VERSION ""

NS_ :

BS_:

BU_: VT TC Sprayer TECU

BO_ 2565340800 VT21_Sprayer: 33 Sprayer
 SG_ UnsupportedVtFunction m253 : 8|8@1+ (1,0) [0|255] "" Vector__XXX
 SG_ AuxiliaryInputID_1 m34 : 120|16@1+ (1,0) [0|65535] "" Vector__XXX
 SG_ AuxiliaryFunctionID_1 m34 : 104|16@1+ (1,0) [0|65535] "" Vector__XXX
 SG_ NumOfPreferredFunctions m34 : 96|8@1- (1,0) [0|255] "" Vector__XXX
 SG_ ModelIdentificationCode m34 : 80|16@1+ (1,0) [0|65535] "" Vector__XXX
 SG_ ArbitraryAddressCapable m34 : 79|1@1+ (1,0) [0|1] "" Vector__XXX
 SG_ IndustryGroup m34 : 76|3@1+ (1,0) [0|7] "" Vector__XXX
 SG_ VehicleSystemInstance m34 : 72|4@1+ (1,0) [0|15] "" Vector__XXX
 SG_ VehicleSystem2 m34 : 65|7@1+ (1,0) [0|127] "" Vector__XXX
 SG_ ZoomValue_PanZoom m16 : 64|32@1- (1,0) [-32|32] "" Vector__XXX
 SG_ OperatingState2 m33 : 57|1@1+ (1,0) [0|1] "" Vector__XXX
 SG_ Function m34 : 56|8@1+ (1,0) [0|255] "" Vector__XXX
 SG_ OperatingState1 m33 : 56|1@1+ (1,0) [0|1] "" Vector__XXX
 SG_ YPosChangeTopLeftLong m180 : 56|16@1- (1,0) [-32768|32767] "" Vector__XXX
 SG_ LineDirection m169 : 56|8@1+ (1,0) [0|1] "" Vector__XXX
 SG_ FunctionInstance m34 : 51|5@1+ (1,0) [0|31] "" Vector__XXX
 SG_ ECUInstance m34 : 48|3@1+ (1,0) [0|7] "" Vector__XXX
 SG_ NewValueY m182 : 48|16@1+ (1,0) [0|65535] "" Vector__XXX
 SG_ GraphicRepresentationObjectID m181 : 48|16@1+ (1,0) [0|255] "" Vector__XXX
 SG_ FontStyle m170 : 48|8@1+ (1,0) [0|255] "" Vector__XXX
 SG_ YPosChangeTopLeft m165 : 48|8@1+ (1,-127) [-127|128] "" Vector__XXX
 SG_ OffTimeDuration_Audio m163 : 48|16@1+ (1,0) [0|65535] "ms" Vector__XXX
 SG_ ButtonKeyCode m1 : 48|8@1+ (1,0) [0|255] "" Vector__XXX
 SG_ SoftKeyCode m0 : 48|8@1+ (1,0) [0|255] "" Vector__XXX
 SG_ Status_2 m9 : 48|8@1+ (1,0) [0|1] "" Vector__XXX
 SG_ NewViewportHeight m17 : 48|16@1+ (1,0) [0|65535] "" Vector__XXX
 SG_ ViewportY_PanZoom m16 : 48|16@1- (1,0) [-32768|32767] "" Vector__XXX
 SG_ ViewportY m14 : 48|16@1- (1,0) [-32768|32767] "" Vector__XXX
 SG_ EllipseHeight m11 : 48|16@1+ (1,0) [0|65535] "" Vector__XXX
 SG_ RectangleHeight_Draw m10 : 48|16@1+ (1,0) [0|65535] "" Vector__XXX
 SG_ EndPixelOffsetY m9 : 48|16@1- (1,0) [-32768|32767] "" Vector__XXX
 SG_ PixelOffsetY m8 : 48|16@1- (1,0) [-32768|32767] "" Vector__XXX
 SG_ CursorOffsetY m1 : 48|16@1- (1,0) [-32768|32767] "" Vector__XXX
 SG_ CursorPosY m0 : 48|16@1- (1,0) [-32768|32767] "" Vector__XXX
 SG_ NewStringValue m179 : 40|16@1+ (1,0) [0|65535] "" Vector__XXX
 SG_ Value2 m33 : 40|16@1+ (1,0) [0|65535] "" Vector__XXX
 SG_ NewHeigthAttribute m183 : 40|16@1+ (1,0) [0|0] "" Vector__XXX
 SG_ FontType m170 : 40|8@1+ (1,0) [0|255] "" Vector__XXX
 SG_ XPosChangeTopLeftLong m180 : 40|16@1- (1,0) [-32768|32767] "" Vector__XXX
 SG_ FillPatternObjectID m172 : 40|16@1+ (1,0) [0|65535] "" Vector__XXX
 SG_ LineArt m171 : 40|16@1+ (1,0) [0|65535] "" Vector__XXX
 SG_ LabelFontType m181 : 40|8@1+ (1,0) [0|255] "" Vector__XXX
 SG_ Height m169 : 40|16@1+ (1,0) [0|65535] "" Vector__XXX
 SG_ NewHeight m166 : 40|16@1+ (1,0) [0|65535] "" Vector__XXX
 SG_ XPosChangeTopLeft m165 : 40|8@1+ (1,-127) [-127|128] "" Vector__XXX
 SG_ TouchState m2 : 40|8@1+ (1,0) [0|255] "" Vector__XXX
 SG_ TextLength m13 : 40|8@1+ (1,0) [0|255] "bytes" Vector__XXX
 SG_ ManufacturerCode m34 : 37|11@1+ (1,0) [0|2047] "" Vector__XXX
 SG_ AuxErrorAnyOther m37 : 33|1@1+ (1,0) [0|1] "" Vector__XXX
 SG_ CursorPosX m0 : 32|16@1- (1,0) [-32768|32767] "" Vector__XXX
 SG_ CursorOffsetX m1 : 32|16@1- (1,0) [-32768|32767] "" Vector__XXX
 SG_ ForegroundColour m2 : 32|8@1+ (1,0) [0|255] "" Vector__XXX
 SG_ BackgroundColour m3 : 32|8@1+ (1,0) [0|255] "" Vector__XXX
 SG_ LineAttributesObjectID m4 : 32|16@1+ (1,0) [0|65535] "" Vector__XXX
 SG_ FillAttributesObjectID m5 : 32|16@1+ (1,0) [0|65535] "" Vector__XXX
 SG_ FontAttributesObjectID m6 : 32|16@1+ (1,0) [0|65535] "" Vector__XXX
 SG_ RectangleWidth_Erase m7 : 32|16@1+ (1,0) [0|65535] "" Vector__XXX
 SG_ RectangleHeight_Erase m7 : 48|16@1+ (1,0) [0|65535] "" Vector__XXX
 SG_ PixelOffsetX m8 : 32|16@1- (1,0) [-32768|32767] "" Vector__XXX
 SG_ EndPixelOffsetX m9 : 32|16@1- (1,0) [-32768|32767] "" Vector__XXX
 SG_ RectangleWidth_Draw m10 : 32|16@1+ (1,0) [0|65535] "" Vector__XXX
 SG_ EllipseWidth m11 : 32|16@1+ (1,0) [0|65535] "" Vector__XXX
 SG_ NumberOfPoints m12 : 32|8@1+ (1,0) [0|255] "" Vector__XXX
 SG_ TextOption m13 : 32|8@1+ (1,0) [0|1] "" Vector__XXX
 SG_ ViewportX m14 : 32|16@1- (1,0) [-32768|32767] "" Vector__XXX
 SG_ ZoomValue m15 : 32|32@1- (1,0) [-32|32] "" Vector__XXX
 SG_ ViewportX_PanZoom m16 : 32|16@1- (1,0) [-32768|32767] "" Vector__XXX
 SG_ NewViewportWidth m17 : 32|16@1+ (1,0) [0|65535] "" Vector__XXX
 SG_ ObjectID m18 : 32|16@1+ (1,0) [0|65534] "" Vector__XXX
 SG_ PictureGraphicsID_Canvas m19 : 32|16@1+ (1,0) [0|65534] "" Vector__XXX
 SG_ PictureGraphicsID_Viewport m20 : 32|16@1+ (1,0) [0|65534] "" Vector__XXX
 SG_ LastWideChar m193 : 32|16@1+ (1,0) [0|65535] "" Vector__XXX
 SG_ LockTimeout m189 : 32|16@1+ (1,0) [0|65535] "" Vector__XXX
 SG_ NewValueX m182 : 32|16@1+ (1,0) [0|65535] "" Vector__XXX
 SG_ NewObjectID m177 : 32|16@1+ (1,0) [0|65535] "" Vector__XXX
 SG_ NewAttributeValue m175 : 32|32@1+ (1,0) [0|0] "" Vector__XXX
 SG_ NewSoftKeyMaskObjectID m174 : 32|16@1+ (1,0) [0|65535] "" Vector__XXX
 SG_ FillColour m172 : 32|8@1+ (1,0) [0|255] "" Vector__XXX
 SG_ LineWidth m171 : 32|8@1+ (1,0) [0|255] "" Vector__XXX
 SG_ FontSize m170 : 32|8@1+ (1,0) [0|255] "" Vector__XXX
 SG_ NewValue m168 : 32|32@1+ (1,0) [0|65535] "" Vector__XXX
 SG_ OnTimeDuration_Audio m163 : 32|16@1+ (1,0) [0|65535] "ms" Vector__XXX
 SG_ AuxErrorInvalidInputID m37 : 32|1@1+ (1,0) [0|1] "" Vector__XXX
 SG_ VTChangeNumericValueValue m5 : 32|32@1+ (1,0) [0|4294967295] "" Vector__XXX
 SG_ ButtonObjectParentID m1 : 32|16@1+ (1,0) [0|65535] "" Vector__XXX
 SG_ KeyObjectParentID m0 : 32|16@1+ (1,0) [0|65535] "" Vector__XXX
 SG_ ObjectId_2 m9 : 32|16@1+ (1,0) [0|65535] "" Vector__XXX
 SG_ Value1 m33 : 24|16@1+ (1,0) [0|65535] "" Vector__XXX
 SG_ TotalNumberOfBytes m179 : 24|16@1- (1,0) [0|0] "bytes" Vector__XXX
 SG_ AttributeIDToChange m175 : 24|8@1+ (1,0) [0|0] "" Vector__XXX
 SG_ SubCommandID m184M : 24|8@1+ (1,0) [0|0] "" Vector__XXX
 SG_ NewWidthAttribute m183 : 24|16@1+ (1,0) [0|65535] "" Vector__XXX
 SG_ IndexOfThePointToReplace m182 : 24|8@1+ (1,0) [0|255] "" Vector__XXX
 SG_ StringVariableObjectID m181 : 24|16@1+ (1,0) [0|65535] "" Vector__XXX
 SG_ ChangeChildLocationObjectID m165 : 24|16@1+ (1,0) [0|65535] "" Vector__XXX
 SG_ ListIndex m177 : 24|8@1+ (1,0) [0|255] "" Vector__XXX
 SG_ NewPriority m176 : 24|8@1+ (1,0) [0|255] "" Vector__XXX
 SG_ AttributeID m185 : 24|8@1+ (1,0) [0|16777200] "" Vector__XXX
 SG_ NewActiveMaskObjectID m173 : 24|16@1+ (1,0) [0|65535] "" Vector__XXX
 SG_ FillType m172 : 24|8@1+ (1,0) [0|255] "" Vector__XXX
 SG_ LineColour m171 : 24|8@1+ (1,0) [0|255] "" Vector__XXX
 SG_ FontColour m170 : 24|8@1+ (1,0) [0|255] "" Vector__XXX
 SG_ Width m169 : 24|16@1+ (1,0) [0|65535] "" Vector__XXX
 SG_ NewBackgroundColour m167 : 24|8@1+ (1,0) [0|255] "" Vector__XXX
 SG_ NewWidth m166 : 24|16@1+ (1,0) [0|65535] "" Vector__XXX
 SG_ ChangeChildPositionObjectID m180 : 24|16@1+ (1,0) [0|65535] "" Vector__XXX
 SG_ SetFocusOpenForEditing m162 : 24|8@1+ (1,0) [0|255] "" Vector__XXX
 SG_ EnableOrDisable m161 : 24|8@1+ (1,0) [0|1] "" Vector__XXX
 SG_ ShowOrHide m160 : 24|8@1+ (1,0) [0|1] "" Vector__XXX
 SG_ AuxInputEnable m37 : 24|8@1+ (1,0) [0|1] "" Vector__XXX
 SG_ AssignmentErrorNotAccepted m36 : 24|1@1+ (1,0) [0|1] "" Vector__XXX
 SG_ ObjectOfChangedStringValueID m8 : 24|16@1+ (1,0) [0|65535] "" Vector__XXX
 SG_ VTChangeSoftKeyMaskObjectID m7 : 24|16@1+ (1,0) [0|65535] "" Vector__XXX
 SG_ VTSelectInputObjectStatus m3 : 24|8@1+ (1,0) [0|1] "" Vector__XXX
 SG_ YPosition m2 : 24|16@1+ (1,0) [0|65535] "" Vector__XXX
 SG_ AuxiliaryFunctionID m32 : 24|16@1+ (1,0) [0|65535] "" Vector__XXX
 SG_ Status_1 m9 : 24|8@1+ (1,0) [0|1] "" Vector__XXX
 SG_ IdentityNumber m34 : 16|21@1+ (1,0) [0|2097152] "" Vector__XXX
 SG_ FirstWideChar m193 : 16|16@1+ (1,0) [0|65535] "" Vector__XXX
 SG_ MemoryRequired m192 : 16|32@1+ (1,0) [0|4294967295] "" Vector__XXX
 SG_ ObjectIDOfDataMaskToLock m189 : 16|16@1+ (1,0) [0|65535] "" Vector__XXX
 SG_ DataOrAlarmMaskObjectID m174 : 16|16@1+ (1,0) [0|65535] "" Vector__XXX
 SG_ Frequency_Audio m163 : 16|16@1+ (1,0) [0|65535] "hz" Vector__XXX
 SG_ ButtonObjectID m1 : 16|16@1+ (1,0) [0|65535] "" Vector__XXX
 SG_ KeyObjectID m0 : 16|16@1+ (1,0) [0|65535] "" Vector__XXX
 SG_ WSMaintenanceVersion m255M : 16|8@1+ (1,0) [0|255] "" Vector__XXX
 SG_ AuxiliaryInputNumber m32 : 16|8@1+ (1,0) [0|255] "" Vector__XXX
 SG_ ExtendedVersionLabelToDelete m214 : 8|256@1+ (1,0) [0|3338120000] "" Vector__XXX
 SG_ ExtendedVersionLabelToLoad m213 : 8|256@1+ (1,0) [0|3338120000] "" Vector__XXX
 SG_ ExtendedVersionLabelToStore m212 : 8|256@1+ (1,0) [0|3338120000] "" Vector__XXX
 SG_ MacroObjectID_2 m188 : 8|16@1+ (1,0) [0|65535] "" Vector__XXX
 SG_ AuxCapabilitiesRequestType m39 : 8|8@1+ (1,0) [0|255] "" Vector__XXX
 SG_ WSMaintenanceInitiating m3 : 8|1@1+ (1,0) [0|1] "" Vector__XXX
 SG_ VersionLabelToDelete m210 : 8|56@1+ (1,0) [0|3338120000] "" Vector__XXX
 SG_ VersionLabelToLoad m209 : 8|56@1+ (1,0) [0|3338120000] "" Vector__XXX
 SG_ VersionLabelToStore m208 : 8|56@1+ (1,0) [0|3338120000] "" Vector__XXX
 SG_ CodePlane m193 : 8|8@1+ (1,0) [0|16] "" Vector__XXX
 SG_ MacroObjectID m190 : 8|8@1+ (1,0) [0|255] "" Vector__XXX
 SG_ LockUnlockCommand m189 : 8|8@1+ (1,0) [0|1] "" Vector__XXX
 SG_ ColourMapObjectID m186 : 8|16@1+ (1,0) [0|65535] "" Vector__XXX
 SG_ ObjectToGetAttributeID m185 : 8|16@1+ (1,0) [0|65535] "" Vector__XXX
 SG_ GraphicsContextObjectID m184 : 8|16@1+ (1,0) [0|65535] "" Vector__XXX
 SG_ PolygonObjectToScaleID m183 : 8|16@1+ (1,0) [0|65535] "" Vector__XXX
 SG_ PolygonObjectToChangeID m182 : 8|16@1+ (1,0) [0|65535] "" Vector__XXX
 SG_ ObjectToAssociateLabelWithID m181 : 8|16@1+ (1,0) [0|65535] "" Vector__XXX
 SG_ ParentObjectID m8 : 8|16@1+ (1,0) [0|65535] "" Vector__XXX
 SG_ ObjectToChangeStringValueID m179 : 8|16@1+ (1,0) [0|65535] "" Vector__XXX
 SG_ ListInputObjectID m177 : 8|16@1+ (1,0) [0|65535] "" Vector__XXX
 SG_ AlarmMaskObjectID m176 : 8|16@1+ (1,0) [0|65535] "" Vector__XXX
 SG_ ObjectToChangeAttributeID m175 : 8|16@1+ (1,0) [0|65535] "" Vector__XXX
 SG_ MaskType m174 : 8|8@1+ (1,0) [0|255] "" Vector__XXX
 SG_ WorkingSetObjectID m173 : 8|16@1+ (1,0) [0|65535] "" Vector__XXX
 SG_ ObjectToChangeFillAttributesID m172 : 8|16@1+ (1,0) [0|65535] "" Vector__XXX
 SG_ ObjectToChangeLineAttributesID m171 : 8|16@1+ (1,0) [0|65535] "" Vector__XXX
 SG_ ObjectToChangeFontID m170 : 8|16@1+ (1,0) [0|65535] "" Vector__XXX
 SG_ ObjectToChangeEndPointID m169 : 8|16@1+ (1,0) [0|65535] "" Vector__XXX
 SG_ ObjectToChangeNumValueID m168 : 8|16@1+ (1,0) [0|65535] "" Vector__XXX
 SG_ ObjectToChangeColourID m167 : 8|16@1+ (1,0) [0|65535] "" Vector__XXX
 SG_ ObjectToSizeID m166 : 8|16@1+ (1,0) [0|65535] "" Vector__XXX
 SG_ ChangeChildLocationParentOb_0000 m165 : 8|16@1+ (1,0) [0|65535] "" Vector__XXX
 SG_ AudioVolume m164 : 8|8@1+ (1,0) [0|100] "%" Vector__XXX
 SG_ NumberOfRepetitions_Audio m163 : 8|8@1+ (1,0) [0|255] "" Vector__XXX
 SG_ SelectInputObjectID m162 : 8|16@1+ (1,0) [0|65535] "" Vector__XXX
 SG_ ObjectoEnableDisbaleID m161 : 8|16@1+ (1,0) [0|65535] "" Vector__XXX
 SG_ ObjectToShowHideID m160 : 8|16@1+ (1,0) [0|65535] "" Vector__XXX
 SG_ InputStatusObjectId m37 : 8|16@1+ (1,0) [0|255] "" Vector__XXX
 SG_ AuxModelIdentification m35 : 8|16@1+ (1,0) [0|65535] "" Vector__XXX
 SG_ NumberOfInpuUnits m34 : 8|8@1+ (1,0) [0|255] "" Vector__XXX
 SG_ AuxiliaryFunctionObjectID m36 : 8|16@1+ (1,0) [0|65535] "" Vector__XXX
 SG_ ObjectPoolRecord m17 : 8|56@1+ (1,0) [0|3338120000] "" Vector__XXX
 SG_ ChangeChildPositionParentOb_0000 m180 : 8|16@1+ (1,0) [0|65535] "" Vector__XXX
 SG_ VTChangeSoftKeyMaskParentID m7 : 8|16@1+ (1,0) [0|65535] "" Vector__XXX
 SG_ VTChangeActiveMaskObjectID m6 : 8|16@1+ (1,0) [0|65535] "" Vector__XXX
 SG_ VTChangeNumericValueObjectID m5 : 8|16@1+ (1,0) [0|65535] "" Vector__XXX
 SG_ VTEscObjectID m4 : 8|16@1+ (1,0) [0|65535] "" Vector__XXX
 SG_ VTSelectInputObjectID m3 : 8|16@1+ (1,0) [0|65535] "" Vector__XXX
 SG_ XPosition m2 : 8|16@1+ (1,0) [0|65535] "" Vector__XXX
 SG_ ButtonActivationCode m1 : 8|8@1+ (1,0) [0|2] "" Vector__XXX
 SG_ KeyActivationCode m0 : 8|8@1+ (1,0) [0|2] "" Vector__XXX
 SG_ InputObjectId m33 : 8|16@1+ (1,0) [0|255] "" Vector__XXX
 SG_ SourceAddressOfAuxiliaryInputDev m32 : 8|8@1+ (1,0) [0|255] "" Vector__XXX
 SG_ ObjectId_1 m9 : 8|16@1+ (1,0) [0|65535] "" Vector__XXX
 SG_ VTFunctionECUtoVT M : 0|8@1+ (1,0) [0|255] "" Vector__XXX

BO_ 2565799552 ACL_Sprayer: 8 Sprayer
 SG_ ArbitraryAddressCapable : 63|1@1+ (1,0) [0|1] "" Vector__XXX
 SG_ IndustryGroup M : 60|3@1+ (1,0) [0|7] "" Vector__XXX
 SG_ VehicleSystemInstance : 56|4@1+ (1,0) [0|15] "" Vector__XXX
 SG_ VehicleSystem m0 : 49|7@1+ (1,0) [0|127] "" Vector__XXX
 SG_ VehicleSystem5 m5 : 49|7@1+ (1,0) [0|127] "" Vector__XXX
 SG_ VehicleSystem4 m4 : 49|7@1+ (1,0) [0|127] "" Vector__XXX
 SG_ VehicleSystem3 m3 : 49|7@1+ (1,0) [0|127] "" Vector__XXX
 SG_ VehicleSystem2 m2 : 49|7@1+ (1,0) [0|127] "" Vector__XXX
 SG_ VehicleSystem1 m1 : 49|7@1+ (1,0) [0|127] "" Vector__XXX
 SG_ Function : 40|8@1+ (1,0) [0|255] "" Vector__XXX
 SG_ FunctionInstance : 35|5@1+ (1,0) [0|31] "" Vector__XXX
 SG_ ECUInstance : 32|3@1+ (1,0) [0|7] "" Vector__XXX
 SG_ ManufacturerCode : 21|11@1+ (1,0) [0|2047] "" Vector__XXX
 SG_ IdentityNumber : 0|21@1+ (1,0) [0|2097152] "" Vector__XXX

BO_ 2365475073 GBSD_TECU: 8 TECU
 SG_ GroundBasedMachineDirection : 56|2@1+ (1,0) [0|3] "" Vector__XXX
 SG_ GroundBasedMachineDistance : 16|32@1+ (0.001,0) [0|4211080] "m" Vector__XXX
 SG_ GroundBasedMachineSpeed : 0|16@1+ (0.001,0) [0|64.255] "m/s" Vector__XXX

BO_ 2364597502 HB: 1 Vector__XXX
 SG_ HeartbeatSequenceNumber : 0|8@1+ (1,0) [0|0] "" Vector__XXX

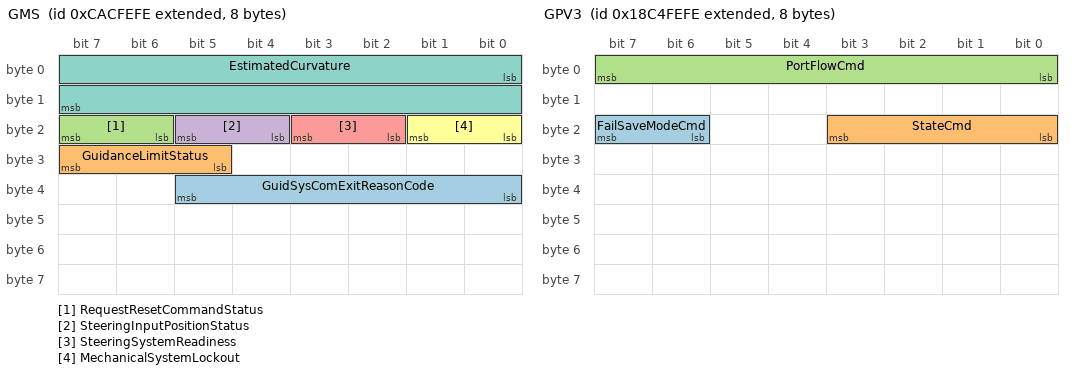
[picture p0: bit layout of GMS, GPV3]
BO_ 2360147710 GMS: 8 Vector__XXX
 SG_ GuidSysComExitReasonCode : 32|6@1+ (1,0) [0|63] "" Vector__XXX
 SG_ GuidanceLimitStatus : 29|3@1+ (1,0) [0|7] "" Vector__XXX
 SG_ RequestResetCommandStatus : 22|2@1+ (1,0) [0|3] "" Vector__XXX
 SG_ SteeringInputPositionStatus : 20|2@1+ (1,0) [0|3] "" Vector__XXX
 SG_ SteeringSystemReadiness : 18|2@1+ (1,0) [0|3] "" Vector__XXX
 SG_ MechanicalSystemLockout : 16|2@1+ (1,0) [0|3] "" Vector__XXX
 SG_ EstimatedCurvature : 0|16@1+ (0.25,-8032) [-8032|8031.75] "1/km" Vector__XXX

BO_ 2360213246 GSC: 8 Vector__XXX
 SG_ CurvatureCommandStatus : 16|2@1+ (1,0) [0|3] "" Vector__XXX
 SG_ CurvatureCommand : 0|16@1+ (0.25,-8032) [-8032|8031.75] "1/km" Vector__XXX

BO_ 2563047166 GPV3: 8 Vector__XXX
 SG_ FailSaveModeCmd : 22|2@1+ (1,0) [0|3] "" Vector__XXX
 SG_ StateCmd : 16|4@1+ (1,0) [0|15] "" Vector__XXX
 SG_ PortFlowCmd : 0|8@1+ (0.4,0) [0|100] "%" Vector__XXX

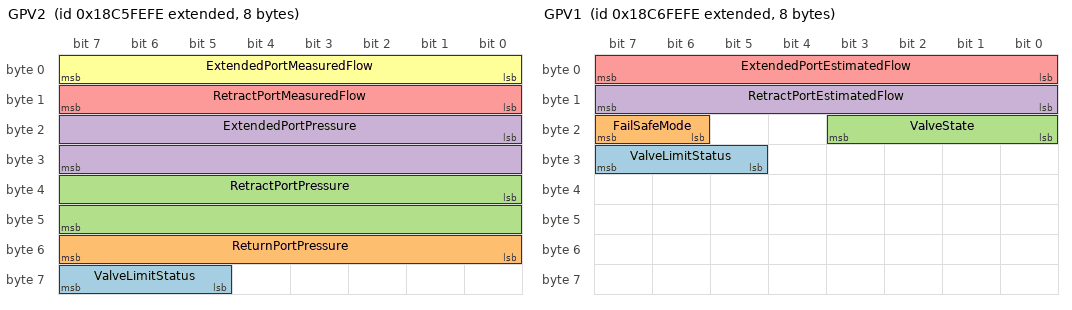
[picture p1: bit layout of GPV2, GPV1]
BO_ 2563112702 GPV2: 8 Vector__XXX
 SG_ ValveLimitStatus : 61|3@1+ (1,0) [0|7] "" Vector__XXX
 SG_ ReturnPortPressure : 48|8@1+ (16,0) [0|4000] "kPa" Vector__XXX
 SG_ RetractPortPressure : 32|16@1+ (5,0) [0|321275] "kPa" Vector__XXX
 SG_ ExtendedPortPressure : 16|16@1+ (5,0) [0|321275] "kPa" Vector__XXX
 SG_ RetractPortMeasuredFlow : 8|8@1+ (1,-125) [-125|125] "%" Vector__XXX
 SG_ ExtendedPortMeasuredFlow : 0|8@1+ (1,-125) [-125|125] "%" Vector__XXX

BO_ 2563178238 GPV1: 8 Vector__XXX
 SG_ ValveLimitStatus : 29|3@1+ (1,0) [0|7] "" Vector__XXX
 SG_ FailSafeMode : 22|2@1+ (1,0) [0|3] "" Vector__XXX
 SG_ ValveState : 16|4@1+ (1,0) [0|15] "" Vector__XXX
 SG_ RetractPortEstimatedFlow : 8|8@1+ (1,-125) [-125|125] "%" Vector__XXX
 SG_ ExtendedPortEstimatedFlow : 0|8@1+ (1,-125) [-125|125] "%" Vector__XXX

BO_ 2628452094 FSClient: 9 Vector__XXX
 SG_ VI_VolumeName m64 : 56|16@1+ (1,0) [0|65535] "" Vector__XXX
 SG_ VI_Flag_OverwriteExisting m64 : 48|1@1+ (1,0) [0|1] "" Vector__XXX
 SG_ MF_DestinationPathNameLength m48 : 40|16@1+ (1,0) [0|65535] "" Vector__XXX
 SG_ RF_ReportHiddenFiles m34 : 40|8@1+ (1,0) [0|255] "" Vector__XXX
 SG_ SF_Offset m33 : 32|32@1- (1,0) [-2147483648|2147483647] "" Vector__XXX
 SG_ RF_Count m34 : 24|16@1+ (1,0) [0|65535] "" Vector__XXX
 SG_ SF_PositionMode m33 : 24|8@1+ (1,0) [0|255] "" Vector__XXX
 SG_ OF_PathName m32 : 24|16@1+ (1,0) [0|65535] "" Vector__XXX
 SG_ MF_SourcePathNameLength m48 : 24|16@1+ (1,0) [0|65535] "" Vector__XXX
 SG_ WF_Count m35 : 24|16@1+ (1,0) [0|65535] "" Vector__XXX
 SG_ DF_PathName m49 : 24|16@1+ (1,0) [0|65535] "" Vector__XXX
 SG_ SA_PathName m51 : 24|16@1+ (1,0) [0|65535] "" Vector__XXX
 SG_ VI_Space m64 : 16|32@1+ (1,0) [0|4294967295] "" Vector__XXX
 SG_ OF_FlagExclusiveAccess m32 : 20|1@1+ (1,0) [0|1] "" Vector__XXX
 SG_ OF_FlagAppend m32 : 19|1@1+ (1,0) [0|1] "" Vector__XXX
 SG_ SET_ATTR_Hidden m51 : 18|2@1+ (1,0) [0|3] "" Vector__XXX
 SG_ OF_FlagCreateNew m32 : 18|1@1+ (1,0) [0|1] "" Vector__XXX
 SG_ MF_MoveModeRecursive m48 : 18|1@1+ (1,0) [0|1] "" Vector__XXX
 SG_ DF_DeleteModeRecursive m49 : 18|1@1+ (1,0) [0|1] "" Vector__XXX
 SG_ MF_MoveModeForce m48 : 17|1@1+ (1,0) [0|1] "" Vector__XXX
 SG_ DF_DeleteModeForce m49 : 17|1@1+ (1,0) [0|1] "" Vector__XXX
 SG_ VI_Flag_UsingSpaceSpecified m64 : 49|1@1+ (1,0) [0|1] "" Vector__XXX
 SG_ SET_ATTR_ReadOnly m51 : 16|2@1+ (1,0) [0|3] "" Vector__XXX
 SG_ CF_Handle m36 : 16|8@1+ (1,0) [0|255] "" Vector__XXX
 SG_ WF_Handle m35 : 16|8@1+ (1,0) [0|255] "" Vector__XXX
 SG_ RF_Handle m34 : 16|8@1+ (1,0) [0|255] "" Vector__XXX
 SG_ SF_Handle m33 : 16|8@1+ (1,0) [0|255] "" Vector__XXX
 SG_ OF_FlagReadWrite m32 : 16|2@1+ (1,0) [0|3] "" Vector__XXX
 SG_ CCD_PathName m17 : 16|16@1+ (1,0) [0|65535] "" Vector__XXX
 SG_ MF_MoveModeCopy m48 : 16|1@1+ (1,0) [0|1] "" Vector__XXX
 SG_ DF_DeleteMode m49 : 16|1@1+ (1,0) [0|1] "" Vector__XXX
 SG_ GA_PathName m50 : 16|16@1+ (1,0) [0|65535] "" Vector__XXX
 SG_ FDT_PathName m52 : 16|16@1+ (1,0) [0|65535] "" Vector__XXX
 SG_ VS_VolumeName m2 : 16|16@1+ (1,0) [0|0] "" Vector__XXX
 SG_ VS_RequestVolumeToPrepareForRemo m2 : 9|1@1- (1,0) [0|1] "" Vector__XXX
 SG_ CCD_TAN m17 : 8|8@1+ (1,0) [0|255] "" Vector__XXX
 SG_ GCD_TAN m16 : 8|8@1+ (1,0) [0|255] "" Vector__XXX
 SG_ FDT_TAN m52 : 8|8@1+ (1,0) [0|255] "" Vector__XXX
 SG_ SA_TAN m51 : 8|8@1+ (1,0) [0|255] "" Vector__XXX
 SG_ GA_TAN m50 : 8|8@1+ (1,0) [0|255] "" Vector__XXX
 SG_ RF_TAN m34 : 8|8@1+ (1,0) [0|255] "" Vector__XXX
 SG_ CF_TAN m36 : 8|8@1+ (1,0) [0|255] "" Vector__XXX
 SG_ WF_TAN m35 : 8|8@1+ (1,0) [0|255] "" Vector__XXX
 SG_ SF_TAN m33 : 8|8@1+ (1,0) [0|255] "" Vector__XXX
 SG_ OF_TAN m32 : 8|8@1+ (1,0) [0|255] "" Vector__XXX
 SG_ MF_TAN m48 : 8|8@1+ (1,0) [0|255] "" Vector__XXX
 SG_ DF_TAN m49 : 8|8@1+ (1,0) [0|255] "" Vector__XXX
 SG_ VI_TAN m64 : 8|8@1+ (1,0) [0|255] "" Vector__XXX
 SG_ VS_ReportVolumeUsedByClient m2 : 8|1@1+ (1,0) [0|1] "" Vector__XXX
 SG_ CM_VersionNumber m0 : 8|8@1+ (1,0) [0|255] "" Vector__XXX
 SG_ FSClientCommand M : 0|8@1+ (1,0) [0|255] "" Vector__XXX

BO_ 2628517630 FSServer: 35 Vector__XXX
 SG_ GCD_PathName m16 : 88|16@1+ (1,0) [0|65535] "" Vector__XXX
 SG_ GCD_FreeSpace m16 : 56|32@1+ (512,0) [0|4294966744] "Bytes" Vector__XXX
 SG_ FDT_TimeHour m52 : 51|5@1+ (1,0) [0|23] "Hour" Vector__XXX
 SG_ FDT_TimeMinutes m52 : 45|6@1+ (1,0) [0|59] "Minutes" Vector__XXX
 SG_ FDT_TimeSeconds m52 : 40|5@1+ (2,0) [0|58] "Seconds" Vector__XXX
 SG_ OF_ATTR_VolumeIsCaseSensitive m32 : 39|1@1+ (1,0) [0|1] "" Vector__XXX
 SG_ OF_ATTR_VolumeRemovable m32 : 38|1@1+ (1,0) [0|1] "" Vector__XXX
 SG_ OF_ATTR_SupportsLongFilenames m32 : 37|1@1+ (1,0) [0|1] "" Vector__XXX
 SG_ OF_ATTR_Directory m32 : 36|1@1+ (1,0) [0|1] "" Vector__XXX
 SG_ OF_ATTR_IsVolume m32 : 35|1@1+ (1,0) [0|1] "" Vector__XXX
 SG_ FDT_DateYear m52 : 33|7@1+ (1,1980) [1980|2107] "Year" Vector__XXX
 SG_ OF_ATTR_Hidden m32 : 33|1@1+ (1,0) [0|1] "" Vector__XXX
 SG_ SF_Position m33 : 32|32@1+ (1,0) [0|4294967295] "" Vector__XXX
 SG_ OF_ATTR_ReadOnly m32 : 32|1@1+ (1,0) [0|1] "" Vector__XXX
 SG_ GA_Size m50 : 32|32@1+ (1,0) [0|4294967295] "" Vector__XXX
 SG_ VS_VolumeName m2 : 32|16@1+ (1,0) [0|65535] "" Vector__XXX
 SG_ VI_VolumeIsCaseSensitive m64 : 31|1@1+ (1,0) [0|1] "" Vector__XXX
 SG_ GA_ATTR_VolumeIsCaseSensitive m50 : 31|1@1+ (1,0) [0|1] "" Vector__XXX
 SG_ VI_ATTR_VolumeRemovable m64 : 30|1@1+ (1,0) [0|1] "" Vector__XXX
 SG_ GA_ATTR_VolumeRemovable m50 : 30|1@1+ (1,0) [0|1] "" Vector__XXX
 SG_ VI_ATTR_SupportsLongFilenames m64 : 29|1@1+ (1,0) [0|1] "" Vector__XXX
 SG_ FDT_DateMonth m52 : 29|4@1+ (1,0) [0|12] "Month" Vector__XXX
 SG_ GA_ATTR_SupportsLongFilenames m50 : 29|1@1+ (1,0) [0|1] "" Vector__XXX
 SG_ GA_ATTR_Directory m50 : 28|1@1+ (1,0) [0|1] "" Vector__XXX
 SG_ VI_ATTR_Directory m64 : 28|1@1+ (1,0) [0|1] "" Vector__XXX
 SG_ VI_ATTR_IsVolume m64 : 27|1@1+ (1,0) [0|1] "" Vector__XXX
 SG_ GA_ATTR_IsVolume m50 : 27|1@1+ (1,0) [0|1] "" Vector__XXX
 SG_ VI_ATTR_VolSupportsHiddenAttr m64 : 26|1@1+ (1,0) [0|1] "" Vector__XXX
 SG_ GA_ATTR_VolSupportsHiddenAttr m50 : 26|1@1+ (1,0) [0|1] "" Vector__XXX
 SG_ VI_ATTR_Hidden m64 : 25|1@1+ (1,0) [0|1] "" Vector__XXX
 SG_ GA_ATTR_Hidden m50 : 25|1@1+ (1,0) [0|1] "" Vector__XXX
 SG_ VI_ATTR_ReadOnly m64 : 24|1@1+ (1,0) [0|1] "" Vector__XXX
 SG_ FDT_DateDay m52 : 24|5@1+ (1,0) [0|31] "Day" Vector__XXX
 SG_ GA_ATTR_ReadOnly m50 : 24|1@1+ (1,0) [0|1] "" Vector__XXX
 SG_ OF_Handle m32 : 24|8@1+ (1,0) [0|255] "" Vector__XXX
 SG_ GCD_TotalSpace m16 : 24|32@1+ (512,0) [0|4294966744] "Bytes" Vector__XXX
 SG_ RF_Count m34 : 24|16@1+ (1,0) [0|65535] "Bytes" Vector__XXX
 SG_ GSP_SupportMultipleVolumes m1 : 24|1@1+ (1,0) [0|255] "" Vector__XXX
 SG_ WF_Count m35 : 24|16@1+ (1,0) [0|65535] "" Vector__XXX
 SG_ VS_ErrorCode m2 : 24|8@1+ (1,0) [0|255] "" Vector__XXX
 SG_ FDT_ErrorCode m52 : 16|8@1+ (1,0) [0|255] "" Vector__XXX
 SG_ RF_ErrorCode m34 : 16|8@1+ (1,0) [0|255] "" Vector__XXX
 SG_ SF_ErrorCode m33 : 16|8@1+ (1,0) [0|255] "" Vector__XXX
 SG_ FSNumberOfOpenFiles m0 : 16|8@1- (1,0) [0|255] "" Vector__XXX
 SG_ OF_ErrorCode m32 : 16|8@1+ (1,0) [0|255] "" Vector__XXX
 SG_ WF_ErrorCode m35 : 16|8@1+ (1,0) [0|255] "" Vector__XXX
 SG_ CF_ErrorCode m36 : 16|8@1+ (1,0) [0|255] "" Vector__XXX
 SG_ MF_ErrorCode m48 : 16|8@1+ (1,0) [0|255] "" Vector__XXX
 SG_ GA_ErrorCode m50 : 16|8@1+ (1,0) [0|255] "" Vector__XXX
 SG_ SA_ErrorCode m51 : 16|8@1+ (1,0) [0|255] "" Vector__XXX
 SG_ GCD_ErrorCode m16 : 16|8@1+ (1,0) [0|255] "" Vector__XXX
 SG_ CCD_ErrorCode m17 : 16|8@1+ (1,0) [0|255] "" Vector__XXX
 SG_ GSP_MaxNrSimultaneousFilesOpen m1 : 16|8@1+ (1,0) [0|255] "" Vector__XXX
 SG_ DF_ErrorCode m49 : 16|8@1+ (1,0) [0|255] "" Vector__XXX
 SG_ VI_ErrorCode m64 : 16|8@1+ (1,0) [0|255] "" Vector__XXX
 SG_ VS_MaxTimeBeforeVolRemoval m2 : 16|8@1+ (1,0) [0|250] "min/bit" Vector__XXX
 SG_ FSBusyWriting m0 : 9|1@1+ (1,0) [0|1] "" Vector__XXX
 SG_ FSBusyReading m0 : 8|1@1+ (1,0) [0|1] "" Vector__XXX
 SG_ OF_TAN m32 : 8|8@1+ (1,0) [0|255] "" Vector__XXX
 SG_ SF_TAN m33 : 8|8@1+ (1,0) [0|255] "" Vector__XXX
 SG_ RF_TAN m34 : 8|8@1+ (1,0) [0|255] "" Vector__XXX
 SG_ WF_TAN m35 : 8|8@1+ (1,0) [0|255] "" Vector__XXX
 SG_ CF_TAN m36 : 8|8@1+ (1,0) [0|255] "" Vector__XXX
 SG_ MF_TAN m48 : 8|8@1+ (1,0) [0|255] "" Vector__XXX
 SG_ GA_TAN m50 : 8|8@1+ (1,0) [0|255] "" Vector__XXX
 SG_ SA_TAN m51 : 8|8@1+ (1,0) [0|255] "" Vector__XXX
 SG_ FDT_TAN m52 : 8|8@1+ (1,0) [0|255] "" Vector__XXX
 SG_ GCD_TAN m16 : 8|8@1+ (1,0) [0|255] "" Vector__XXX
 SG_ CCD_TAN m17 : 8|8@1+ (1,0) [0|255] "" Vector__XXX
 SG_ GSP_VersionNumber m1 : 8|8@1+ (1,0) [0|255] "" Vector__XXX
 SG_ DF_TAN m49 : 8|8@1+ (1,0) [0|255] "" Vector__XXX
 SG_ VI_TAN m64 : 8|8@1+ (1,0) [0|255] "" Vector__XXX
 SG_ VS_VolumeStatus m2 : 8|8@1+ (1,0) [0|3] "" Vector__XXX
 SG_ FSServerCommand M : 0|8@1+ (1,0) [0|255] "" Vector__XXX

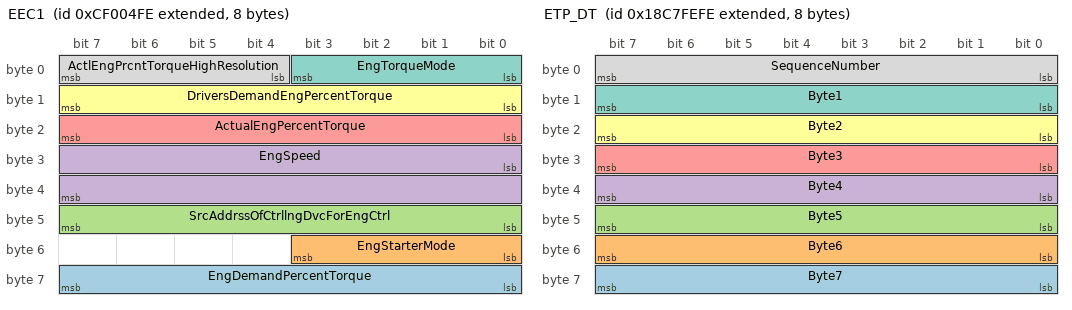
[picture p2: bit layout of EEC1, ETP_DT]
BO_ 2364540158 EEC1: 8 Vector__XXX
 SG_ EngDemandPercentTorque : 56|8@1+ (1,-125) [-125|125] "%" Vector__XXX
 SG_ EngStarterMode : 48|4@1+ (1,0) [0|15] "" Vector__XXX
 SG_ SrcAddrssOfCtrllngDvcForEngCtrl : 40|8@1+ (1,0) [0|255] "" Vector__XXX
 SG_ EngSpeed : 24|16@1+ (0.125,0) [0|8031.875] "rpm" Vector__XXX
 SG_ ActualEngPercentTorque : 16|8@1+ (1,-125) [-125|125] "%" Vector__XXX
 SG_ DriversDemandEngPercentTorque : 8|8@1+ (1,-125) [-125|125] "%" Vector__XXX
 SG_ EngTorqueMode : 0|4@1+ (1,0) [0|15] "" Vector__XXX
 SG_ ActlEngPrcntTorqueHighResolution : 4|4@1+ (0.125,0) [0|0.875] "%" Vector__XXX

BO_ 2563243774 ETP_DT: 8 Vector__XXX
 SG_ Byte7 : 56|8@1+ (1,0) [0|255] "" Vector__XXX
 SG_ Byte6 : 48|8@1+ (1,0) [0|255] "" Vector__XXX
 SG_ Byte5 : 40|8@1+ (1,0) [0|255] "" Vector__XXX
 SG_ Byte4 : 32|8@1+ (1,0) [0|255] "" Vector__XXX
 SG_ Byte3 : 24|8@1+ (1,0) [0|255] "" Vector__XXX
 SG_ Byte2 : 16|8@1+ (1,0) [0|255] "" Vector__XXX
 SG_ Byte1 : 8|8@1+ (1,0) [0|255] "" Vector__XXX
 SG_ SequenceNumber : 0|8@1+ (1,0) [1|255] "" Vector__XXX

BO_ 2563309310 ETP_CM: 8 Vector__XXX
 SG_ PGNumber : 40|24@1+ (1,0) [0|16777200] "" Vector__XXX
 SG_ DataPacketOffset m22 : 16|24@1+ (1,0) [0|16777215] "" Vector__XXX
 SG_ NextPacketNumberToSend m21 : 16|24@1+ (1,0) [1|16777215] "" Vector__XXX
 SG_ NumberOfBytesTransfered m23 : 8|32@1+ (1,0) [1786|117440505] "" Vector__XXX
 SG_ NumberOfPacketsOffset m22 : 8|8@1+ (1,0) [1|255] "" Vector__XXX
 SG_ NumberOfPacketsToSend m21 : 8|8@1+ (1,0) [1|255] "" Vector__XXX
 SG_ NumberOfBytesToTransfer m20 : 8|32@1+ (1,0) [1786|117440505] "" Vector__XXX
 SG_ ControlByte M : 0|8@1+ (1,0) [0|255] "" Vector__XXX
 SG_ ConnectionAbortReason m255 : 8|8@1+ (1,0) [0|255] "" Vector__XXX

BO_ 2314732030 GNSSPositionRapidUpdate: 8 Vector__XXX
 SG_ Longitude : 32|32@1- (1E-007,0) [-180|180] "deg" Vector__XXX
 SG_ Latitude : 0|32@1- (1E-007,0) [-90|90] "deg" Vector__XXX

BO_ 2583168510 GNSSPositionData: 47 Vector__XXX
 SG_ AgeOfDGNSSCorrections1 : 360|16@1+ (0.01,0) [0|655.32] "sec" Vector__XXX
 SG_ ReferenceStationID1 : 348|12@1+ (1,0) [0|4095] "" Vector__XXX
 SG_ RefrenceStationType1 : 344|4@1+ (1,0) [0|15] "" Vector__XXX
 SG_ NumberOfReferenceStations : 336|8@1+ (1,0) [0|252] "" Vector__XXX
 SG_ GeoidalSeparation : 304|32@1- (0.01,0) [-21470000|21470000] "m" Vector__XXX
 SG_ PDOP : 288|16@1- (0.01,0) [-327.64|327.64] "" Vector__XXX
 SG_ HDOP : 272|16@1- (0.01,0) [-327.64|327.64] "" Vector__XXX
 SG_ NumberOfSVs : 264|8@1+ (1,0) [0|252] "" Vector__XXX
 SG_ GNSSIntegrity : 256|2@1+ (1,0) [0|3] "" Vector__XXX
 SG_ GNSSMethod : 252|4@1+ (1,0) [0|15] "" Vector__XXX
 SG_ TypeOfSystem : 248|4@1+ (1,0) [0|4] "" Vector__XXX
 SG_ AltitudeHigh : 216|32@1- (4294.967295,0) [-1705215488|1705215488] "m" Vector__XXX
 SG_ AltitudeLow : 184|32@1+ (1E-006,0) [0|4294] "m" Vector__XXX
 SG_ LongitudeHigh : 152|32@1- (4.29497E-007,0) [-180|180] "deg" Vector__XXX
 SG_ LongitudeLow : 120|32@1+ (1E-016,0) [0|4.294E-007] "deg" Vector__XXX
 SG_ LatitudeHigh : 88|32@1- (4.29497E-007,0) [-90|90] "deg" Vector__XXX
 SG_ LatitudeLow : 56|32@1+ (1E-016,0) [0|4.294E-007] "deg" Vector__XXX
 SG_ PositionTime : 24|32@1+ (0.0001,0) [0|86401] "hour" Vector__XXX
 SG_ PositionDate : 8|16@1+ (1,0) [0|65532] "day" Vector__XXX
 SG_ SequenceID : 0|8@1+ (1,0) [0|255] "" Vector__XXX

BO_ 2583299838 GNSSPseudoRangeNoiseStatistic: 15 Vector__XXX
 SG_ STDofAltError : 104|16@1+ (0.01,0) [0|655.32] "m" Vector__XXX
 SG_ STDofLonError : 88|16@1+ (0.01,0) [0|655.32] "m" Vector__XXX
 SG_ STDofLatError : 72|16@1+ (0.01,0) [0|655.32] "m" Vector__XXX
 SG_ OrientationOfMinorAxis : 56|16@1+ (0.0001,0) [0|6.2832] "rad" Vector__XXX
 SG_ STDofMinorAxis : 40|16@1+ (0.01,0) [0|655.32] "m" Vector__XXX
 SG_ STDofMajorAxis : 24|16@1+ (0.01,0) [0|655.32] "m" Vector__XXX
 SG_ RMSofPositionUncertainty : 8|16@1+ (0.01,0) [0|655.32] "m" Vector__XXX
 SG_ SequenceID : 0|8@1+ (1,0) [0|255] "" Vector__XXX

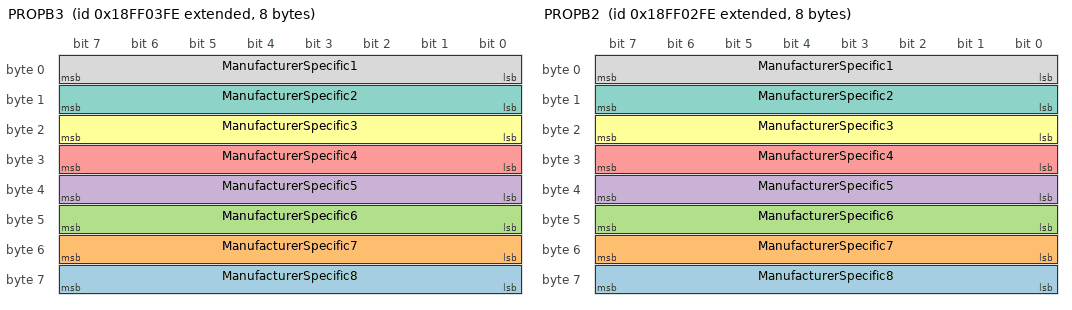
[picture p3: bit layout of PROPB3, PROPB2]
BO_ 2566849534 PROPB3: 8 Vector__XXX
 SG_ ManufacturerSpecific8 : 56|8@1+ (1,0) [0|255] "" Vector__XXX
 SG_ ManufacturerSpecific7 : 48|8@1+ (1,0) [0|255] "" Vector__XXX
 SG_ ManufacturerSpecific6 : 40|8@1+ (1,0) [0|255] "" Vector__XXX
 SG_ ManufacturerSpecific5 : 32|8@1+ (1,0) [0|255] "" Vector__XXX
 SG_ ManufacturerSpecific4 : 24|8@1+ (1,0) [0|255] "" Vector__XXX
 SG_ ManufacturerSpecific3 : 16|8@1+ (1,0) [0|255] "" Vector__XXX
 SG_ ManufacturerSpecific2 : 8|8@1+ (1,0) [0|255] "" Vector__XXX
 SG_ ManufacturerSpecific1 : 0|8@1+ (1,0) [0|255] "" Vector__XXX

BO_ 2566849278 PROPB2: 8 Vector__XXX
 SG_ ManufacturerSpecific8 : 56|8@1+ (1,0) [0|255] "" Vector__XXX
 SG_ ManufacturerSpecific7 : 48|8@1+ (1,0) [0|255] "" Vector__XXX
 SG_ ManufacturerSpecific6 : 40|8@1+ (1,0) [0|255] "" Vector__XXX
 SG_ ManufacturerSpecific5 : 32|8@1+ (1,0) [0|255] "" Vector__XXX
 SG_ ManufacturerSpecific4 : 24|8@1+ (1,0) [0|255] "" Vector__XXX
 SG_ ManufacturerSpecific3 : 16|8@1+ (1,0) [0|255] "" Vector__XXX
 SG_ ManufacturerSpecific2 : 8|8@1+ (1,0) [0|255] "" Vector__XXX
 SG_ ManufacturerSpecific1 : 0|8@1+ (1,0) [0|255] "" Vector__XXX

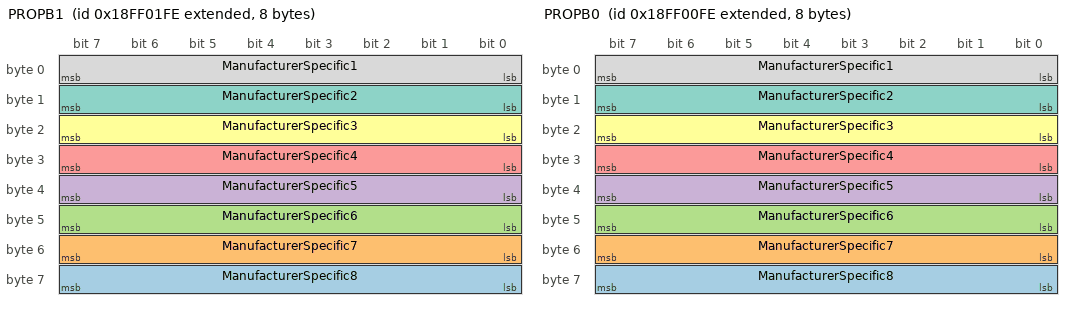
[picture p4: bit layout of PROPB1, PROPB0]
BO_ 2566849022 PROPB1: 8 Vector__XXX
 SG_ ManufacturerSpecific8 : 56|8@1+ (1,0) [0|255] "" Vector__XXX
 SG_ ManufacturerSpecific7 : 48|8@1+ (1,0) [0|255] "" Vector__XXX
 SG_ ManufacturerSpecific6 : 40|8@1+ (1,0) [0|255] "" Vector__XXX
 SG_ ManufacturerSpecific5 : 32|8@1+ (1,0) [0|255] "" Vector__XXX
 SG_ ManufacturerSpecific4 : 24|8@1+ (1,0) [0|255] "" Vector__XXX
 SG_ ManufacturerSpecific3 : 16|8@1+ (1,0) [0|255] "" Vector__XXX
 SG_ ManufacturerSpecific2 : 8|8@1+ (1,0) [0|255] "" Vector__XXX
 SG_ ManufacturerSpecific1 : 0|8@1+ (1,0) [0|255] "" Vector__XXX

BO_ 2566848766 PROPB0: 8 Vector__XXX
 SG_ ManufacturerSpecific8 : 56|8@1+ (1,0) [0|255] "" Vector__XXX
 SG_ ManufacturerSpecific7 : 48|8@1+ (1,0) [0|255] "" Vector__XXX
 SG_ ManufacturerSpecific6 : 40|8@1+ (1,0) [0|255] "" Vector__XXX
 SG_ ManufacturerSpecific5 : 32|8@1+ (1,0) [0|255] "" Vector__XXX
 SG_ ManufacturerSpecific4 : 24|8@1+ (1,0) [0|255] "" Vector__XXX
 SG_ ManufacturerSpecific3 : 16|8@1+ (1,0) [0|255] "" Vector__XXX
 SG_ ManufacturerSpecific2 : 8|8@1+ (1,0) [0|255] "" Vector__XXX
 SG_ ManufacturerSpecific1 : 0|8@1+ (1,0) [0|255] "" Vector__XXX

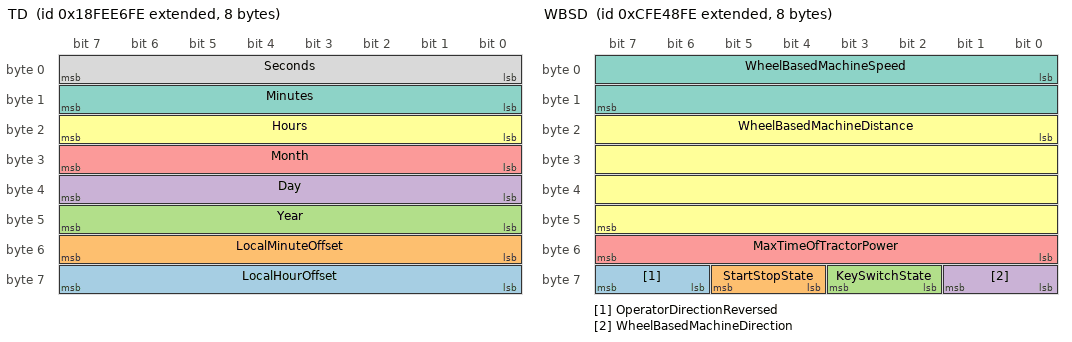
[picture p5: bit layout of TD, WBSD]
BO_ 2566842110 TD: 8 Vector__XXX
 SG_ LocalHourOffset : 56|8@1+ (1,-125) [-125|125] "hr" Vector__XXX
 SG_ LocalMinuteOffset : 48|8@1+ (1,-125) [-125|125] "mins" Vector__XXX
 SG_ Year : 40|8@1+ (1,1985) [1985|2235] "years" Vector__XXX
 SG_ Day : 32|8@1+ (0.25,0) [0|62.5] "days" Vector__XXX
 SG_ Month : 24|8@1+ (1,0) [0|250] "months" Vector__XXX
 SG_ Hours : 16|8@1+ (1,0) [0|250] "hr" Vector__XXX
 SG_ Minutes : 8|8@1+ (1,0) [0|250] "mins" Vector__XXX
 SG_ Seconds : 0|8@1+ (0.25,0) [0|62.5] "s" Vector__XXX

BO_ 2365475326 GBSD: 8 Vector__XXX
 SG_ GroundBasedMachineDirection : 56|2@1+ (1,0) [0|3] "" Vector__XXX
 SG_ GroundBasedMachineDistance : 16|32@1+ (0.001,0) [0|4211080] "m" Vector__XXX
 SG_ GroundBasedMachineSpeed : 0|16@1+ (0.001,0) [0|64.255] "m/s" Vector__XXX

BO_ 2365475070 WBSD: 8 Vector__XXX
 SG_ OperatorDirectionReversed : 62|2@1+ (1,0) [0|3] "" Vector__XXX
 SG_ StartStopState : 60|2@1+ (1,0) [0|4] "" Vector__XXX
 SG_ KeySwitchState : 58|2@1+ (1,0) [0|3] "" Vector__XXX
 SG_ WheelBasedMachineDirection : 56|2@1+ (1,0) [0|3] "" Vector__XXX
 SG_ MaxTimeOfTractorPower : 48|8@1+ (1,0) [0|250] "min" Vector__XXX
 SG_ WheelBasedMachineDistance : 16|32@1+ (0.001,0) [0|4211081.215] "m" Vector__XXX
 SG_ WheelBasedMachineSpeed : 0|16@1+ (0.001,0) [0|64.255] "m/s" Vector__XXX

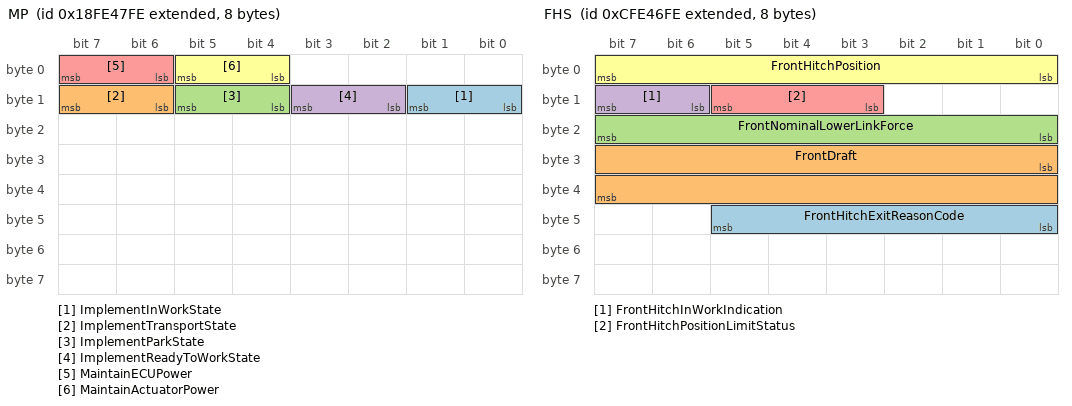
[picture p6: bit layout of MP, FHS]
BO_ 2566801406 MP: 8 Vector__XXX
 SG_ ImplementInWorkState : 8|2@1+ (1,0) [0|0] "" Vector__XXX
 SG_ ImplementTransportState : 14|2@1+ (1,0) [0|3] "" Vector__XXX
 SG_ ImplementParkState : 12|2@1+ (1,0) [0|3] "" Vector__XXX
 SG_ ImplementReadyToWorkState : 10|2@1+ (1,0) [0|3] "" Vector__XXX
 SG_ MaintainECUPower : 6|2@1+ (1,0) [0|0] "" Vector__XXX
 SG_ MaintainActuatorPower : 4|2@1+ (1,0) [0|3] "" Vector__XXX

BO_ 2365474558 FHS: 8 Vector__XXX
 SG_ FrontHitchExitReasonCode : 40|6@1+ (1,0) [0|63] "" Vector__XXX
 SG_ FrontDraft : 24|16@1+ (10,-320000) [-320000|322550] "N" Vector__XXX
 SG_ FrontNominalLowerLinkForce : 16|8@1+ (0.8,-100) [-100|100] "%" Vector__XXX
 SG_ FrontHitchInWorkIndication : 14|2@1+ (1,0) [0|3] "" Vector__XXX
 SG_ FrontHitchPositionLimitStatus : 11|3@1+ (1,0) [0|7] "" Vector__XXX
 SG_ FrontHitchPosition : 0|8@1+ (0.4,0) [0|100] "%" Vector__XXX

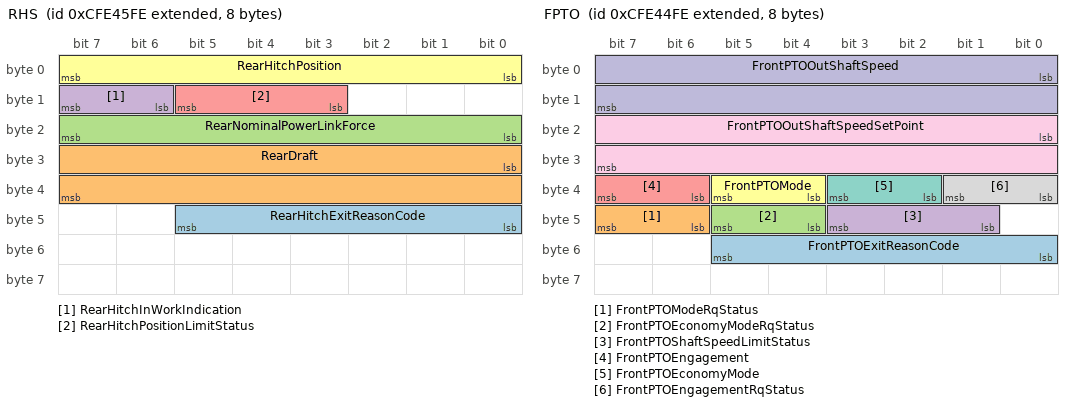
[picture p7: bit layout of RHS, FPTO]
BO_ 2365474302 RHS: 8 Vector__XXX
 SG_ RearHitchExitReasonCode : 40|6@1+ (1,0) [0|63] "" Vector__XXX
 SG_ RearDraft : 24|16@1+ (10,-320000) [-320000|322550] "N" Vector__XXX
 SG_ RearNominalPowerLinkForce : 16|8@1+ (0.8,-100) [-100|100] "%" Vector__XXX
 SG_ RearHitchInWorkIndication : 14|2@1+ (1,0) [0|3] "" Vector__XXX
 SG_ RearHitchPositionLimitStatus : 11|3@1+ (1,0) [0|7] "" Vector__XXX
 SG_ RearHitchPosition : 0|8@1+ (0.4,0) [0|100] "%" Vector__XXX

BO_ 2365474046 FPTO: 8 Vector__XXX
 SG_ FrontPTOExitReasonCode : 48|6@1+ (1,0) [0|63] "" Vector__XXX
 SG_ FrontPTOModeRqStatus : 46|2@1+ (1,0) [0|3] "" Vector__XXX
 SG_ FrontPTOEconomyModeRqStatus : 44|2@1+ (1,0) [0|3] "" Vector__XXX
 SG_ FrontPTOShaftSpeedLimitStatus : 41|3@1+ (1,0) [0|7] "" Vector__XXX
 SG_ FrontPTOEngagement : 38|2@1+ (1,0) [0|3] "" Vector__XXX
 SG_ FrontPTOMode : 36|2@1+ (1,0) [0|3] "" Vector__XXX
 SG_ FrontPTOEconomyMode : 34|2@1+ (1,0) [0|3] "" Vector__XXX
 SG_ FrontPTOEngagementRqStatus : 32|2@1+ (1,0) [0|3] "" Vector__XXX
 SG_ FrontPTOOutShaftSpeedSetPoint : 16|16@1+ (0.125,0) [0|8031.88] "1/min" Vector__XXX
 SG_ FrontPTOOutShaftSpeed : 0|16@1+ (0.125,0) [0|8031.88] "1/min" Vector__XXX

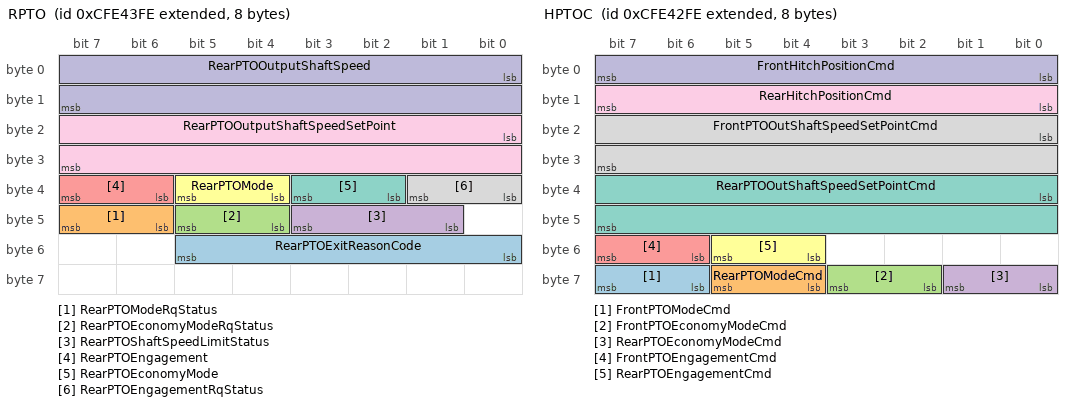
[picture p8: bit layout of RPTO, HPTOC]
BO_ 2365473790 RPTO: 8 Vector__XXX
 SG_ RearPTOExitReasonCode : 48|6@1+ (1,0) [0|63] "" Vector__XXX
 SG_ RearPTOModeRqStatus : 46|2@1+ (1,0) [0|3] "" Vector__XXX
 SG_ RearPTOEconomyModeRqStatus : 44|2@1+ (1,0) [0|3] "" Vector__XXX
 SG_ RearPTOShaftSpeedLimitStatus : 41|3@1+ (1,0) [0|7] "" Vector__XXX
 SG_ RearPTOEngagement : 38|2@1+ (1,0) [0|3] "" Vector__XXX
 SG_ RearPTOMode : 36|2@1+ (1,0) [0|3] "" Vector__XXX
 SG_ RearPTOEconomyMode : 34|2@1+ (1,0) [0|3] "" Vector__XXX
 SG_ RearPTOEngagementRqStatus : 32|2@1+ (1,0) [0|3] "" Vector__XXX
 SG_ RearPTOOutputShaftSpeedSetPoint : 16|16@1+ (0.125,0) [0|8031.88] "1/min" Vector__XXX
 SG_ RearPTOOutputShaftSpeed : 0|16@1+ (0.125,0) [0|8031.88] "1/min" Vector__XXX

BO_ 2365473534 HPTOC: 8 Vector__XXX
 SG_ FrontPTOModeCmd : 62|2@1+ (1,0) [0|3] "" Vector__XXX
 SG_ RearPTOModeCmd : 60|2@1+ (1,0) [0|3] "" Vector__XXX
 SG_ FrontPTOEconomyModeCmd : 58|2@1+ (1,0) [0|3] "" Vector__XXX
 SG_ RearPTOEconomyModeCmd : 56|2@1+ (1,0) [0|3] "" Vector__XXX
 SG_ FrontPTOEngagementCmd : 54|2@1+ (1,0) [0|3] "" Vector__XXX
 SG_ RearPTOEngagementCmd : 52|2@1+ (1,0) [0|3] "" Vector__XXX
 SG_ RearPTOOutShaftSpeedSetPointCmd : 32|16@1+ (0.125,0) [0|801.875] "1/min" Vector__XXX
 SG_ FrontPTOOutShaftSpeedSetPointCmd : 16|16@1+ (0.125,0) [0|8031.875] "1/min" Vector__XXX
 SG_ RearHitchPositionCmd : 8|8@1+ (0.4,0) [0|100] "%" Vector__XXX
 SG_ FrontHitchPositionCmd : 0|8@1+ (0.4,0) [0|100] "%" Vector__XXX

BO_ 2365473278 LCMD: 8 Vector__XXX
 SG_ ImplementRearWorkLightCmd : 62|2@1+ (1,0) [0|3] "" Vector__XXX
 SG_ ImplementLeftFacingWorkLightCmd : 60|2@1+ (1,0) [0|3] "" Vector__XXX
 SG_ ImplementRightFacingWorkLightCmd : 58|2@1+ (1,0) [0|3] "" Vector__XXX
 SG_ LightingDataRequestCmd : 56|2@1+ (1,0) [0|3] "" Vector__XXX
 SG_ ImplementLeftForwardLightCmd : 54|2@1+ (1,0) [0|3] "" Vector__XXX
 SG_ ImplementRightForwardLightCmd : 52|2@1+ (1,0) [0|3] "" Vector__XXX
 SG_ ImplementOEMOption1LightCmd : 50|2@1+ (1,0) [0|3] "" Vector__XXX
 SG_ ImplementOEMOption2LightCmd : 48|2@1+ (1,0) [0|3] "" Vector__XXX
 SG_ TractorFrontHighWorkLightCmd : 46|2@1+ (1,0) [0|3] "" Vector__XXX
 SG_ TractorFrontLowWorkLightCmd : 44|2@1+ (1,0) [0|3] "" Vector__XXX
 SG_ TractorSideHighWorkLightCmd : 42|2@1+ (1,0) [0|3] "" Vector__XXX
 SG_ TractorSideLowWorkLightCmd : 40|2@1+ (1,0) [0|3] "" Vector__XXX
 SG_ TractorRearHighWorkLightCmd : 38|2@1+ (1,0) [0|3] "" Vector__XXX
 SG_ TractorRearLowWorkLightCmd : 36|2@1+ (1,0) [0|3] "" Vector__XXX
 SG_ TractorUndersideWorkLightCmd : 34|2@1+ (1,0) [0|3] "" Vector__XXX
 SG_ RearFogLightCmd : 32|2@1+ (1,0) [0|3] "" Vector__XXX
 SG_ TractorMarkerLightCmd : 30|2@1+ (1,0) [0|3] "" Vector__XXX
 SG_ ImplementMarkerLightCmd : 28|2@1+ (1,0) [0|3] "" Vector__XXX
 SG_ TractorClearanceLightCmd : 26|2@1+ (1,0) [0|3] "" Vector__XXX
 SG_ ImplementClearanceLightCmd : 24|2@1+ (1,0) [0|3] "" Vector__XXX
 SG_ LeftStopLightCmd : 22|2@1+ (1,0) [0|3] "" Vector__XXX
 SG_ RightStopLightCmd : 20|2@1+ (1,0) [0|3] "" Vector__XXX
 SG_ CentreStopLightCmd : 18|2@1+ (1,0) [0|3] "" Vector__XXX
 SG_ BackUpLightAndAlarmHornCmd : 16|2@1+ (1,0) [0|3] "" Vector__XXX
 SG_ LeftTurnSignalLightCmd : 14|2@1+ (1,0) [0|3] "" Vector__XXX
 SG_ RightTurnSignalLightCmd : 12|2@1+ (1,0) [0|3] "" Vector__XXX
 SG_ RotatingBeaconLightCmd : 10|2@1+ (1,0) [0|3] "" Vector__XXX
 SG_ TractorFrontFogLightCmd : 8|2@1+ (1,0) [0|3] "" Vector__XXX
 SG_ HighBeamHeadLightCmd : 6|2@1+ (1,0) [0|3] "" Vector__XXX
 SG_ LowBeamHeadLightCmd : 4|2@1+ (1,0) [0|3] "" Vector__XXX
 SG_ AlternateHeadLightCmd : 2|2@1+ (1,0) [0|3] "" Vector__XXX
 SG_ DaytimeRunningLightCmd : 0|2@1+ (1,0) [0|3] "" Vector__XXX

BO_ 2566799614 LID: 8 Vector__XXX
 SG_ ImplementRearWorkLightData : 62|2@1+ (1,0) [0|3] "" Vector__XXX
 SG_ ImplLeftFacingWorkLightData : 60|2@1+ (1,0) [0|3] "" Vector__XXX
 SG_ ImplRightFacingWorkLightData : 58|2@1+ (1,0) [0|3] "" Vector__XXX
 SG_ ImplementLeftForwardLightData : 54|2@1+ (1,0) [0|3] "" Vector__XXX
 SG_ ImplementRightForwardLightData : 52|2@1+ (1,0) [0|3] "" Vector__XXX
 SG_ ImplementOEMOption1LightData : 50|2@1+ (1,0) [0|3] "" Vector__XXX
 SG_ ImplementOEMOption2LightData : 48|2@1+ (1,0) [0|3] "" Vector__XXX
 SG_ TractorFrontHighWorkLightData : 46|2@1+ (1,0) [0|3] "" Vector__XXX
 SG_ TractorFrontLowWorkLightData : 44|2@1+ (1,0) [0|3] "" Vector__XXX
 SG_ TractorSideHighWorkLightData : 42|2@1+ (1,0) [0|3] "" Vector__XXX
 SG_ TractorSideLowWorkLightData : 40|2@1+ (1,0) [0|3] "" Vector__XXX
 SG_ TractorRearHighWorkLightData : 38|2@1+ (1,0) [0|3] "" Vector__XXX
 SG_ TractorRearLowWorkLightData : 36|2@1+ (1,0) [0|3] "" Vector__XXX
 SG_ TractorUndersideWorkLightData : 34|2@1+ (1,0) [0|3] "" Vector__XXX
 SG_ RearFogLightData : 32|2@1+ (1,0) [0|3] "" Vector__XXX
 SG_ TractorMarkerLightData : 30|2@1+ (1,0) [0|3] "" Vector__XXX
 SG_ ImplementMarkerLightData : 28|2@1+ (1,0) [0|3] "" Vector__XXX
 SG_ TractorClearanceLightData : 26|2@1+ (1,0) [0|3] "" Vector__XXX
 SG_ ImplementClearanceLightData : 24|2@1+ (1,0) [0|3] "" Vector__XXX
 SG_ LefttStopLightData : 22|2@1+ (1,0) [0|3] "" Vector__XXX
 SG_ RightStopLightData : 20|2@1+ (1,0) [0|3] "" Vector__XXX
 SG_ CentreStopLightData : 18|2@1+ (1,0) [0|3] "" Vector__XXX
 SG_ BackUpLightAndAlarmHornData : 16|2@1+ (1,0) [0|3] "" Vector__XXX
 SG_ LeftTurnSignalLightData : 14|2@1+ (1,0) [0|3] "" Vector__XXX
 SG_ RightTurnSignalLightData : 12|2@1+ (1,0) [0|3] "" Vector__XXX
 SG_ RotationBeaconLightData : 10|2@1+ (1,0) [0|3] "" Vector__XXX
 SG_ TractorFrontFogLightData : 8|2@1+ (1,0) [0|3] "" Vector__XXX
 SG_ HighBeamHeadLightData : 6|2@1+ (1,0) [0|3] "" Vector__XXX
 SG_ LowBeamHeadLightData : 4|2@1+ (1,0) [0|3] "" Vector__XXX
 SG_ AlternateHeadLightData : 2|2@1+ (1,0) [0|3] "" Vector__XXX
 SG_ DaytimeRunningLightData : 0|2@1+ (1,0) [0|3] "" Vector__XXX

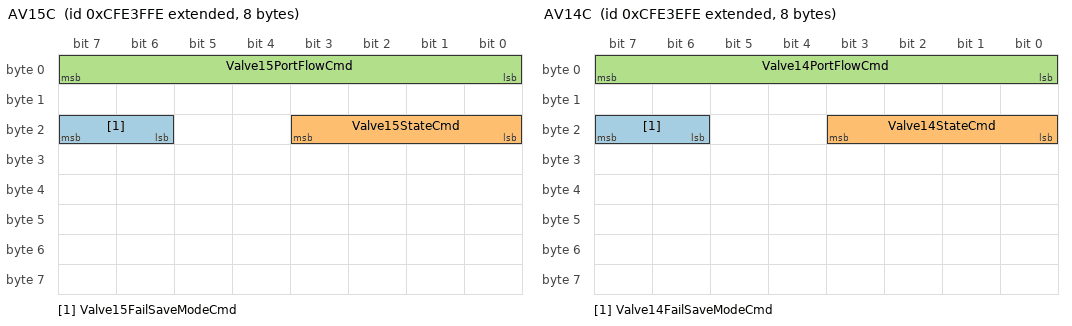
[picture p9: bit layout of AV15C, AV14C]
BO_ 2365472766 AV15C: 8 Vector__XXX
 SG_ Valve15FailSaveModeCmd : 22|2@1+ (1,0) [0|3] "" Vector__XXX
 SG_ Valve15StateCmd : 16|4@1+ (1,0) [0|15] "" Vector__XXX
 SG_ Valve15PortFlowCmd : 0|8@1+ (0.4,0) [0|100] "%" Vector__XXX

BO_ 2365472510 AV14C: 8 Vector__XXX
 SG_ Valve14FailSaveModeCmd : 22|2@1+ (1,0) [0|3] "" Vector__XXX
 SG_ Valve14StateCmd : 16|4@1+ (1,0) [0|15] "" Vector__XXX
 SG_ Valve14PortFlowCmd : 0|8@1+ (0.4,0) [0|100] "%" Vector__XXX

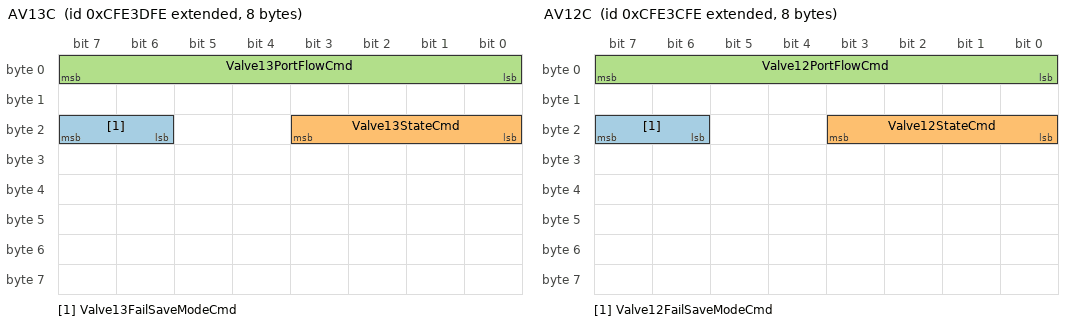
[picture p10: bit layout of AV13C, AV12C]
BO_ 2365472254 AV13C: 8 Vector__XXX
 SG_ Valve13FailSaveModeCmd : 22|2@1+ (1,0) [0|3] "" Vector__XXX
 SG_ Valve13StateCmd : 16|4@1+ (1,0) [0|15] "" Vector__XXX
 SG_ Valve13PortFlowCmd : 0|8@1+ (0.4,0) [0|100] "%" Vector__XXX

BO_ 2365471998 AV12C: 8 Vector__XXX
 SG_ Valve12FailSaveModeCmd : 22|2@1+ (1,0) [0|3] "" Vector__XXX
 SG_ Valve12StateCmd : 16|4@1+ (1,0) [0|15] "" Vector__XXX
 SG_ Valve12PortFlowCmd : 0|8@1+ (0.4,0) [0|100] "%" Vector__XXX

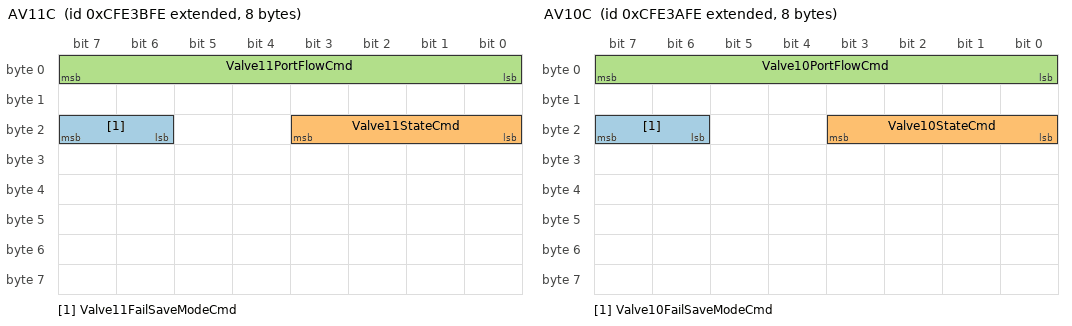
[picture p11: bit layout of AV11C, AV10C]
BO_ 2365471742 AV11C: 8 Vector__XXX
 SG_ Valve11FailSaveModeCmd : 22|2@1+ (1,0) [0|3] "" Vector__XXX
 SG_ Valve11StateCmd : 16|4@1+ (1,0) [0|15] "" Vector__XXX
 SG_ Valve11PortFlowCmd : 0|8@1+ (0.4,0) [0|100] "%" Vector__XXX

BO_ 2365471486 AV10C: 8 Vector__XXX
 SG_ Valve10FailSaveModeCmd : 22|2@1+ (1,0) [0|3] "" Vector__XXX
 SG_ Valve10StateCmd : 16|4@1+ (1,0) [0|15] "" Vector__XXX
 SG_ Valve10PortFlowCmd : 0|8@1+ (0.4,0) [0|100] "%" Vector__XXX

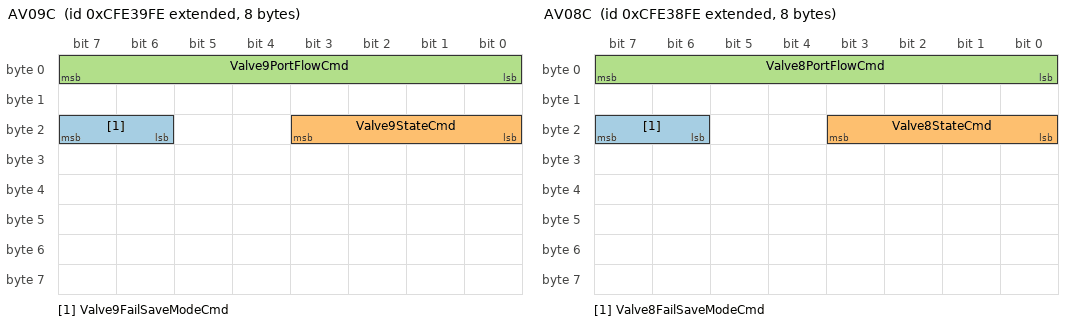
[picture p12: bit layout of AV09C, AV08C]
BO_ 2365471230 AV09C: 8 Vector__XXX
 SG_ Valve9FailSaveModeCmd : 22|2@1+ (1,0) [0|3] "" Vector__XXX
 SG_ Valve9StateCmd : 16|4@1+ (1,0) [0|15] "" Vector__XXX
 SG_ Valve9PortFlowCmd : 0|8@1+ (0.4,0) [0|100] "%" Vector__XXX

BO_ 2365470974 AV08C: 8 Vector__XXX
 SG_ Valve8FailSaveModeCmd : 22|2@1+ (1,0) [0|3] "" Vector__XXX
 SG_ Valve8StateCmd : 16|4@1+ (1,0) [0|15] "" Vector__XXX
 SG_ Valve8PortFlowCmd : 0|8@1+ (0.4,0) [0|100] "%" Vector__XXX

BO_ 2365470718 AV07C: 8 Vector__XXX
 SG_ Valve7FailSaveModeCmd : 22|2@1+ (1,0) [0|3] "" Vector__XXX
 SG_ Valve7StateCmd : 16|4@1+ (1,0) [0|15] "" Vector__XXX
 SG_ Valve7PortFlowCmd : 0|8@1+ (0.4,0) [0|100] "%" Vector__XXX

BO_ 2365470462 AV06C: 8 Vector__XXX
 SG_ Valve6FailSaveModeCmd : 22|2@1+ (1,0) [0|3] "" Vector__XXX
 SG_ Valve6StateCmd : 16|4@1+ (1,0) [0|15] "" Vector__XXX
 SG_ Valve6PortFlowCmd : 0|8@1+ (0.4,0) [0|100] "%" Vector__XXX

BO_ 2365470206 AV05C: 8 Vector__XXX
 SG_ Valve5FailSaveModeCmd : 22|2@1+ (1,0) [0|3] "" Vector__XXX
 SG_ Valve5StateCmd : 16|4@1+ (1,0) [0|15] "" Vector__XXX
 SG_ Valve5PortFlowCmd : 0|8@1+ (0.4,0) [0|100] "%" Vector__XXX

BO_ 2365469950 AV04C: 8 Vector__XXX
 SG_ Valve4FailSaveModeCmd : 22|2@1+ (1,0) [0|3] "" Vector__XXX
 SG_ Valve4StateCmd : 16|4@1+ (1,0) [0|15] "" Vector__XXX
 SG_ Valve4PortFlowCmd : 0|8@1+ (0.4,0) [0|100] "%" Vector__XXX

BO_ 2365469694 AV03C: 8 Vector__XXX
 SG_ Valve3FailSaveModeCmd : 22|2@1+ (1,0) [0|3] "" Vector__XXX
 SG_ Valve3StateCmd : 16|4@1+ (1,0) [0|15] "" Vector__XXX
 SG_ Valve3PortFlowCmd : 0|8@1+ (0.4,0) [0|100] "%" Vector__XXX

BO_ 2365469438 AV02C: 8 Vector__XXX
 SG_ Valve2FailSaveModeCmd : 22|2@1+ (1,0) [0|3] "" Vector__XXX
 SG_ Valve2StateCmd : 16|4@1+ (1,0) [0|15] "" Vector__XXX
 SG_ Valve2PortFlowCmd : 0|8@1+ (0.4,0) [0|100] "%" Vector__XXX

BO_ 2365469182 AV01C: 8 Vector__XXX
 SG_ Valve1FailSaveModeCmd : 22|2@1+ (1,0) [0|3] "" Vector__XXX
 SG_ Valve1StateCmd : 16|4@1+ (1,0) [0|15] "" Vector__XXX
 SG_ Valve1PortFlowCmd : 0|8@1+ (0.4,0) [0|100] "%" Vector__XXX

BO_ 2365468926 AV00C: 8 Vector__XXX
 SG_ Valve0FailSaveModeCmd : 22|2@1+ (1,0) [0|3] "" Vector__XXX
 SG_ Valve0StateCmd : 16|4@1+ (1,0) [0|15] "" Vector__XXX
 SG_ Valve0PortFlowCmd : 0|8@1+ (0.4,0) [0|100] "%" Vector__XXX

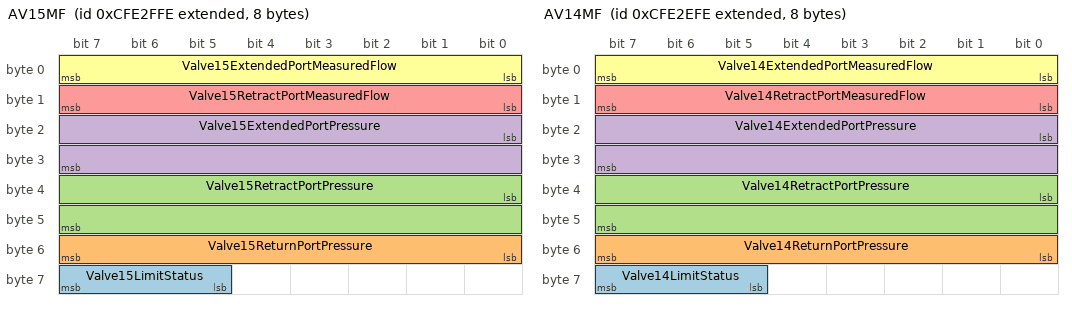
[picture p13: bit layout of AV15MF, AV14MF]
BO_ 2365468670 AV15MF: 8 Vector__XXX
 SG_ Valve15LimitStatus : 61|3@1+ (1,0) [0|7] "" Vector__XXX
 SG_ Valve15ReturnPortPressure : 48|8@1+ (16,0) [0|4000] "kPa" Vector__XXX
 SG_ Valve15RetractPortPressure : 32|16@1+ (5,0) [0|321275] "kPa" Vector__XXX
 SG_ Valve15ExtendedPortPressure : 16|16@1+ (5,0) [0|321275] "kPa" Vector__XXX
 SG_ Valve15RetractPortMeasuredFlow : 8|8@1+ (1,-125) [-125|125] "%" Vector__XXX
 SG_ Valve15ExtendedPortMeasuredFlow : 0|8@1+ (1,-125) [-125|125] "%" Vector__XXX

BO_ 2365468414 AV14MF: 8 Vector__XXX
 SG_ Valve14LimitStatus : 61|3@1+ (1,0) [0|7] "" Vector__XXX
 SG_ Valve14ReturnPortPressure : 48|8@1+ (16,0) [0|4000] "kPa" Vector__XXX
 SG_ Valve14RetractPortPressure : 32|16@1+ (5,0) [0|321275] "kPa" Vector__XXX
 SG_ Valve14ExtendedPortPressure : 16|16@1+ (5,0) [0|321275] "kPa" Vector__XXX
 SG_ Valve14RetractPortMeasuredFlow : 8|8@1+ (1,-125) [-125|125] "%" Vector__XXX
 SG_ Valve14ExtendedPortMeasuredFlow : 0|8@1+ (1,-125) [-125|125] "%" Vector__XXX

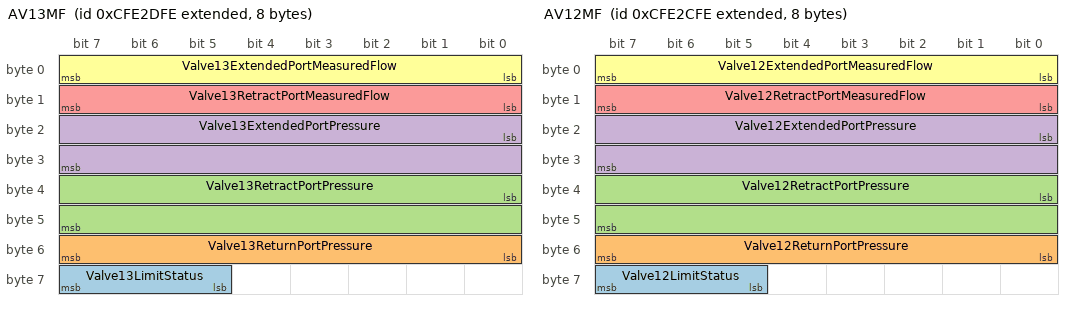
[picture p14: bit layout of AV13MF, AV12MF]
BO_ 2365468158 AV13MF: 8 Vector__XXX
 SG_ Valve13LimitStatus : 61|3@1+ (1,0) [0|7] "" Vector__XXX
 SG_ Valve13ReturnPortPressure : 48|8@1+ (16,0) [0|4000] "kPa" Vector__XXX
 SG_ Valve13RetractPortPressure : 32|16@1+ (5,0) [0|321275] "kPa" Vector__XXX
 SG_ Valve13ExtendedPortPressure : 16|16@1+ (5,0) [0|321275] "kPa" Vector__XXX
 SG_ Valve13RetractPortMeasuredFlow : 8|8@1+ (1,-125) [-125|125] "%" Vector__XXX
 SG_ Valve13ExtendedPortMeasuredFlow : 0|8@1+ (1,-125) [-125|125] "%" Vector__XXX

BO_ 2365467902 AV12MF: 8 Vector__XXX
 SG_ Valve12LimitStatus : 61|3@1+ (1,0) [0|7] "" Vector__XXX
 SG_ Valve12ReturnPortPressure : 48|8@1+ (16,0) [0|4000] "kPa" Vector__XXX
 SG_ Valve12RetractPortPressure : 32|16@1+ (5,0) [0|321275] "kPa" Vector__XXX
 SG_ Valve12ExtendedPortPressure : 16|16@1+ (5,0) [0|321275] "kPa" Vector__XXX
 SG_ Valve12RetractPortMeasuredFlow : 8|8@1+ (1,-125) [-125|125] "%" Vector__XXX
 SG_ Valve12ExtendedPortMeasuredFlow : 0|8@1+ (1,-125) [-125|125] "%" Vector__XXX

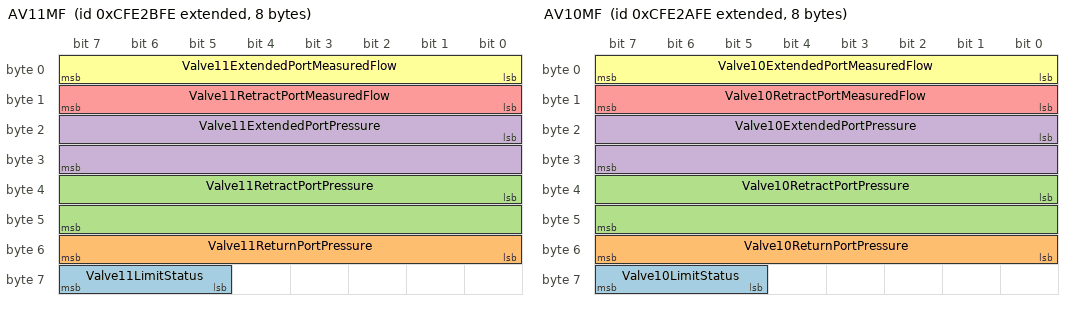
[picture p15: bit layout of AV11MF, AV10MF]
BO_ 2365467646 AV11MF: 8 Vector__XXX
 SG_ Valve11LimitStatus : 61|3@1+ (1,0) [0|7] "" Vector__XXX
 SG_ Valve11ReturnPortPressure : 48|8@1+ (16,0) [0|4000] "kPa" Vector__XXX
 SG_ Valve11RetractPortPressure : 32|16@1+ (5,0) [0|321275] "kPa" Vector__XXX
 SG_ Valve11ExtendedPortPressure : 16|16@1+ (5,0) [0|321275] "kPa" Vector__XXX
 SG_ Valve11RetractPortMeasuredFlow : 8|8@1+ (1,-125) [-125|125] "%" Vector__XXX
 SG_ Valve11ExtendedPortMeasuredFlow : 0|8@1+ (1,-125) [-125|125] "%" Vector__XXX

BO_ 2365467390 AV10MF: 8 Vector__XXX
 SG_ Valve10LimitStatus : 61|3@1+ (1,0) [0|7] "" Vector__XXX
 SG_ Valve10ReturnPortPressure : 48|8@1+ (16,0) [0|4000] "kPa" Vector__XXX
 SG_ Valve10RetractPortPressure : 32|16@1+ (5,0) [0|321275] "kPa" Vector__XXX
 SG_ Valve10ExtendedPortPressure : 16|16@1+ (5,0) [0|321275] "kPa" Vector__XXX
 SG_ Valve10RetractPortMeasuredFlow : 8|8@1+ (1,-125) [-125|125] "%" Vector__XXX
 SG_ Valve10ExtendedPortMeasuredFlow : 0|8@1+ (1,-125) [-125|125] "%" Vector__XXX

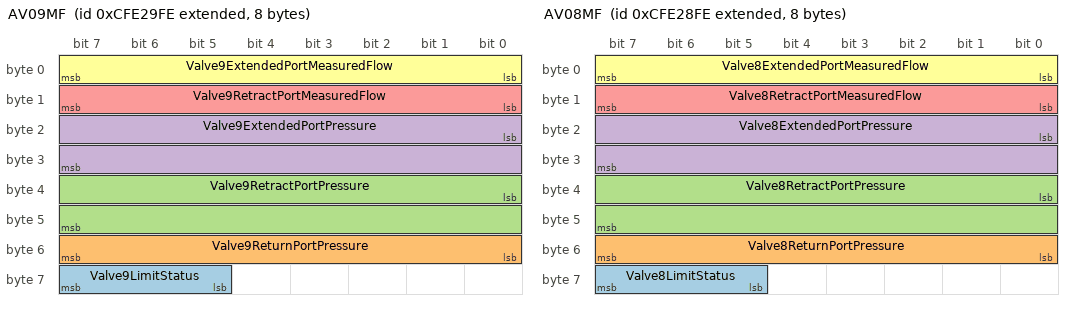
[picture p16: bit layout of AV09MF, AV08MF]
BO_ 2365467134 AV09MF: 8 Vector__XXX
 SG_ Valve9LimitStatus : 61|3@1+ (1,0) [0|7] "" Vector__XXX
 SG_ Valve9ReturnPortPressure : 48|8@1+ (16,0) [0|4000] "kPa" Vector__XXX
 SG_ Valve9RetractPortPressure : 32|16@1+ (5,0) [0|321275] "kPa" Vector__XXX
 SG_ Valve9ExtendedPortPressure : 16|16@1+ (5,0) [0|321275] "kPa" Vector__XXX
 SG_ Valve9RetractPortMeasuredFlow : 8|8@1+ (1,-125) [-125|125] "%" Vector__XXX
 SG_ Valve9ExtendedPortMeasuredFlow : 0|8@1+ (1,-125) [-125|125] "%" Vector__XXX

BO_ 2365466878 AV08MF: 8 Vector__XXX
 SG_ Valve8LimitStatus : 61|3@1+ (1,0) [0|7] "" Vector__XXX
 SG_ Valve8ReturnPortPressure : 48|8@1+ (16,0) [0|4000] "kPa" Vector__XXX
 SG_ Valve8RetractPortPressure : 32|16@1+ (5,0) [0|321275] "kPa" Vector__XXX
 SG_ Valve8ExtendedPortPressure : 16|16@1+ (5,0) [0|321275] "kPa" Vector__XXX
 SG_ Valve8RetractPortMeasuredFlow : 8|8@1+ (1,-125) [-125|125] "%" Vector__XXX
 SG_ Valve8ExtendedPortMeasuredFlow : 0|8@1+ (1,-125) [-125|125] "%" Vector__XXX

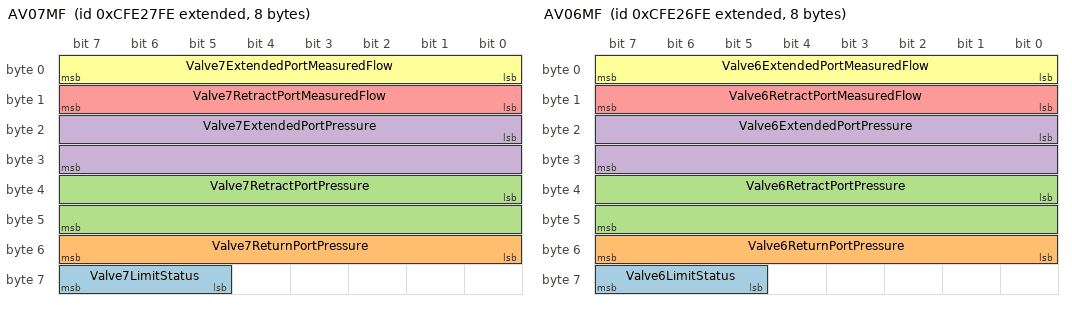
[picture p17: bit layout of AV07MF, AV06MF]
BO_ 2365466622 AV07MF: 8 Vector__XXX
 SG_ Valve7LimitStatus : 61|3@1+ (1,0) [0|7] "" Vector__XXX
 SG_ Valve7ReturnPortPressure : 48|8@1+ (16,0) [0|4000] "kPa" Vector__XXX
 SG_ Valve7RetractPortPressure : 32|16@1+ (5,0) [0|321275] "kPa" Vector__XXX
 SG_ Valve7ExtendedPortPressure : 16|16@1+ (5,0) [0|321275] "kPa" Vector__XXX
 SG_ Valve7RetractPortMeasuredFlow : 8|8@1+ (1,-125) [-125|125] "%" Vector__XXX
 SG_ Valve7ExtendedPortMeasuredFlow : 0|8@1+ (1,-125) [-125|125] "%" Vector__XXX

BO_ 2365466366 AV06MF: 8 Vector__XXX
 SG_ Valve6LimitStatus : 61|3@1+ (1,0) [0|7] "" Vector__XXX
 SG_ Valve6ReturnPortPressure : 48|8@1+ (16,0) [0|4000] "kPa" Vector__XXX
 SG_ Valve6RetractPortPressure : 32|16@1+ (5,0) [0|321275] "kPa" Vector__XXX
 SG_ Valve6ExtendedPortPressure : 16|16@1+ (5,0) [0|321275] "kPa" Vector__XXX
 SG_ Valve6RetractPortMeasuredFlow : 8|8@1+ (1,-125) [-125|125] "%" Vector__XXX
 SG_ Valve6ExtendedPortMeasuredFlow : 0|8@1+ (1,-125) [-125|125] "%" Vector__XXX

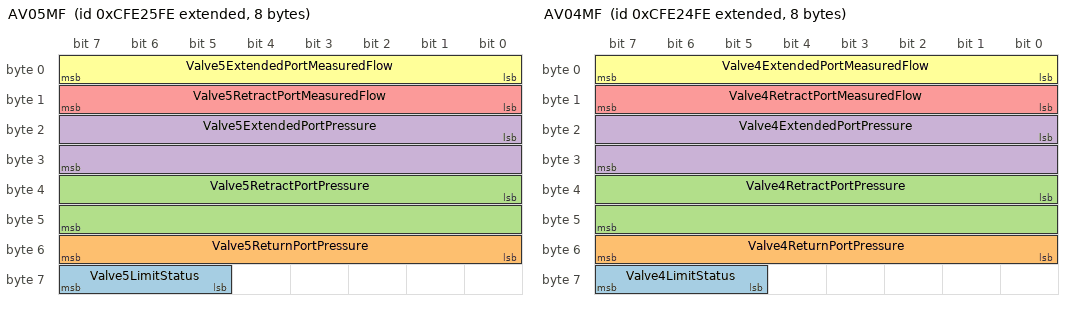
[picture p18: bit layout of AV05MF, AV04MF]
BO_ 2365466110 AV05MF: 8 Vector__XXX
 SG_ Valve5LimitStatus : 61|3@1+ (1,0) [0|7] "" Vector__XXX
 SG_ Valve5ReturnPortPressure : 48|8@1+ (16,0) [0|4000] "kPa" Vector__XXX
 SG_ Valve5RetractPortPressure : 32|16@1+ (5,0) [0|321275] "kPa" Vector__XXX
 SG_ Valve5ExtendedPortPressure : 16|16@1+ (5,0) [0|321275] "kPa" Vector__XXX
 SG_ Valve5RetractPortMeasuredFlow : 8|8@1+ (1,-125) [-125|125] "%" Vector__XXX
 SG_ Valve5ExtendedPortMeasuredFlow : 0|8@1+ (1,-125) [-125|125] "%" Vector__XXX

BO_ 2365465854 AV04MF: 8 Vector__XXX
 SG_ Valve4LimitStatus : 61|3@1+ (1,0) [0|7] "" Vector__XXX
 SG_ Valve4ReturnPortPressure : 48|8@1+ (16,0) [0|4000] "kPa" Vector__XXX
 SG_ Valve4RetractPortPressure : 32|16@1+ (5,0) [0|321275] "kPa" Vector__XXX
 SG_ Valve4ExtendedPortPressure : 16|16@1+ (5,0) [0|321275] "kPa" Vector__XXX
 SG_ Valve4RetractPortMeasuredFlow : 8|8@1+ (1,-125) [-125|125] "%" Vector__XXX
 SG_ Valve4ExtendedPortMeasuredFlow : 0|8@1+ (1,-125) [-125|125] "%" Vector__XXX

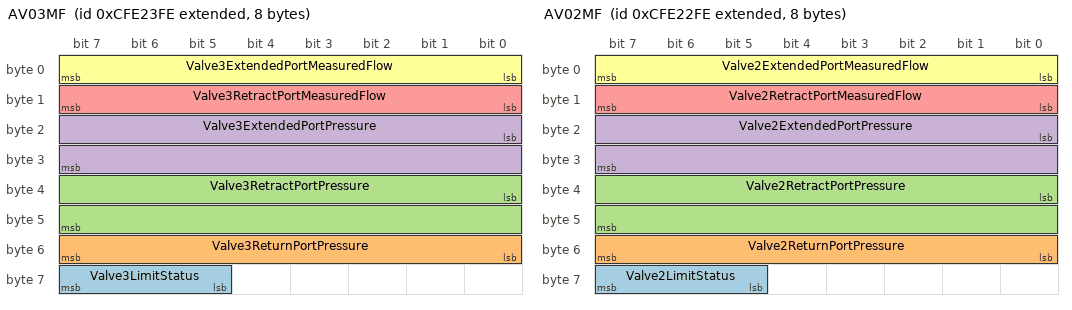
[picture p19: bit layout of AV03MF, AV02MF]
BO_ 2365465598 AV03MF: 8 Vector__XXX
 SG_ Valve3LimitStatus : 61|3@1+ (1,0) [0|7] "" Vector__XXX
 SG_ Valve3ReturnPortPressure : 48|8@1+ (16,0) [0|4000] "kPa" Vector__XXX
 SG_ Valve3RetractPortPressure : 32|16@1+ (5,0) [0|321275] "kPa" Vector__XXX
 SG_ Valve3ExtendedPortPressure : 16|16@1+ (5,0) [0|321275] "kPa" Vector__XXX
 SG_ Valve3RetractPortMeasuredFlow : 8|8@1+ (1,-125) [-125|125] "%" Vector__XXX
 SG_ Valve3ExtendedPortMeasuredFlow : 0|8@1+ (1,-125) [-125|125] "%" Vector__XXX

BO_ 2365465342 AV02MF: 8 Vector__XXX
 SG_ Valve2LimitStatus : 61|3@1+ (1,0) [0|7] "" Vector__XXX
 SG_ Valve2ReturnPortPressure : 48|8@1+ (16,0) [0|4000] "kPa" Vector__XXX
 SG_ Valve2RetractPortPressure : 32|16@1+ (5,0) [0|321275] "kPa" Vector__XXX
 SG_ Valve2ExtendedPortPressure : 16|16@1+ (5,0) [0|321275] "kPa" Vector__XXX
 SG_ Valve2RetractPortMeasuredFlow : 8|8@1+ (1,-125) [-125|125] "%" Vector__XXX
 SG_ Valve2ExtendedPortMeasuredFlow : 0|8@1+ (1,-125) [-125|125] "%" Vector__XXX

CM_ BO_ 2565340800 "ECU to VT";
CM_ SG_ 2565340800 AuxErrorAnyOther "Any other error";
CM_ SG_ 2565340800 AuxErrorInvalidInputID "Invalid Auxiliary Input Object ID";
CM_ SG_ 2565340800 AuxInputEnable "Auxiliary Input Enable";
CM_ SG_ 2565340800 AuxModelIdentification "Model Identification Code of the Auxiliary Input Unit";
CM_ BO_ 2565799552 "Address Claimed";
CM_ BO_ 2365475073 "Ground-based Speed and Distance";
CM_ BO_ 2360147710 "Guidance Machine Status: It provides information and status from the steering control system to the guidance system.";
CM_ SG_ 2360147710 GuidSysComExitReasonCode "Parameter used to indicate why the guidance system cannot currently accept remote commands or has most 
recently stopped accepting remote commands. ";
CM_ SG_ 2360147710 GuidanceLimitStatus "Parameter used to report the Tractor ECU's present limit status associated with guidance commands that are 
persistent (i.e. not transient/temporary/one-shot). ";
CM_ SG_ 2360147710 RequestResetCommandStatus "The machine steering system request to the automatic guidance system to change Curvature Command Status state.";
CM_ SG_ 2360147710 SteeringInputPositionStatus "The machine steering system indicates if manual steering is in correct position for guidance to function.";
CM_ SG_ 2360147710 SteeringSystemReadiness "The machine steering system indicates that it is free from faults that would preclude guidance system operation.";
CM_ SG_ 2360147710 MechanicalSystemLockout "The state of a lockout switch that allows operators to disable automatic steering system functions.";
CM_ SG_ 2360147710 EstimatedCurvature "The machine steering system's estimate of the curvature of the current turn.";
CM_ BO_ 2360213246 "Guidance System Command";
CM_ SG_ 2360213246 CurvatureCommandStatus "This parameter indicates whether the guidance system is attempting to control steering with this command.";
CM_ SG_ 2360213246 CurvatureCommand "Desired course curvature over ground that a machine's steering system is required to achieve.";
CM_ BO_ 2563047166 "General Purpose valve command";
CM_ BO_ 2563112702 "General Purpose valve measured flow";
CM_ SG_ 2563112702 ValveLimitStatus "Parameter used to report the tractor ECUs present limit status associated with a parameter whose commands are persistent";
CM_ BO_ 2563178238 "General purpose valve estimated flow";
CM_ SG_ 2563178238 ValveLimitStatus "Parameter used to report the tractor ECUs present limit status associated with a parameter whose commands are persistent";
CM_ BO_ 2628452094 "File Client to Server";
CM_ SG_ 2628452094 VI_VolumeName "Length of path name string for Initailize Volume Request";
CM_ SG_ 2628452094 VI_Flag_OverwriteExisting "Create a new volume if not yet existing (fails if existing volume)";
CM_ SG_ 2628452094 MF_DestinationPathNameLength "Length of destination path name string for Move File";
CM_ SG_ 2628452094 RF_ReportHiddenFiles "Report Hidden Files";
CM_ SG_ 2628452094 SF_Offset "Offset for Seek File";
CM_ SG_ 2628452094 RF_Count "Number of bytes or number of directory entries to be read";
CM_ SG_ 2628452094 SF_PositionMode "Position Mode for Seek File";
CM_ SG_ 2628452094 OF_PathName "Length of path name string for Open File";
CM_ SG_ 2628452094 MF_SourcePathNameLength "Length of source path name string for Move File";
CM_ SG_ 2628452094 WF_Count "Byte count of data to be written to file";
CM_ SG_ 2628452094 DF_PathName "Length of path name string for Delete File";
CM_ SG_ 2628452094 SA_PathName "Length of path name string for Set File Attributes";
CM_ SG_ 2628452094 VI_Space "The space in units of 512";
CM_ SG_ 2628452094 OF_FlagExclusiveAccess "Open file with exclusive access (fails if already open)";
CM_ SG_ 2628452094 OF_FlagAppend "Open file for appending data to the end of the file";
CM_ SG_ 2628452094 SET_ATTR_Hidden "SetFile Attribute Hidden";
CM_ SG_ 2628452094 OF_FlagCreateNew "Create a new file if not yet existing";
CM_ SG_ 2628452094 MF_MoveModeRecursive "Recursive mode for Move File";
CM_ SG_ 2628452094 DF_DeleteModeRecursive "Recursive mode for Move File";
CM_ SG_ 2628452094 MF_MoveModeForce "Force mode for Move File";
CM_ SG_ 2628452094 DF_DeleteModeForce "Force mode for Move File";
CM_ SG_ 2628452094 VI_Flag_UsingSpaceSpecified "Create volume using space specified";
CM_ SG_ 2628452094 SET_ATTR_ReadOnly "SetFile Attribute Read-Only";
CM_ SG_ 2628452094 CF_Handle "Handle for Close File";
CM_ SG_ 2628452094 WF_Handle "Handle for Write File";
CM_ SG_ 2628452094 RF_Handle "Handle for Read File";
CM_ SG_ 2628452094 SF_Handle "Handle for Seek File";
CM_ SG_ 2628452094 OF_FlagReadWrite "Read/Write/Both/Directory Flag for Open File";
CM_ SG_ 2628452094 CCD_PathName "Length of path name string for Change Current Directory";
CM_ SG_ 2628452094 MF_MoveModeCopy "Copy mode for Move File";
CM_ SG_ 2628452094 DF_DeleteMode "Copy mode for Move File";
CM_ SG_ 2628452094 GA_PathName "Length of path name string for Get File Attributes";
CM_ SG_ 2628452094 FDT_PathName "Length of path name string for Get File Date and Time";
CM_ SG_ 2628452094 CCD_TAN "Transaction Number for Change Default Directory";
CM_ SG_ 2628452094 GCD_TAN "Transaction Number for Get Default Directory";
CM_ SG_ 2628452094 FDT_TAN "Transaction Number for Get File Data & Time";
CM_ SG_ 2628452094 SA_TAN "Transaction Number for Set File Attribute";
CM_ SG_ 2628452094 GA_TAN "Transaction Number for Get File Attribute";
CM_ SG_ 2628452094 RF_TAN "Transaction Number for Read File";
CM_ SG_ 2628452094 CF_TAN "Transaction Number for Close File";
CM_ SG_ 2628452094 WF_TAN "Transaction Number for Write File";
CM_ SG_ 2628452094 SF_TAN "Transaction Number for Seek File";
CM_ SG_ 2628452094 OF_TAN "Transaction Number for Open File";
CM_ SG_ 2628452094 MF_TAN "Transaction Number for Move File";
CM_ SG_ 2628452094 DF_TAN "Transaction Number for Delete File";
CM_ SG_ 2628452094 VI_TAN "Transaction Number for Initailize Volume Request";
CM_ SG_ 2628452094 FSClientCommand "File Server - Client Command";
CM_ BO_ 2628517630 "File Server to Client";
CM_ SG_ 2628517630 GCD_PathName "Length of path name string for Get Current Directory";
CM_ SG_ 2628517630 GCD_FreeSpace "Free Volume Space for Get Current Directory";
CM_ SG_ 2628517630 FDT_TimeHour "Hour of File Time";
CM_ SG_ 2628517630 FDT_TimeMinutes "Minutes of File Time";
CM_ SG_ 2628517630 FDT_TimeSeconds "Day of File Time";
CM_ SG_ 2628517630 FDT_DateYear "Year of File Date";
CM_ SG_ 2628517630 SF_Position "Position of Seek File response";
CM_ SG_ 2628517630 GA_Size "The number of bytes in a file.";
CM_ SG_ 2628517630 GA_ATTR_VolumeRemovable "Attribute Removable MediaAttribute Removable Media";
CM_ SG_ 2628517630 FDT_DateMonth "Month of File Date";
CM_ SG_ 2628517630 GA_ATTR_SupportsLongFilenames "File Attribute ArchiveFile Attribute Archive";
CM_ SG_ 2628517630 VI_ATTR_Directory "File Attribute DirectoryFile Attribute DirectoryFile Attribute DirectoryFile Attribute Directory";
CM_ SG_ 2628517630 GA_ATTR_IsVolume "File Attribute SystemFile Attribute System";
CM_ SG_ 2628517630 GA_ATTR_Hidden "File Attribute HiddenFile Attribute Hidden";
CM_ SG_ 2628517630 FDT_DateDay "Day of File Date";
CM_ SG_ 2628517630 GA_ATTR_ReadOnly "File Attribute Read-OnlyFile Attribute Read-Only";
CM_ SG_ 2628517630 OF_Handle "Handle for Open File";
CM_ SG_ 2628517630 GCD_TotalSpace "Total Volume Space for Get Current Directory";
CM_ SG_ 2628517630 RF_Count "Number of read bytes or number of read directory entries";
CM_ SG_ 2628517630 GSP_SupportMultipleVolumes "File Server Capabilities for Get File Server Properties";
CM_ SG_ 2628517630 WF_Count "Number of written bytes";
CM_ SG_ 2628517630 FDT_ErrorCode "Error Code for Get File Data & Time";
CM_ SG_ 2628517630 RF_ErrorCode "Error Code for Read File";
CM_ SG_ 2628517630 SF_ErrorCode "ErrorCode for Seek File";
CM_ SG_ 2628517630 FSNumberOfOpenFiles "Number of open files";
CM_ SG_ 2628517630 OF_ErrorCode "Error Code for Open File";
CM_ SG_ 2628517630 WF_ErrorCode "Error Code for Write File";
CM_ SG_ 2628517630 CF_ErrorCode "Error Code for Close File";
CM_ SG_ 2628517630 MF_ErrorCode "Error Code for Move File";
CM_ SG_ 2628517630 GA_ErrorCode "Error Code for Get File Attribute";
CM_ SG_ 2628517630 SA_ErrorCode "Error Code for Set File Attribute";
CM_ SG_ 2628517630 GCD_ErrorCode "ErrorCode for Get Current Directory";
CM_ SG_ 2628517630 CCD_ErrorCode "Error Code for Change Current Directory";
CM_ SG_ 2628517630 GSP_MaxNrSimultaneousFilesOpen "The number of files that can maximally be opened simultaneous at the File Server.";
CM_ SG_ 2628517630 DF_ErrorCode "Error Code for Delete File";
CM_ SG_ 2628517630 VI_ErrorCode "Error Code for Volume Initialization";
CM_ SG_ 2628517630 FSBusyWriting "Busy writing";
CM_ SG_ 2628517630 FSBusyReading "Busy reading";
CM_ SG_ 2628517630 OF_TAN "Transaction Number for Open File";
CM_ SG_ 2628517630 SF_TAN "Transaction Number for Seek File";
CM_ SG_ 2628517630 RF_TAN "Transaction Number for Rename File";
CM_ SG_ 2628517630 WF_TAN "Transaction Number for Write File";
CM_ SG_ 2628517630 CF_TAN "Transaction Number for Close File";
CM_ SG_ 2628517630 MF_TAN "Transaction Number for Move File";
CM_ SG_ 2628517630 GA_TAN "Transaction Number for Get File Attributes";
CM_ SG_ 2628517630 SA_TAN "Transaction Number for Set File Attributes";
CM_ SG_ 2628517630 FDT_TAN "Transaction Number for Get File Data & Time";
CM_ SG_ 2628517630 GCD_TAN "Transaction Number for Get Current Directory";
CM_ SG_ 2628517630 CCD_TAN "Transaction Number for Change Current Directory";
CM_ SG_ 2628517630 GSP_VersionNumber "The version of ISO11783-13 that this File Server meets.";
CM_ SG_ 2628517630 DF_TAN "Transaction Number for Delete File";
CM_ SG_ 2628517630 VI_TAN "Transaction Number for Volume Initialization";
CM_ SG_ 2628517630 FSServerCommand "File Server Command";
CM_ BO_ 2364540158 "Electronic Engine Controller #1";
CM_ SG_ 2364540158 EngStarterMode "There are several phases in a starting action and different reasons why a start cannot take place.";
CM_ SG_ 2364540158 SrcAddrssOfCtrllngDvcForEngCtrl "The source address of the SAE J1939 device currently controlling the engine.";
CM_ SG_ 2364540158 ActualEngPercentTorque "The calculated output torque of the engine.";
CM_ SG_ 2364540158 DriversDemandEngPercentTorque "The requested torque output of the engine by the driver.";
CM_ SG_ 2364540158 EngTorqueMode "State signal which indicates which engine torque mode is currently generating, limiting, or controlling the torque.";
CM_ SG_ 2364540158 ActlEngPrcntTorqueHighResolution "This parameter displays an additional torque in percent of the reference engine torque.";
CM_ BO_ 2563243774 "Extended TP (Data)";
CM_ BO_ 2563309310 "Extended TP (Command)";
CM_ BO_ 2314732030 "This PGN provides latitude and longitude referenced to WGS84";
CM_ BO_ 2583168510 "This PGN conveys a comprehensive set of Global Navigation Satellite System (GNSS) parameters, including position 
information
";
CM_ SG_ 2583168510 AgeOfDGNSSCorrections1 "Age of Differential corrections";
CM_ SG_ 2583168510 ReferenceStationID1 "Reference Station ID";
CM_ SG_ 2583168510 NumberOfReferenceStations "Numeric count, event counter, sequence counter";
CM_ SG_ 2583168510 GeoidalSeparation "The difference between the earth ellipsoid and mean-sea-level (geoid) defined by the reference datum used in the position solution ' -' = mean-sea-level below ellipsoid
";
CM_ SG_ 2583168510 PDOP "Dilution of Precision (DOP) indicates the contribution of satellite configuration geometry to positioning error
";
CM_ SG_ 2583168510 HDOP "Dilution of Precision (DOP) indicates the contribution of satellite configuration geometry to positioning error
";
CM_ SG_ 2583168510 NumberOfSVs "Numeric count, event counter, sequence counter";
CM_ SG_ 2583168510 AltitudeHigh "Altitude referenced to WGS-84";
CM_ SG_ 2583168510 AltitudeLow "Altitude referenced to WGS-84";
CM_ SG_ 2583168510 LongitudeHigh "Longitude referenced to WGS-84";
CM_ SG_ 2583168510 LongitudeLow "Longitude referenced to WGS-84";
CM_ SG_ 2583168510 LatitudeHigh "Latitude referenced to WGS-84";
CM_ SG_ 2583168510 LatitudeLow "Latitude referenced to WGS-84";
CM_ SG_ 2583168510 PositionTime "24 hour clock, 0 =  midnight,  time is in UTC";
CM_ SG_ 2583168510 PositionDate "Days since January 1, 1970,  Date is relative to UTC Time";
CM_ SG_ 2583168510 SequenceID "An upward counting number used to tie related information together between different PGNs.
";
CM_ BO_ 2583299838 "GNSS pseudorange measurement noise statistics can be translated in the position domain in order to give statistical measures 
of the quality of the position solution. Intended for use with a Receiver Autonomous Integrity Monitoring (RAIM) application.
";
CM_ SG_ 2583299838 STDofAltError "Error distances expressed in meters";
CM_ SG_ 2583299838 STDofLonError "Error distances expressed in meters";
CM_ SG_ 2583299838 STDofLatError "Error distances expressed in meters.";
CM_ SG_ 2583299838 OrientationOfMinorAxis "Degrees clockwise relative to True North.";
CM_ SG_ 2583299838 STDofMinorAxis "Error distances expressed in meters.";
CM_ SG_ 2583299838 STDofMajorAxis "Error distances expressed in meters.";
CM_ SG_ 2583299838 RMSofPositionUncertainty "Error distances expressed in meters.";
CM_ SG_ 2583299838 SequenceID "An upward counting number used to tie related information together between different PGNs.
";
CM_ BO_ 2566849534 "Proprietary B3";
CM_ BO_ 2566849278 "Proprietary B2";
CM_ BO_ 2566849022 "Proprietary B1";
CM_ BO_ 2566848766 "Proprietary B0";
CM_ BO_ 2566842110 "Time/Date";
CM_ SG_ 2566842110 LocalHourOffset "The hour component of the offset between the UTC (Universal Time Coordinate) time and date and a local time zone time ...";
CM_ SG_ 2566842110 LocalMinuteOffset "The minute component of the offset between the UTC time and date and a local time zone time and date.  This is the ...";
CM_ SG_ 2566842110 Day "The day component of the current calendar date.  This should be reported as the day component of the current date at ...";
CM_ SG_ 2566842110 Hours "The hour component of the current time of day.  This should be reported as the hour component of the current time at ...";
CM_ SG_ 2566842110 Minutes "The minutes component of the current time of day.  This should be reported as the minutes component of the current time ...";
CM_ BO_ 2365475326 "Ground-based Speed and Distance";
CM_ BO_ 2365475070 "Wheel-based Speed and Distance";
CM_ SG_ 2365475070 OperatorDirectionReversed "This parameter indicates whether the reported direction is reversed from the perspective of the operator.";
CM_ BO_ 2566801406 "Message sent by any ECU connected to the implement bus requesting that the Tractor ECU not switch off 
the power for 2 s after it has received the wheel-based speed and distance message indicating that the 
ignition has been switched off. ";
CM_ SG_ 2566801406 ImplementInWorkState "Indicates that an implement is connected to a tractor or power unit and is in work state.";
CM_ BO_ 2365474558 "Secondary or Front Hitch Status";
CM_ SG_ 2365474558 FrontHitchExitReasonCode "This parameter is used to indicate why the front hitch cannot accept remote commands or has most recently 
stopped accepting remote commands. ";
CM_ SG_ 2365474558 FrontHitchPositionLimitStatus "Parameter used to report the tractor ECUs present limit status associated with a parameter whose commands are persistent";
CM_ BO_ 2365474302 "Primary or Rear Hitch Status";
CM_ SG_ 2365474302 RearHitchExitReasonCode "This parameter is used to indicate why the rear hitch cannot accept remote commands or has most recently 
stopped accepting remote commands. ";
CM_ SG_ 2365474302 RearHitchPositionLimitStatus "Parameter used to report the tractor ECUs present limit status associated with a parameter whose commands are persistent";
CM_ BO_ 2365474046 "Pprovides the measurement of the current secondary or front power take-off (PTO) output shaft parameters.";
CM_ SG_ 2365474046 FrontPTOExitReasonCode "This parameter is used to indicate why the front PTO cannot accept remote commands or has most recently 
stopped accepting remote commands.";
CM_ SG_ 2365474046 FrontPTOModeRqStatus "Parameter used to report the tractor ECUs status associated with a parameter whose requests are transient.";
CM_ SG_ 2365474046 FrontPTOEconomyModeRqStatus "Parameter used to report the tractor ECUs status associated with a parameter whose requests are transient.";
CM_ SG_ 2365474046 FrontPTOShaftSpeedLimitStatus "Parameter used to report the tractor ECUs present limit status associated with a parameter whose commands are persistent";
CM_ SG_ 2365474046 FrontPTOEngagementRqStatus "Parameter used to report the tractor ECUs status associated with a parameter whose requests are transient.";
CM_ BO_ 2365473790 "Provides the measurement of the current primary or rear power take-off (PTO) output shaft parameters.
";
CM_ SG_ 2365473790 RearPTOExitReasonCode "This parameter is used to indicate why the rear PTO cannot accept remote commands or has most recently 
stopped accepting remote commands.";
CM_ SG_ 2365473790 RearPTOModeRqStatus "Parameter used to report the tractor ECUs status associated with a parameter whose requests are transient.";
CM_ SG_ 2365473790 RearPTOEconomyModeRqStatus "Parameter used to report the tractor ECUs status associated with a parameter whose requests are transient.";
CM_ SG_ 2365473790 RearPTOShaftSpeedLimitStatus "Parameter used to report the tractor ECUs present limit status associated with a parameter whose commands are persistent";
CM_ SG_ 2365473790 RearPTOEngagementRqStatus "Parameter used to report the tractor ECUs status associated with a parameter whose requests are transient.";
CM_ BO_ 2365473534 "Hitch and PTO Commands";
CM_ BO_ 2365473278 "Lighting Command";
CM_ BO_ 2566799614 "Lighting Data";
CM_ BO_ 2365472766 "Auxiliary Valve Command";
CM_ BO_ 2365472510 "Auxiliary Valve Command";
CM_ BO_ 2365472254 "Auxiliary Valve Command";
CM_ BO_ 2365471998 "Auxiliary Valve Command";
CM_ BO_ 2365471742 "Auxiliary Valve Command";
CM_ BO_ 2365471486 "Auxiliary Valve Command";
CM_ BO_ 2365471230 "Auxiliary Valve Command";
CM_ BO_ 2365470974 "Auxiliary Valve Command";
CM_ BO_ 2365470718 "Auxiliary Valve Command";
CM_ BO_ 2365470462 "Auxiliary Valve Command";
CM_ BO_ 2365470206 "Auxiliary Valve Command";
CM_ BO_ 2365469950 "Auxiliary Valve Command";
CM_ BO_ 2365469694 "Auxiliary Valve Command";
CM_ BO_ 2365469438 "Auxiliary Valve Command";
CM_ BO_ 2365469182 "Auxiliary Valve Command";
CM_ BO_ 2365468926 "Auxiliary Valve Command";
CM_ BO_ 2365468670 "Auxiliary valve measured flow";
CM_ SG_ 2365468670 Valve15LimitStatus "Parameter used to report the tractor ECUs present limit status associated with a parameter whose commands are persistent";
CM_ BO_ 2365468414 "Auxiliary valve measured flow";
CM_ SG_ 2365468414 Valve14LimitStatus "Parameter used to report the tractor ECUs present limit status associated with a parameter whose commands are persistent";
CM_ BO_ 2365468158 "Auxiliary valve measured flow";
CM_ SG_ 2365468158 Valve13LimitStatus "Parameter used to report the tractor ECUs present limit status associated with a parameter whose commands are persistent";
CM_ BO_ 2365467902 "Auxiliary valve measured flow";
CM_ SG_ 2365467902 Valve12LimitStatus "Parameter used to report the tractor ECUs present limit status associated with a parameter whose commands are persistent";
CM_ BO_ 2365467646 "Auxiliary valve measured flow";
CM_ SG_ 2365467646 Valve11LimitStatus "Parameter used to report the tractor ECUs present limit status associated with a parameter whose commands are persistent";
CM_ BO_ 2365467390 "Auxiliary valve measured flow";
CM_ SG_ 2365467390 Valve10LimitStatus "Parameter used to report the tractor ECUs present limit status associated with a parameter whose commands are persistent";
CM_ BO_ 2365467134 "Auxiliary valve measured flow";
CM_ SG_ 2365467134 Valve9LimitStatus "Parameter used to report the tractor ECUs present limit status associated with a parameter whose commands are persistent";
CM_ BO_ 2365466878 "Auxiliary valve measured flow";
CM_ SG_ 2365466878 Valve8LimitStatus "Parameter used to report the tractor ECUs present limit status associated with a parameter whose commands are persistent";
CM_ BO_ 2365466622 "Auxiliary valve measured flow";
CM_ SG_ 2365466622 Valve7LimitStatus "Parameter used to report the tractor ECUs present limit status associated with a parameter whose commands are persistent";
CM_ BO_ 2365466366 "Auxiliary valve measured flow";
CM_ SG_ 2365466366 Valve6LimitStatus "Parameter used to report the tractor ECUs present limit status associated with a parameter whose commands are persistent";
CM_ BO_ 2365466110 "Auxiliary valve measured flow";
CM_ SG_ 2365466110 Valve5LimitStatus "Parameter used to report the tractor ECUs present limit status associated with a parameter whose commands are persistent";
CM_ BO_ 2365465854 "Auxiliary valve measured flow";
CM_ SG_ 2365465854 Valve4LimitStatus "Parameter used to report the tractor ECUs present limit status associated with a parameter whose commands are persistent";
CM_ BO_ 2365465598 "Auxiliary valve measured flow";
CM_ SG_ 2365465598 Valve3LimitStatus "Parameter used to report the tractor ECUs present limit status associated with a parameter whose commands are persistent";
CM_ BO_ 2365465342 "Auxiliary valve measured flow";
CM_ SG_ 2365465342 Valve2LimitStatus "Parameter used to report the tractor ECUs present limit status associated with a parameter whose commands are persistent";
BA_DEF_ SG_  "DDI" INT 0 65535;
BA_DEF_ BO_  "SingleFrame" INT 0 1;
BA_DEF_ BO_  "VFrameFormat" ENUM  "StandardCAN","ExtendedCAN","reserved","J1939PG","vector_leerstring";
BA_DEF_ BO_  "GenMsgSendType" ENUM  "cyclic","NotUsed","IfActive","NotUsed","NotUsed","NotUsed","NotUsed","NotUsed","noMsgSendType","vector_leerstring";
BA_DEF_ BO_  "GenMsgCycleTime" INT 0 3600000;
BA_DEF_ BO_  "GenMsgRequestable" INT 0 1;
BA_DEF_ BO_  "GenMsgCycleTimeFast" INT 0 3600000;
BA_DEF_ SG_  "SPN" INT 0 524287;
BA_DEF_ SG_  "GenSigSendType" ENUM  "Cyclic","OnWrite","OnWriteWithRepetition","OnChange","OnChangeWithRepetition","IfActive","IfActiveWithRepetition","NoSigSendType";
BA_DEF_ SG_  "SigType" ENUM  "Default","Range","RangeSigned","ASCII","Discrete","Control","ReferencePGN","DTC","StringDelimiter","StringLength","StringLengthControl","MessageCounter","MessageChecksum";
BA_DEF_ SG_  "GenSigStartValue" INT -2147483648 2147483647;
BA_DEF_ SG_  "SystemSignalLongSymbol" STRING ;
BA_DEF_DEF_  "DDI" 0;
BA_DEF_DEF_  "SingleFrame" 1;
BA_DEF_DEF_  "VFrameFormat" "J1939PG";
BA_DEF_DEF_  "GenMsgSendType" "noMsgSendType";
BA_DEF_DEF_  "GenMsgCycleTime" 0;
BA_DEF_DEF_  "GenMsgRequestable" 1;
BA_DEF_DEF_  "GenMsgCycleTimeFast" 0;
BA_DEF_DEF_  "SPN" 0;
BA_DEF_DEF_  "GenSigSendType" "NoSigSendType";
BA_DEF_DEF_  "SigType" "Default";
BA_DEF_DEF_  "GenSigStartValue" 0;
BA_DEF_DEF_  "SystemSignalLongSymbol" "";
BA_ "GenMsgSendType" BO_ 2565340800 2;
BA_ "GenMsgCycleTime" BO_ 2565340800 1000;
BA_ "GenMsgCycleTime" BO_ 2365475073 100;
BA_ "GenMsgSendType" BO_ 2365475073 0;
BA_ "GenMsgSendType" BO_ 2364597502 0;
BA_ "GenMsgCycleTime" BO_ 2364597502 100;
BA_ "GenMsgSendType" BO_ 2360147710 8.48332452797837E-317;
BA_ "GenMsgCycleTime" BO_ 2360147710 100;
BA_ "GenMsgSendType" BO_ 2360213246 8.48390950170305E-317;
BA_ "GenMsgCycleTime" BO_ 2360213246 100;
BA_ "GenMsgSendType" BO_ 2563047166 8.48466048148473E-317;
BA_ "GenMsgCycleTime" BO_ 2563047166 1000;
BA_ "GenMsgSendType" BO_ 2563112702 8.48555770469758E-317;
BA_ "GenMsgCycleTime" BO_ 2563112702 100;
BA_ "GenMsgSendType" BO_ 2563178238 8.48652212083826E-317;
BA_ "GenMsgCycleTime" BO_ 2563178238 100;
BA_ "GenMsgSendType" BO_ 2314732030 8.51951780093012E-317;
BA_ "GenMsgCycleTime" BO_ 2314732030 100;
BA_ "GenMsgSendType" BO_ 2583168510 8.52390115134002E-317;
BA_ "GenMsgCycleTime" BO_ 2583168510 100;
BA_ "SingleFrame" BO_ 2583168510 0;
BA_ "GenMsgSendType" BO_ 2583299838 8.52558097453588E-317;
BA_ "GenMsgCycleTime" BO_ 2583299838 1000;
BA_ "SingleFrame" BO_ 2583299838 0;
BA_ "GenMsgSendType" BO_ 2566849534 8.52715012702708E-317;
BA_ "GenMsgCycleTime" BO_ 2566849534 100;
BA_ "GenMsgSendType" BO_ 2566849278 8.52871927951827E-317;
BA_ "GenMsgCycleTime" BO_ 2566849278 100;
BA_ "GenMsgSendType" BO_ 2566849022 8.53028843200946E-317;
BA_ "GenMsgCycleTime" BO_ 2566849022 100;
BA_ "GenMsgSendType" BO_ 2566848766 8.53185758450065E-317;
BA_ "GenMsgCycleTime" BO_ 2566848766 100;
BA_ "GenMsgSendType" BO_ 2365475326 8.53594844804822E-317;
BA_ "GenMsgCycleTime" BO_ 2365475326 100;
BA_ "GenMsgSendType" BO_ 2365475070 8.53733973690691E-317;
BA_ "GenMsgCycleTime" BO_ 2365475070 100;
BA_ "GenMsgCycleTime" BO_ 2566801406 100;
BA_ "GenMsgSendType" BO_ 2365474558 8.53967963180561E-317;
BA_ "GenMsgCycleTime" BO_ 2365474558 100;
BA_ "GenMsgSendType" BO_ 2365474302 8.54054523481712E-317;
BA_ "GenMsgCycleTime" BO_ 2365474302 100;
BA_ "GenMsgSendType" BO_ 2365474046 2;
BA_ "GenMsgCycleTime" BO_ 2365474046 100;
BA_ "GenMsgSendType" BO_ 2365473790 2;
BA_ "GenMsgCycleTime" BO_ 2365473790 100;
BA_ "GenMsgSendType" BO_ 2365473534 8.54526850239137E-317;
BA_ "GenMsgCycleTime" BO_ 2365473534 1000;
BA_ "GenMsgCycleTime" BO_ 2365473278 100;
BA_ "GenMsgCycleTime" BO_ 2566799614 100;
BA_ "GenMsgSendType" BO_ 2365472766 8.56219716768047E-317;
BA_ "GenMsgCycleTime" BO_ 2365472766 1000;
BA_ "GenMsgSendType" BO_ 2365472510 8.56296395756282E-317;
BA_ "GenMsgCycleTime" BO_ 2365472510 1000;
BA_ "GenMsgSendType" BO_ 2365472254 8.56373074744516E-317;
BA_ "GenMsgCycleTime" BO_ 2365472254 1000;
BA_ "GenMsgSendType" BO_ 2365471998 8.56449753732751E-317;
BA_ "GenMsgCycleTime" BO_ 2365471998 1000;
BA_ "GenMsgSendType" BO_ 2365471742 8.56526432720985E-317;
BA_ "GenMsgCycleTime" BO_ 2365471742 1000;
BA_ "GenMsgSendType" BO_ 2365471486 8.5660311170922E-317;
BA_ "GenMsgCycleTime" BO_ 2365471486 1000;
BA_ "GenMsgSendType" BO_ 2365471230 8.56679790697454E-317;
BA_ "GenMsgCycleTime" BO_ 2365471230 1000;
BA_ "GenMsgSendType" BO_ 2365470974 8.56756469685689E-317;
BA_ "GenMsgCycleTime" BO_ 2365470974 1000;
BA_ "GenMsgSendType" BO_ 2365470718 8.5683354392644E-317;
BA_ "GenMsgCycleTime" BO_ 2365470718 1000;
BA_ "GenMsgSendType" BO_ 2365470462 8.56910222914675E-317;
BA_ "GenMsgCycleTime" BO_ 2365470462 1000;
BA_ "GenMsgSendType" BO_ 2365470206 8.56986901902909E-317;
BA_ "GenMsgCycleTime" BO_ 2365470206 1000;
BA_ "GenMsgSendType" BO_ 2365469950 8.57063976143661E-317;
BA_ "GenMsgCycleTime" BO_ 2365469950 1000;
BA_ "GenMsgSendType" BO_ 2365469694 8.57140655131895E-317;
BA_ "GenMsgCycleTime" BO_ 2365469694 1000;
BA_ "GenMsgSendType" BO_ 2365469438 8.5721733412013E-317;
BA_ "GenMsgCycleTime" BO_ 2365469438 1000;
BA_ "GenMsgSendType" BO_ 2365469182 8.57294013108364E-317;
BA_ "GenMsgCycleTime" BO_ 2365469182 1000;
BA_ "GenMsgSendType" BO_ 2365468926 8.57370692096599E-317;
BA_ "GenMsgCycleTime" BO_ 2365468926 1000;
BA_ "GenMsgSendType" BO_ 2365468670 8.5746199542795E-317;
BA_ "GenMsgCycleTime" BO_ 2365468670 100;
BA_ "GenMsgSendType" BO_ 2365468414 8.57553298759302E-317;
BA_ "GenMsgCycleTime" BO_ 2365468414 100;
BA_ "GenMsgSendType" BO_ 2365468158 8.5764499734317E-317;
BA_ "GenMsgCycleTime" BO_ 2365468158 100;
BA_ "GenMsgSendType" BO_ 2365467902 8.57736300674521E-317;
BA_ "GenMsgCycleTime" BO_ 2365467902 100;
BA_ "GenMsgSendType" BO_ 2365467646 8.57827604005873E-317;
BA_ "GenMsgCycleTime" BO_ 2365467646 100;
BA_ "GenMsgSendType" BO_ 2365467390 8.57918907337224E-317;
BA_ "GenMsgCycleTime" BO_ 2365467390 100;
BA_ "GenMsgSendType" BO_ 2365467134 8.58010210668576E-317;
BA_ "GenMsgCycleTime" BO_ 2365467134 100;
BA_ "GenMsgSendType" BO_ 2365466878 8.58101513999927E-317;
BA_ "GenMsgCycleTime" BO_ 2365466878 100;
BA_ "GenMsgSendType" BO_ 2365466622 8.58192817331279E-317;
BA_ "GenMsgCycleTime" BO_ 2365466622 100;
BA_ "GenMsgSendType" BO_ 2365466366 8.58284515915147E-317;
BA_ "GenMsgCycleTime" BO_ 2365466366 100;
BA_ "GenMsgSendType" BO_ 2365466110 8.58375819246498E-317;
BA_ "GenMsgCycleTime" BO_ 2365466110 100;
BA_ "GenMsgSendType" BO_ 2365465854 8.5846712257785E-317;
BA_ "GenMsgCycleTime" BO_ 2365465854 100;
BA_ "GenMsgSendType" BO_ 2365465598 8.58558425909201E-317;
BA_ "GenMsgCycleTime" BO_ 2365465598 100;
BA_ "GenMsgSendType" BO_ 2365465342 8.58649729240553E-317;
BA_ "GenMsgCycleTime" BO_ 2365465342 100;
BA_ "SPN" SG_ 2565340800 ArbitraryAddressCapable 2844;
BA_ "SPN" SG_ 2565340800 IndustryGroup 2846;
BA_ "SPN" SG_ 2565340800 VehicleSystemInstance 2843;
BA_ "SPN" SG_ 2565340800 Function 2841;
BA_ "SPN" SG_ 2565340800 FunctionInstance 2839;
BA_ "SPN" SG_ 2565340800 ECUInstance 2840;
BA_ "SigType" SG_ 2565340800 NewStringValue 9;
BA_ "SigType" SG_ 2565340800 ManufacturerCode 1;
BA_ "SPN" SG_ 2565340800 ManufacturerCode 2838;
BA_ "SPN" SG_ 2565340800 IdentityNumber 2837;
BA_ "SigType" SG_ 2565340800 ExtendedVersionLabelToDelete 3;
BA_ "SigType" SG_ 2565340800 ExtendedVersionLabelToLoad 3;
BA_ "SigType" SG_ 2565340800 ExtendedVersionLabelToStore 3;
BA_ "SigType" SG_ 2565340800 VersionLabelToDelete 3;
BA_ "SigType" SG_ 2565340800 VersionLabelToLoad 3;
BA_ "SigType" SG_ 2565340800 VersionLabelToStore 3;
BA_ "SystemSignalLongSymbol" SG_ 2565340800 ChangeChildLocationParentOb_0000 "ChangeChildLocationParentObjectID";
BA_ "SystemSignalLongSymbol" SG_ 2565340800 ChangeChildPositionParentOb_0000 "ChangeChildPositionParentObjectID";
BA_ "SPN" SG_ 2565799552 ArbitraryAddressCapable 2844;
BA_ "SPN" SG_ 2565799552 IndustryGroup 2846;
BA_ "SPN" SG_ 2565799552 VehicleSystemInstance 2843;
BA_ "SPN" SG_ 2565799552 Function 2841;
BA_ "SPN" SG_ 2565799552 FunctionInstance 2839;
BA_ "SPN" SG_ 2565799552 ECUInstance 2840;
BA_ "SigType" SG_ 2565799552 ManufacturerCode 1;
BA_ "SPN" SG_ 2565799552 ManufacturerCode 2838;
BA_ "SPN" SG_ 2565799552 IdentityNumber 2837;
BA_ "SigType" SG_ 2365475073 GroundBasedMachineDirection 4;
BA_ "SPN" SG_ 2365475073 GroundBasedMachineDirection 1861;
BA_ "SigType" SG_ 2365475073 GroundBasedMachineDistance 1;
BA_ "SPN" SG_ 2365475073 GroundBasedMachineDistance 1860;
BA_ "SigType" SG_ 2365475073 GroundBasedMachineSpeed 1;
BA_ "SPN" SG_ 2365475073 GroundBasedMachineSpeed 1859;
BA_ "SPN" SG_ 2364597502 HeartbeatSequenceNumber 7345;
BA_ "SigType" SG_ 2364597502 HeartbeatSequenceNumber 1;
BA_ "SPN" SG_ 2360147710 GuidSysComExitReasonCode 5725;
BA_ "SPN" SG_ 2360147710 GuidanceLimitStatus 5726;
BA_ "SigType" SG_ 2360147710 RequestResetCommandStatus 4;
BA_ "SPN" SG_ 2360147710 RequestResetCommandStatus 5240;
BA_ "SigType" SG_ 2360147710 SteeringInputPositionStatus 4;
BA_ "SPN" SG_ 2360147710 SteeringInputPositionStatus 5241;
BA_ "SigType" SG_ 2360147710 SteeringSystemReadiness 4;
BA_ "SPN" SG_ 2360147710 SteeringSystemReadiness 5242;
BA_ "SigType" SG_ 2360147710 MechanicalSystemLockout 4;
BA_ "SPN" SG_ 2360147710 MechanicalSystemLockout 5243;
BA_ "SigType" SG_ 2360147710 EstimatedCurvature 1;
BA_ "SPN" SG_ 2360147710 EstimatedCurvature 5238;
BA_ "SigType" SG_ 2360213246 CurvatureCommandStatus 4;
BA_ "SPN" SG_ 2360213246 CurvatureCommandStatus 5239;
BA_ "SigType" SG_ 2360213246 CurvatureCommand 1;
BA_ "SPN" SG_ 2360213246 CurvatureCommand 5237;
BA_ "SigType" SG_ 2563047166 FailSaveModeCmd 4;
BA_ "SPN" SG_ 2563047166 StateCmd 2933;
BA_ "SPN" SG_ 2563047166 PortFlowCmd 2944;
BA_ "SigType" SG_ 2563047166 PortFlowCmd 1;
BA_ "SPN" SG_ 2563112702 ValveLimitStatus 5192;
BA_ "SPN" SG_ 2563112702 ReturnPortPressure 2943;
BA_ "SigType" SG_ 2563112702 ReturnPortPressure 1;
BA_ "SPN" SG_ 2563112702 RetractPortPressure 2942;
BA_ "SigType" SG_ 2563112702 RetractPortPressure 1;
BA_ "SPN" SG_ 2563112702 ExtendedPortPressure 2941;
BA_ "SigType" SG_ 2563112702 ExtendedPortPressure 1;
BA_ "SPN" SG_ 2563112702 RetractPortMeasuredFlow 2938;
BA_ "SigType" SG_ 2563112702 RetractPortMeasuredFlow 1;
BA_ "SPN" SG_ 2563112702 ExtendedPortMeasuredFlow 2937;
BA_ "SigType" SG_ 2563112702 ExtendedPortMeasuredFlow 1;
BA_ "SPN" SG_ 2563178238 ValveLimitStatus 5193;
BA_ "SPN" SG_ 2563178238 FailSafeMode 2934;
BA_ "SigType" SG_ 2563178238 FailSafeMode 4;
BA_ "SPN" SG_ 2563178238 ValveState 2932;
BA_ "SPN" SG_ 2563178238 RetractPortEstimatedFlow 2940;
BA_ "SigType" SG_ 2563178238 RetractPortEstimatedFlow 1;
BA_ "SPN" SG_ 2563178238 ExtendedPortEstimatedFlow 2939;
BA_ "SigType" SG_ 2563178238 ExtendedPortEstimatedFlow 1;
BA_ "SigType" SG_ 2628452094 VI_VolumeName 9;
BA_ "SigType" SG_ 2628452094 OF_PathName 9;
BA_ "SigType" SG_ 2628452094 DF_PathName 9;
BA_ "SigType" SG_ 2628452094 SA_PathName 9;
BA_ "SigType" SG_ 2628452094 CCD_PathName 9;
BA_ "SigType" SG_ 2628452094 GA_PathName 9;
BA_ "SigType" SG_ 2628452094 FDT_PathName 9;
BA_ "SigType" SG_ 2628452094 VS_VolumeName 8;
BA_ "SystemSignalLongSymbol" SG_ 2628452094 VS_RequestVolumeToPrepareForRemo "VS_RequestVolumeToPrepareForRemoval";
BA_ "SigType" SG_ 2628517630 GCD_PathName 9;
BA_ "SigType" SG_ 2628517630 VS_VolumeName 9;
BA_ "SPN" SG_ 2364540158 EngDemandPercentTorque 2432;
BA_ "SigType" SG_ 2364540158 EngDemandPercentTorque 1;
BA_ "SPN" SG_ 2364540158 EngStarterMode 1675;
BA_ "SPN" SG_ 2364540158 SrcAddrssOfCtrllngDvcForEngCtrl 1483;
BA_ "SPN" SG_ 2364540158 EngSpeed 190;
BA_ "SigType" SG_ 2364540158 EngSpeed 1;
BA_ "SPN" SG_ 2364540158 ActualEngPercentTorque 513;
BA_ "SigType" SG_ 2364540158 ActualEngPercentTorque 1;
BA_ "SPN" SG_ 2364540158 DriversDemandEngPercentTorque 512;
BA_ "SigType" SG_ 2364540158 DriversDemandEngPercentTorque 1;
BA_ "SPN" SG_ 2364540158 EngTorqueMode 899;
BA_ "SPN" SG_ 2364540158 ActlEngPrcntTorqueHighResolution 4154;
BA_ "SigType" SG_ 2563243774 Byte7 1;
BA_ "SigType" SG_ 2563243774 Byte6 1;
BA_ "SigType" SG_ 2563243774 Byte5 1;
BA_ "SigType" SG_ 2563243774 Byte4 1;
BA_ "SigType" SG_ 2563243774 Byte3 1;
BA_ "SigType" SG_ 2563243774 Byte2 1;
BA_ "SigType" SG_ 2563243774 Byte1 1;
BA_ "SigType" SG_ 2563243774 SequenceNumber 1;
BA_ "GenSigStartValue" SG_ 2563243774 SequenceNumber 1;
BA_ "SigType" SG_ 2563309310 PGNumber 6;
BA_ "SigType" SG_ 2563309310 DataPacketOffset 1;
BA_ "SigType" SG_ 2563309310 NextPacketNumberToSend 1;
BA_ "GenSigStartValue" SG_ 2563309310 NextPacketNumberToSend 1;
BA_ "SigType" SG_ 2563309310 NumberOfBytesTransfered 1;
BA_ "GenSigStartValue" SG_ 2563309310 NumberOfBytesTransfered 1786;
BA_ "SigType" SG_ 2563309310 NumberOfPacketsOffset 1;
BA_ "GenSigStartValue" SG_ 2563309310 NumberOfPacketsOffset 1;
BA_ "SigType" SG_ 2563309310 NumberOfPacketsToSend 1;
BA_ "GenSigStartValue" SG_ 2563309310 NumberOfPacketsToSend 1;
BA_ "SigType" SG_ 2563309310 NumberOfBytesToTransfer 1;
BA_ "GenSigStartValue" SG_ 2563309310 NumberOfBytesToTransfer 1786;
BA_ "SigType" SG_ 2563309310 ControlByte 1;
BA_ "SigType" SG_ 2583168510 AgeOfDGNSSCorrections1 1;
BA_ "SigType" SG_ 2583168510 ReferenceStationID1 1;
BA_ "SigType" SG_ 2583168510 NumberOfReferenceStations 1;
BA_ "SigType" SG_ 2583168510 GeoidalSeparation 2;
BA_ "SigType" SG_ 2583168510 PDOP 2;
BA_ "SigType" SG_ 2583168510 HDOP 2;
BA_ "SigType" SG_ 2583168510 NumberOfSVs 1;
BA_ "SigType" SG_ 2583168510 GNSSIntegrity 4;
BA_ "SigType" SG_ 2583168510 LongitudeLow 1;
BA_ "SigType" SG_ 2583168510 LatitudeLow 1;
BA_ "SigType" SG_ 2583168510 PositionTime 1;
BA_ "SigType" SG_ 2583168510 PositionDate 1;
BA_ "SigType" SG_ 2583168510 SequenceID 1;
BA_ "SigType" SG_ 2583299838 STDofAltError 1;
BA_ "SigType" SG_ 2583299838 STDofLonError 1;
BA_ "SigType" SG_ 2583299838 STDofLatError 1;
BA_ "SigType" SG_ 2583299838 OrientationOfMinorAxis 1;
BA_ "SigType" SG_ 2583299838 STDofMinorAxis 1;
BA_ "SigType" SG_ 2583299838 STDofMajorAxis 1;
BA_ "SigType" SG_ 2583299838 RMSofPositionUncertainty 1;
BA_ "SigType" SG_ 2583299838 SequenceID 1;
BA_ "SigType" SG_ 2566849534 ManufacturerSpecific8 1;
BA_ "SigType" SG_ 2566849534 ManufacturerSpecific7 1;
BA_ "SigType" SG_ 2566849534 ManufacturerSpecific6 1;
BA_ "SigType" SG_ 2566849534 ManufacturerSpecific5 1;
BA_ "SigType" SG_ 2566849534 ManufacturerSpecific4 1;
BA_ "SigType" SG_ 2566849534 ManufacturerSpecific3 1;
BA_ "SigType" SG_ 2566849534 ManufacturerSpecific2 1;
BA_ "SigType" SG_ 2566849534 ManufacturerSpecific1 1;
BA_ "SigType" SG_ 2566849278 ManufacturerSpecific8 1;
BA_ "SigType" SG_ 2566849278 ManufacturerSpecific7 1;
BA_ "SigType" SG_ 2566849278 ManufacturerSpecific6 1;
BA_ "SigType" SG_ 2566849278 ManufacturerSpecific5 1;
BA_ "SigType" SG_ 2566849278 ManufacturerSpecific4 1;
BA_ "SigType" SG_ 2566849278 ManufacturerSpecific3 1;
BA_ "SigType" SG_ 2566849278 ManufacturerSpecific2 1;
BA_ "SigType" SG_ 2566849278 ManufacturerSpecific1 1;
BA_ "SigType" SG_ 2566849022 ManufacturerSpecific8 1;
BA_ "SigType" SG_ 2566849022 ManufacturerSpecific7 1;
BA_ "SigType" SG_ 2566849022 ManufacturerSpecific6 1;
BA_ "SigType" SG_ 2566849022 ManufacturerSpecific5 1;
BA_ "SigType" SG_ 2566849022 ManufacturerSpecific4 1;
BA_ "SigType" SG_ 2566849022 ManufacturerSpecific3 1;
BA_ "SigType" SG_ 2566849022 ManufacturerSpecific2 1;
BA_ "SigType" SG_ 2566849022 ManufacturerSpecific1 1;
BA_ "SigType" SG_ 2566848766 ManufacturerSpecific8 1;
BA_ "SigType" SG_ 2566848766 ManufacturerSpecific7 1;
BA_ "SigType" SG_ 2566848766 ManufacturerSpecific6 1;
BA_ "SigType" SG_ 2566848766 ManufacturerSpecific5 1;
BA_ "SigType" SG_ 2566848766 ManufacturerSpecific4 1;
BA_ "SigType" SG_ 2566848766 ManufacturerSpecific3 1;
BA_ "SigType" SG_ 2566848766 ManufacturerSpecific2 1;
BA_ "SigType" SG_ 2566848766 ManufacturerSpecific1 1;
BA_ "SigType" SG_ 2566842110 LocalHourOffset 1;
BA_ "SPN" SG_ 2566842110 LocalHourOffset 1602;
BA_ "SigType" SG_ 2566842110 LocalMinuteOffset 1;
BA_ "SPN" SG_ 2566842110 LocalMinuteOffset 1601;
BA_ "SigType" SG_ 2566842110 Year 1;
BA_ "SPN" SG_ 2566842110 Year 964;
BA_ "SigType" SG_ 2566842110 Day 1;
BA_ "SPN" SG_ 2566842110 Day 962;
BA_ "SigType" SG_ 2566842110 Month 1;
BA_ "SPN" SG_ 2566842110 Month 963;
BA_ "SigType" SG_ 2566842110 Hours 1;
BA_ "SPN" SG_ 2566842110 Hours 961;
BA_ "SigType" SG_ 2566842110 Minutes 1;
BA_ "SPN" SG_ 2566842110 Minutes 960;
BA_ "SigType" SG_ 2566842110 Seconds 1;
BA_ "SPN" SG_ 2566842110 Seconds 959;
BA_ "SigType" SG_ 2365475326 GroundBasedMachineDirection 4;
BA_ "SPN" SG_ 2365475326 GroundBasedMachineDirection 1861;
BA_ "SigType" SG_ 2365475326 GroundBasedMachineDistance 1;
BA_ "SPN" SG_ 2365475326 GroundBasedMachineDistance 1860;
BA_ "SigType" SG_ 2365475326 GroundBasedMachineSpeed 1;
BA_ "SPN" SG_ 2365475326 GroundBasedMachineSpeed 1859;
BA_ "SigType" SG_ 2365475070 OperatorDirectionReversed 5;
BA_ "SPN" SG_ 2365475070 OperatorDirectionReversed 5244;
BA_ "SigType" SG_ 2365475070 StartStopState 4;
BA_ "SPN" SG_ 2365475070 StartStopState 5203;
BA_ "SigType" SG_ 2365475070 KeySwitchState 4;
BA_ "SPN" SG_ 2365475070 KeySwitchState 1865;
BA_ "SigType" SG_ 2365475070 WheelBasedMachineDirection 4;
BA_ "SPN" SG_ 2365475070 WheelBasedMachineDirection 1864;
BA_ "SigType" SG_ 2365475070 MaxTimeOfTractorPower 1;
BA_ "SPN" SG_ 2365475070 MaxTimeOfTractorPower 1866;
BA_ "SigType" SG_ 2365475070 WheelBasedMachineDistance 1;
BA_ "SPN" SG_ 2365475070 WheelBasedMachineDistance 1863;
BA_ "SigType" SG_ 2365475070 WheelBasedMachineSpeed 1;
BA_ "SPN" SG_ 2365475070 WheelBasedMachineSpeed 1862;
BA_ "SPN" SG_ 2566801406 ImplementInWorkState 7447;
BA_ "SigType" SG_ 2566801406 ImplementInWorkState 4;
BA_ "SigType" SG_ 2566801406 ImplementTransportState 4;
BA_ "SPN" SG_ 2566801406 ImplementTransportState 1869;
BA_ "SigType" SG_ 2566801406 ImplementParkState 4;
BA_ "SPN" SG_ 2566801406 ImplementParkState 1870;
BA_ "SigType" SG_ 2566801406 ImplementReadyToWorkState 4;
BA_ "SPN" SG_ 2566801406 ImplementReadyToWorkState 1871;
BA_ "SigType" SG_ 2566801406 MaintainECUPower 4;
BA_ "SPN" SG_ 2566801406 MaintainECUPower 1867;
BA_ "SigType" SG_ 2566801406 MaintainActuatorPower 4;
BA_ "SPN" SG_ 2566801406 MaintainActuatorPower 1868;
BA_ "SPN" SG_ 2365474558 FrontHitchExitReasonCode 5816;
BA_ "SigType" SG_ 2365474558 FrontDraft 1;
BA_ "SPN" SG_ 2365474558 FrontDraft 1878;
BA_ "SigType" SG_ 2365474558 FrontNominalLowerLinkForce 1;
BA_ "SPN" SG_ 2365474558 FrontNominalLowerLinkForce 1880;
BA_ "SigType" SG_ 2365474558 FrontHitchInWorkIndication 4;
BA_ "SPN" SG_ 2365474558 FrontHitchInWorkIndication 1876;
BA_ "SPN" SG_ 2365474558 FrontHitchPositionLimitStatus 5150;
BA_ "SigType" SG_ 2365474558 FrontHitchPosition 1;
BA_ "SPN" SG_ 2365474558 FrontHitchPosition 1872;
BA_ "SPN" SG_ 2365474302 RearHitchExitReasonCode 5819;
BA_ "SigType" SG_ 2365474302 RearDraft 1;
BA_ "SPN" SG_ 2365474302 RearDraft 1879;
BA_ "SigType" SG_ 2365474302 RearNominalPowerLinkForce 1;
BA_ "SPN" SG_ 2365474302 RearNominalPowerLinkForce 1881;
BA_ "SigType" SG_ 2365474302 RearHitchInWorkIndication 4;
BA_ "SPN" SG_ 2365474302 RearHitchInWorkIndication 1877;
BA_ "SPN" SG_ 2365474302 RearHitchPositionLimitStatus 5151;
BA_ "SigType" SG_ 2365474302 RearHitchPosition 1;
BA_ "SPN" SG_ 2365474302 RearHitchPosition 1873;
BA_ "SPN" SG_ 2365474046 FrontPTOExitReasonCode 5817;
BA_ "SigType" SG_ 2365474046 FrontPTOModeRqStatus 4;
BA_ "SPN" SG_ 2365474046 FrontPTOModeRqStatus 5153;
BA_ "SigType" SG_ 2365474046 FrontPTOEconomyModeRqStatus 4;
BA_ "SPN" SG_ 2365474046 FrontPTOEconomyModeRqStatus 5154;
BA_ "SPN" SG_ 2365474046 FrontPTOShaftSpeedLimitStatus 5155;
BA_ "SigType" SG_ 2365474046 FrontPTOEngagement 4;
BA_ "SPN" SG_ 2365474046 FrontPTOEngagement 1888;
BA_ "SigType" SG_ 2365474046 FrontPTOMode 4;
BA_ "SPN" SG_ 2365474046 FrontPTOMode 1889;
BA_ "SigType" SG_ 2365474046 FrontPTOEconomyMode 4;
BA_ "SPN" SG_ 2365474046 FrontPTOEconomyMode 1891;
BA_ "SigType" SG_ 2365474046 FrontPTOEngagementRqStatus 4;
BA_ "SPN" SG_ 2365474046 FrontPTOEngagementRqStatus 5152;
BA_ "SigType" SG_ 2365474046 FrontPTOOutShaftSpeedSetPoint 1;
BA_ "SPN" SG_ 2365474046 FrontPTOOutShaftSpeedSetPoint 1884;
BA_ "SigType" SG_ 2365474046 FrontPTOOutShaftSpeed 1;
BA_ "SPN" SG_ 2365474046 FrontPTOOutShaftSpeed 1882;
BA_ "SPN" SG_ 2365473790 RearPTOExitReasonCode 5820;
BA_ "SigType" SG_ 2365473790 RearPTOModeRqStatus 4;
BA_ "SPN" SG_ 2365473790 RearPTOModeRqStatus 5157;
BA_ "SigType" SG_ 2365473790 RearPTOEconomyModeRqStatus 4;
BA_ "SPN" SG_ 2365473790 RearPTOEconomyModeRqStatus 5158;
BA_ "SPN" SG_ 2365473790 RearPTOShaftSpeedLimitStatus 5159;
BA_ "SigType" SG_ 2365473790 RearPTOEngagement 4;
BA_ "SPN" SG_ 2365473790 RearPTOEngagement 2408;
BA_ "SigType" SG_ 2365473790 RearPTOMode 4;
BA_ "SPN" SG_ 2365473790 RearPTOMode 1890;
BA_ "SigType" SG_ 2365473790 RearPTOEconomyMode 4;
BA_ "SPN" SG_ 2365473790 RearPTOEconomyMode 1892;
BA_ "SigType" SG_ 2365473790 RearPTOEngagementRqStatus 4;
BA_ "SPN" SG_ 2365473790 RearPTOEngagementRqStatus 5156;
BA_ "SigType" SG_ 2365473790 RearPTOOutputShaftSpeedSetPoint 1;
BA_ "SPN" SG_ 2365473790 RearPTOOutputShaftSpeedSetPoint 1885;
BA_ "SigType" SG_ 2365473790 RearPTOOutputShaftSpeed 1;
BA_ "SPN" SG_ 2365473790 RearPTOOutputShaftSpeed 1883;
BA_ "SigType" SG_ 2365473534 FrontPTOModeCmd 4;
BA_ "SPN" SG_ 2365473534 FrontPTOModeCmd 1895;
BA_ "SigType" SG_ 2365473534 RearPTOModeCmd 4;
BA_ "SPN" SG_ 2365473534 RearPTOModeCmd 1896;
BA_ "SigType" SG_ 2365473534 FrontPTOEconomyModeCmd 4;
BA_ "SPN" SG_ 2365473534 FrontPTOEconomyModeCmd 1897;
BA_ "SigType" SG_ 2365473534 RearPTOEconomyModeCmd 4;
BA_ "SPN" SG_ 2365473534 RearPTOEconomyModeCmd 1898;
BA_ "SigType" SG_ 2365473534 FrontPTOEngagementCmd 4;
BA_ "SPN" SG_ 2365473534 FrontPTOEngagementCmd 1893;
BA_ "SigType" SG_ 2365473534 RearPTOEngagementCmd 4;
BA_ "SPN" SG_ 2365473534 RearPTOEngagementCmd 1894;
BA_ "SigType" SG_ 2365473534 RearPTOOutShaftSpeedSetPointCmd 1;
BA_ "SPN" SG_ 2365473534 RearPTOOutShaftSpeedSetPointCmd 1887;
BA_ "SigType" SG_ 2365473534 FrontPTOOutShaftSpeedSetPointCmd 1;
BA_ "SPN" SG_ 2365473534 FrontPTOOutShaftSpeedSetPointCmd 1886;
BA_ "SigType" SG_ 2365473534 RearHitchPositionCmd 1;
BA_ "SPN" SG_ 2365473534 RearHitchPositionCmd 1875;
BA_ "SigType" SG_ 2365473534 FrontHitchPositionCmd 1;
BA_ "SPN" SG_ 2365473534 FrontHitchPositionCmd 1874;
BA_ "SPN" SG_ 2365473278 ImplementRearWorkLightCmd 2405;
BA_ "SigType" SG_ 2365473278 ImplementRearWorkLightCmd 4;
BA_ "SPN" SG_ 2365473278 ImplementLeftFacingWorkLightCmd 2399;
BA_ "SigType" SG_ 2365473278 ImplementLeftFacingWorkLightCmd 4;
BA_ "SPN" SG_ 2365473278 ImplementRightFacingWorkLightCmd 2401;
BA_ "SigType" SG_ 2365473278 ImplementRightFacingWorkLightCmd 4;
BA_ "SPN" SG_ 2365473278 LightingDataRequestCmd 2393;
BA_ "SigType" SG_ 2365473278 LightingDataRequestCmd 4;
BA_ "SPN" SG_ 2365473278 ImplementLeftForwardLightCmd 2597;
BA_ "SigType" SG_ 2365473278 ImplementLeftForwardLightCmd 4;
BA_ "SPN" SG_ 2365473278 ImplementRightForwardLightCmd 2406;
BA_ "SigType" SG_ 2365473278 ImplementRightForwardLightCmd 4;
BA_ "SPN" SG_ 2365473278 ImplementOEMOption1LightCmd 2395;
BA_ "SigType" SG_ 2365473278 ImplementOEMOption1LightCmd 4;
BA_ "SPN" SG_ 2365473278 ImplementOEMOption2LightCmd 2397;
BA_ "SigType" SG_ 2365473278 ImplementOEMOption2LightCmd 4;
BA_ "SPN" SG_ 2365473278 TractorFrontHighWorkLightCmd 2355;
BA_ "SigType" SG_ 2365473278 TractorFrontHighWorkLightCmd 4;
BA_ "SPN" SG_ 2365473278 TractorFrontLowWorkLightCmd 2353;
BA_ "SigType" SG_ 2365473278 TractorFrontLowWorkLightCmd 4;
BA_ "SPN" SG_ 2365473278 TractorSideHighWorkLightCmd 2365;
BA_ "SigType" SG_ 2365473278 TractorSideHighWorkLightCmd 4;
BA_ "SPN" SG_ 2365473278 TractorSideLowWorkLightCmd 2363;
BA_ "SigType" SG_ 2365473278 TractorSideLowWorkLightCmd 4;
BA_ "SPN" SG_ 2365473278 TractorRearHighWorkLightCmd 2361;
BA_ "SigType" SG_ 2365473278 TractorRearHighWorkLightCmd 4;
BA_ "SPN" SG_ 2365473278 TractorRearLowWorkLightCmd 2359;
BA_ "SigType" SG_ 2365473278 TractorRearLowWorkLightCmd 4;
BA_ "SPN" SG_ 2365473278 TractorUndersideWorkLightCmd 2357;
BA_ "SigType" SG_ 2365473278 TractorUndersideWorkLightCmd 4;
BA_ "SPN" SG_ 2365473278 RearFogLightCmd 2389;
BA_ "SigType" SG_ 2365473278 RearFogLightCmd 4;
BA_ "SPN" SG_ 2365473278 TractorMarkerLightCmd 2377;
BA_ "SigType" SG_ 2365473278 TractorMarkerLightCmd 4;
BA_ "SPN" SG_ 2365473278 ImplementMarkerLightCmd 2379;
BA_ "SigType" SG_ 2365473278 ImplementMarkerLightCmd 4;
BA_ "SPN" SG_ 2365473278 TractorClearanceLightCmd 2381;
BA_ "SigType" SG_ 2365473278 TractorClearanceLightCmd 4;
BA_ "SPN" SG_ 2365473278 ImplementClearanceLightCmd 2383;
BA_ "SigType" SG_ 2365473278 ImplementClearanceLightCmd 4;
BA_ "SPN" SG_ 2365473278 LeftStopLightCmd 2371;
BA_ "SigType" SG_ 2365473278 LeftStopLightCmd 4;
BA_ "SPN" SG_ 2365473278 RightStopLightCmd 2373;
BA_ "SigType" SG_ 2365473278 RightStopLightCmd 4;
BA_ "SPN" SG_ 2365473278 CentreStopLightCmd 2375;
BA_ "SigType" SG_ 2365473278 CentreStopLightCmd 4;
BA_ "SPN" SG_ 2365473278 BackUpLightAndAlarmHornCmd 2391;
BA_ "SigType" SG_ 2365473278 BackUpLightAndAlarmHornCmd 4;
BA_ "SPN" SG_ 2365473278 LeftTurnSignalLightCmd 2367;
BA_ "SigType" SG_ 2365473278 LeftTurnSignalLightCmd 4;
BA_ "SPN" SG_ 2365473278 RightTurnSignalLightCmd 2369;
BA_ "SigType" SG_ 2365473278 RightTurnSignalLightCmd 4;
BA_ "SPN" SG_ 2365473278 RotatingBeaconLightCmd 2385;
BA_ "SigType" SG_ 2365473278 RotatingBeaconLightCmd 4;
BA_ "SPN" SG_ 2365473278 TractorFrontFogLightCmd 2387;
BA_ "SigType" SG_ 2365473278 TractorFrontFogLightCmd 4;
BA_ "SPN" SG_ 2365473278 HighBeamHeadLightCmd 2347;
BA_ "SigType" SG_ 2365473278 HighBeamHeadLightCmd 4;
BA_ "SPN" SG_ 2365473278 LowBeamHeadLightCmd 2349;
BA_ "SigType" SG_ 2365473278 LowBeamHeadLightCmd 4;
BA_ "SPN" SG_ 2365473278 AlternateHeadLightCmd 2351;
BA_ "SigType" SG_ 2365473278 AlternateHeadLightCmd 4;
BA_ "SPN" SG_ 2365473278 DaytimeRunningLightCmd 2403;
BA_ "SigType" SG_ 2365473278 DaytimeRunningLightCmd 4;
BA_ "SPN" SG_ 2566799614 ImplementRearWorkLightData 2394;
BA_ "SigType" SG_ 2566799614 ImplementRearWorkLightData 4;
BA_ "SPN" SG_ 2566799614 ImplLeftFacingWorkLightData 2400;
BA_ "SigType" SG_ 2566799614 ImplLeftFacingWorkLightData 4;
BA_ "SPN" SG_ 2566799614 ImplRightFacingWorkLightData 2402;
BA_ "SigType" SG_ 2566799614 ImplRightFacingWorkLightData 4;
BA_ "SPN" SG_ 2566799614 ImplementLeftForwardLightData 2598;
BA_ "SigType" SG_ 2566799614 ImplementLeftForwardLightData 4;
BA_ "SPN" SG_ 2566799614 ImplementRightForwardLightData 2407;
BA_ "SigType" SG_ 2566799614 ImplementRightForwardLightData 4;
BA_ "SPN" SG_ 2566799614 ImplementOEMOption1LightData 2396;
BA_ "SigType" SG_ 2566799614 ImplementOEMOption1LightData 4;
BA_ "SPN" SG_ 2566799614 ImplementOEMOption2LightData 2398;
BA_ "SigType" SG_ 2566799614 ImplementOEMOption2LightData 4;
BA_ "SPN" SG_ 2566799614 TractorFrontHighWorkLightData 2356;
BA_ "SigType" SG_ 2566799614 TractorFrontHighWorkLightData 4;
BA_ "SPN" SG_ 2566799614 TractorFrontLowWorkLightData 2354;
BA_ "SigType" SG_ 2566799614 TractorFrontLowWorkLightData 4;
BA_ "SPN" SG_ 2566799614 TractorSideHighWorkLightData 2366;
BA_ "SigType" SG_ 2566799614 TractorSideHighWorkLightData 4;
BA_ "SPN" SG_ 2566799614 TractorSideLowWorkLightData 2364;
BA_ "SigType" SG_ 2566799614 TractorSideLowWorkLightData 4;
BA_ "SPN" SG_ 2566799614 TractorRearHighWorkLightData 2362;
BA_ "SigType" SG_ 2566799614 TractorRearHighWorkLightData 4;
BA_ "SPN" SG_ 2566799614 TractorRearLowWorkLightData 2360;
BA_ "SigType" SG_ 2566799614 TractorRearLowWorkLightData 4;
BA_ "SPN" SG_ 2566799614 TractorUndersideWorkLightData 2358;
BA_ "SigType" SG_ 2566799614 TractorUndersideWorkLightData 4;
BA_ "SPN" SG_ 2566799614 RearFogLightData 2390;
BA_ "SigType" SG_ 2566799614 RearFogLightData 4;
BA_ "SPN" SG_ 2566799614 TractorMarkerLightData 2378;
BA_ "SigType" SG_ 2566799614 TractorMarkerLightData 4;
BA_ "SPN" SG_ 2566799614 ImplementMarkerLightData 2380;
BA_ "SigType" SG_ 2566799614 ImplementMarkerLightData 4;
BA_ "SPN" SG_ 2566799614 TractorClearanceLightData 2382;
BA_ "SigType" SG_ 2566799614 TractorClearanceLightData 4;
BA_ "SPN" SG_ 2566799614 ImplementClearanceLightData 2384;
BA_ "SigType" SG_ 2566799614 ImplementClearanceLightData 4;
BA_ "SPN" SG_ 2566799614 LefttStopLightData 2372;
BA_ "SigType" SG_ 2566799614 LefttStopLightData 4;
BA_ "SPN" SG_ 2566799614 RightStopLightData 2374;
BA_ "SigType" SG_ 2566799614 RightStopLightData 4;
BA_ "SPN" SG_ 2566799614 CentreStopLightData 2376;
BA_ "SigType" SG_ 2566799614 CentreStopLightData 4;
BA_ "SPN" SG_ 2566799614 BackUpLightAndAlarmHornData 2392;
BA_ "SigType" SG_ 2566799614 BackUpLightAndAlarmHornData 4;
BA_ "SPN" SG_ 2566799614 LeftTurnSignalLightData 2368;
BA_ "SigType" SG_ 2566799614 LeftTurnSignalLightData 4;
BA_ "SPN" SG_ 2566799614 RightTurnSignalLightData 2370;
BA_ "SigType" SG_ 2566799614 RightTurnSignalLightData 4;
BA_ "SPN" SG_ 2566799614 RotationBeaconLightData 2386;
BA_ "SigType" SG_ 2566799614 RotationBeaconLightData 4;
BA_ "SPN" SG_ 2566799614 TractorFrontFogLightData 2388;
BA_ "SigType" SG_ 2566799614 TractorFrontFogLightData 4;
BA_ "SPN" SG_ 2566799614 HighBeamHeadLightData 2348;
BA_ "SigType" SG_ 2566799614 HighBeamHeadLightData 4;
BA_ "SPN" SG_ 2566799614 LowBeamHeadLightData 2350;
BA_ "SigType" SG_ 2566799614 LowBeamHeadLightData 4;
BA_ "SPN" SG_ 2566799614 AlternateHeadLightData 2352;
BA_ "SigType" SG_ 2566799614 AlternateHeadLightData 4;
BA_ "SPN" SG_ 2566799614 DaytimeRunningLightData 2404;
BA_ "SigType" SG_ 2566799614 DaytimeRunningLightData 4;
BA_ "SPN" SG_ 2365472766 Valve15FailSaveModeCmd 2345;
BA_ "SigType" SG_ 2365472766 Valve15FailSaveModeCmd 4;
BA_ "SPN" SG_ 2365472766 Valve15StateCmd 2344;
BA_ "SPN" SG_ 2365472766 Valve15PortFlowCmd 2343;
BA_ "SigType" SG_ 2365472766 Valve15PortFlowCmd 1;
BA_ "SPN" SG_ 2365472510 Valve14FailSaveModeCmd 2333;
BA_ "SigType" SG_ 2365472510 Valve14FailSaveModeCmd 4;
BA_ "SPN" SG_ 2365472510 Valve14StateCmd 2332;
BA_ "SPN" SG_ 2365472510 Valve14PortFlowCmd 2331;
BA_ "SigType" SG_ 2365472510 Valve14PortFlowCmd 1;
BA_ "SPN" SG_ 2365472254 Valve13FailSaveModeCmd 2321;
BA_ "SigType" SG_ 2365472254 Valve13FailSaveModeCmd 4;
BA_ "SPN" SG_ 2365472254 Valve13StateCmd 2320;
BA_ "SPN" SG_ 2365472254 Valve13PortFlowCmd 2319;
BA_ "SigType" SG_ 2365472254 Valve13PortFlowCmd 1;
BA_ "SPN" SG_ 2365471998 Valve12FailSaveModeCmd 2309;
BA_ "SigType" SG_ 2365471998 Valve12FailSaveModeCmd 4;
BA_ "SPN" SG_ 2365471998 Valve12StateCmd 2308;
BA_ "SPN" SG_ 2365471998 Valve12PortFlowCmd 2307;
BA_ "SigType" SG_ 2365471998 Valve12PortFlowCmd 1;
BA_ "SPN" SG_ 2365471742 Valve11FailSaveModeCmd 2297;
BA_ "SigType" SG_ 2365471742 Valve11FailSaveModeCmd 4;
BA_ "SPN" SG_ 2365471742 Valve11StateCmd 2296;
BA_ "SPN" SG_ 2365471742 Valve11PortFlowCmd 2295;
BA_ "SigType" SG_ 2365471742 Valve11PortFlowCmd 1;
BA_ "SPN" SG_ 2365471486 Valve10FailSaveModeCmd 2285;
BA_ "SigType" SG_ 2365471486 Valve10FailSaveModeCmd 4;
BA_ "SPN" SG_ 2365471486 Valve10StateCmd 2284;
BA_ "SPN" SG_ 2365471486 Valve10PortFlowCmd 2283;
BA_ "SigType" SG_ 2365471486 Valve10PortFlowCmd 1;
BA_ "SPN" SG_ 2365471230 Valve9FailSaveModeCmd 2273;
BA_ "SigType" SG_ 2365471230 Valve9FailSaveModeCmd 4;
BA_ "SPN" SG_ 2365471230 Valve9StateCmd 2272;
BA_ "SPN" SG_ 2365471230 Valve9PortFlowCmd 2271;
BA_ "SigType" SG_ 2365471230 Valve9PortFlowCmd 1;
BA_ "SPN" SG_ 2365470974 Valve8FailSaveModeCmd 2261;
BA_ "SigType" SG_ 2365470974 Valve8FailSaveModeCmd 4;
BA_ "SPN" SG_ 2365470974 Valve8StateCmd 2260;
BA_ "SPN" SG_ 2365470974 Valve8PortFlowCmd 2259;
BA_ "SigType" SG_ 2365470974 Valve8PortFlowCmd 1;
BA_ "SPN" SG_ 2365470718 Valve7FailSaveModeCmd 1993;
BA_ "SigType" SG_ 2365470718 Valve7FailSaveModeCmd 4;
BA_ "SPN" SG_ 2365470718 Valve7StateCmd 1992;
BA_ "SPN" SG_ 2365470718 Valve7PortFlowCmd 1991;
BA_ "SigType" SG_ 2365470718 Valve7PortFlowCmd 1;
BA_ "SPN" SG_ 2365470462 Valve6FailSaveModeCmd 1981;
BA_ "SigType" SG_ 2365470462 Valve6FailSaveModeCmd 4;
BA_ "SPN" SG_ 2365470462 Valve6StateCmd 1980;
BA_ "SPN" SG_ 2365470462 Valve6PortFlowCmd 1979;
BA_ "SigType" SG_ 2365470462 Valve6PortFlowCmd 1;
BA_ "SPN" SG_ 2365470206 Valve5FailSaveModeCmd 1969;
BA_ "SigType" SG_ 2365470206 Valve5FailSaveModeCmd 4;
BA_ "SPN" SG_ 2365470206 Valve5StateCmd 1968;
BA_ "SPN" SG_ 2365470206 Valve5PortFlowCmd 1967;
BA_ "SigType" SG_ 2365470206 Valve5PortFlowCmd 1;
BA_ "SPN" SG_ 2365469950 Valve4FailSaveModeCmd 1957;
BA_ "SigType" SG_ 2365469950 Valve4FailSaveModeCmd 4;
BA_ "SPN" SG_ 2365469950 Valve4StateCmd 1956;
BA_ "SPN" SG_ 2365469950 Valve4PortFlowCmd 1955;
BA_ "SigType" SG_ 2365469950 Valve4PortFlowCmd 1;
BA_ "SPN" SG_ 2365469694 Valve3FailSaveModeCmd 1945;
BA_ "SigType" SG_ 2365469694 Valve3FailSaveModeCmd 4;
BA_ "SPN" SG_ 2365469694 Valve3StateCmd 1944;
BA_ "SPN" SG_ 2365469694 Valve3PortFlowCmd 1943;
BA_ "SigType" SG_ 2365469694 Valve3PortFlowCmd 1;
BA_ "SPN" SG_ 2365469438 Valve2FailSaveModeCmd 1933;
BA_ "SigType" SG_ 2365469438 Valve2FailSaveModeCmd 4;
BA_ "SPN" SG_ 2365469438 Valve2StateCmd 1932;
BA_ "SPN" SG_ 2365469438 Valve2PortFlowCmd 1931;
BA_ "SigType" SG_ 2365469438 Valve2PortFlowCmd 1;
BA_ "SigType" SG_ 2365469182 Valve1FailSaveModeCmd 4;
BA_ "SPN" SG_ 2365469182 Valve1StateCmd 1920;
BA_ "SPN" SG_ 2365469182 Valve1PortFlowCmd 1919;
BA_ "SigType" SG_ 2365469182 Valve1PortFlowCmd 1;
BA_ "SPN" SG_ 2365468926 Valve0FailSaveModeCmd 1909;
BA_ "SigType" SG_ 2365468926 Valve0FailSaveModeCmd 4;
BA_ "SPN" SG_ 2365468926 Valve0StateCmd 1908;
BA_ "SPN" SG_ 2365468926 Valve0PortFlowCmd 1907;
BA_ "SigType" SG_ 2365468926 Valve0PortFlowCmd 1;
BA_ "SPN" SG_ 2365468670 Valve15LimitStatus 5190;
BA_ "SPN" SG_ 2365468670 Valve15ReturnPortPressure 2342;
BA_ "SigType" SG_ 2365468670 Valve15ReturnPortPressure 1;
BA_ "SPN" SG_ 2365468670 Valve15RetractPortPressure 2341;
BA_ "SigType" SG_ 2365468670 Valve15RetractPortPressure 1;
BA_ "SPN" SG_ 2365468670 Valve15ExtendedPortPressure 2340;
BA_ "SigType" SG_ 2365468670 Valve15ExtendedPortPressure 1;
BA_ "SPN" SG_ 2365468670 Valve15RetractPortMeasuredFlow 2336;
BA_ "SigType" SG_ 2365468670 Valve15RetractPortMeasuredFlow 1;
BA_ "SPN" SG_ 2365468670 Valve15ExtendedPortMeasuredFlow 2335;
BA_ "SigType" SG_ 2365468670 Valve15ExtendedPortMeasuredFlow 1;
BA_ "SPN" SG_ 2365468414 Valve14LimitStatus 5188;
BA_ "SPN" SG_ 2365468414 Valve14ReturnPortPressure 2330;
BA_ "SigType" SG_ 2365468414 Valve14ReturnPortPressure 1;
BA_ "SPN" SG_ 2365468414 Valve14RetractPortPressure 2329;
BA_ "SigType" SG_ 2365468414 Valve14RetractPortPressure 1;
BA_ "SPN" SG_ 2365468414 Valve14ExtendedPortPressure 2328;
BA_ "SigType" SG_ 2365468414 Valve14ExtendedPortPressure 1;
BA_ "SPN" SG_ 2365468414 Valve14RetractPortMeasuredFlow 2324;
BA_ "SigType" SG_ 2365468414 Valve14RetractPortMeasuredFlow 1;
BA_ "SPN" SG_ 2365468414 Valve14ExtendedPortMeasuredFlow 2323;
BA_ "SigType" SG_ 2365468414 Valve14ExtendedPortMeasuredFlow 1;
BA_ "SPN" SG_ 2365468158 Valve13LimitStatus 5186;
BA_ "SPN" SG_ 2365468158 Valve13ReturnPortPressure 2318;
BA_ "SigType" SG_ 2365468158 Valve13ReturnPortPressure 1;
BA_ "SPN" SG_ 2365468158 Valve13RetractPortPressure 2317;
BA_ "SigType" SG_ 2365468158 Valve13RetractPortPressure 1;
BA_ "SPN" SG_ 2365468158 Valve13ExtendedPortPressure 2316;
BA_ "SigType" SG_ 2365468158 Valve13ExtendedPortPressure 1;
BA_ "SPN" SG_ 2365468158 Valve13RetractPortMeasuredFlow 2312;
BA_ "SigType" SG_ 2365468158 Valve13RetractPortMeasuredFlow 1;
BA_ "SPN" SG_ 2365468158 Valve13ExtendedPortMeasuredFlow 2311;
BA_ "SigType" SG_ 2365468158 Valve13ExtendedPortMeasuredFlow 1;
BA_ "SPN" SG_ 2365467902 Valve12LimitStatus 5184;
BA_ "SPN" SG_ 2365467902 Valve12ReturnPortPressure 2306;
BA_ "SigType" SG_ 2365467902 Valve12ReturnPortPressure 1;
BA_ "SPN" SG_ 2365467902 Valve12RetractPortPressure 2305;
BA_ "SigType" SG_ 2365467902 Valve12RetractPortPressure 1;
BA_ "SPN" SG_ 2365467902 Valve12ExtendedPortPressure 2304;
BA_ "SigType" SG_ 2365467902 Valve12ExtendedPortPressure 1;
BA_ "SPN" SG_ 2365467902 Valve12RetractPortMeasuredFlow 2300;
BA_ "SigType" SG_ 2365467902 Valve12RetractPortMeasuredFlow 1;
BA_ "SPN" SG_ 2365467902 Valve12ExtendedPortMeasuredFlow 2299;
BA_ "SigType" SG_ 2365467902 Valve12ExtendedPortMeasuredFlow 1;
BA_ "SPN" SG_ 2365467646 Valve11LimitStatus 5182;
BA_ "SPN" SG_ 2365467646 Valve11ReturnPortPressure 2294;
BA_ "SigType" SG_ 2365467646 Valve11ReturnPortPressure 1;
BA_ "SPN" SG_ 2365467646 Valve11RetractPortPressure 2293;
BA_ "SigType" SG_ 2365467646 Valve11RetractPortPressure 1;
BA_ "SPN" SG_ 2365467646 Valve11ExtendedPortPressure 2292;
BA_ "SigType" SG_ 2365467646 Valve11ExtendedPortPressure 1;
BA_ "SPN" SG_ 2365467646 Valve11RetractPortMeasuredFlow 2288;
BA_ "SigType" SG_ 2365467646 Valve11RetractPortMeasuredFlow 1;
BA_ "SPN" SG_ 2365467646 Valve11ExtendedPortMeasuredFlow 2287;
BA_ "SigType" SG_ 2365467646 Valve11ExtendedPortMeasuredFlow 1;
BA_ "SPN" SG_ 2365467390 Valve10LimitStatus 5180;
BA_ "SPN" SG_ 2365467390 Valve10ReturnPortPressure 2282;
BA_ "SigType" SG_ 2365467390 Valve10ReturnPortPressure 1;
BA_ "SPN" SG_ 2365467390 Valve10RetractPortPressure 2281;
BA_ "SigType" SG_ 2365467390 Valve10RetractPortPressure 1;
BA_ "SPN" SG_ 2365467390 Valve10ExtendedPortPressure 2280;
BA_ "SigType" SG_ 2365467390 Valve10ExtendedPortPressure 1;
BA_ "SPN" SG_ 2365467390 Valve10RetractPortMeasuredFlow 2276;
BA_ "SigType" SG_ 2365467390 Valve10RetractPortMeasuredFlow 1;
BA_ "SPN" SG_ 2365467390 Valve10ExtendedPortMeasuredFlow 2275;
BA_ "SigType" SG_ 2365467390 Valve10ExtendedPortMeasuredFlow 1;
BA_ "SPN" SG_ 2365467134 Valve9LimitStatus 5178;
BA_ "SPN" SG_ 2365467134 Valve9ReturnPortPressure 2270;
BA_ "SigType" SG_ 2365467134 Valve9ReturnPortPressure 1;
BA_ "SPN" SG_ 2365467134 Valve9RetractPortPressure 2269;
BA_ "SigType" SG_ 2365467134 Valve9RetractPortPressure 1;
BA_ "SPN" SG_ 2365467134 Valve9ExtendedPortPressure 2268;
BA_ "SigType" SG_ 2365467134 Valve9ExtendedPortPressure 1;
BA_ "SPN" SG_ 2365467134 Valve9RetractPortMeasuredFlow 2264;
BA_ "SigType" SG_ 2365467134 Valve9RetractPortMeasuredFlow 1;
BA_ "SPN" SG_ 2365467134 Valve9ExtendedPortMeasuredFlow 2263;
BA_ "SigType" SG_ 2365467134 Valve9ExtendedPortMeasuredFlow 1;
BA_ "SPN" SG_ 2365466878 Valve8LimitStatus 5176;
BA_ "SPN" SG_ 2365466878 Valve8ReturnPortPressure 2258;
BA_ "SigType" SG_ 2365466878 Valve8ReturnPortPressure 1;
BA_ "SPN" SG_ 2365466878 Valve8RetractPortPressure 2257;
BA_ "SigType" SG_ 2365466878 Valve8RetractPortPressure 1;
BA_ "SPN" SG_ 2365466878 Valve8ExtendedPortPressure 2256;
BA_ "SigType" SG_ 2365466878 Valve8ExtendedPortPressure 1;
BA_ "SPN" SG_ 2365466878 Valve8RetractPortMeasuredFlow 1996;
BA_ "SigType" SG_ 2365466878 Valve8RetractPortMeasuredFlow 1;
BA_ "SPN" SG_ 2365466878 Valve8ExtendedPortMeasuredFlow 1995;
BA_ "SigType" SG_ 2365466878 Valve8ExtendedPortMeasuredFlow 1;
BA_ "SPN" SG_ 2365466622 Valve7LimitStatus 5174;
BA_ "SPN" SG_ 2365466622 Valve7ReturnPortPressure 1990;
BA_ "SigType" SG_ 2365466622 Valve7ReturnPortPressure 1;
BA_ "SPN" SG_ 2365466622 Valve7RetractPortPressure 1989;
BA_ "SigType" SG_ 2365466622 Valve7RetractPortPressure 1;
BA_ "SPN" SG_ 2365466622 Valve7ExtendedPortPressure 1988;
BA_ "SigType" SG_ 2365466622 Valve7ExtendedPortPressure 1;
BA_ "SPN" SG_ 2365466622 Valve7RetractPortMeasuredFlow 1984;
BA_ "SigType" SG_ 2365466622 Valve7RetractPortMeasuredFlow 1;
BA_ "SPN" SG_ 2365466622 Valve7ExtendedPortMeasuredFlow 1983;
BA_ "SigType" SG_ 2365466622 Valve7ExtendedPortMeasuredFlow 1;
BA_ "SPN" SG_ 2365466366 Valve6LimitStatus 5172;
BA_ "SPN" SG_ 2365466366 Valve6ReturnPortPressure 1978;
BA_ "SigType" SG_ 2365466366 Valve6ReturnPortPressure 1;
BA_ "SPN" SG_ 2365466366 Valve6RetractPortPressure 1977;
BA_ "SigType" SG_ 2365466366 Valve6RetractPortPressure 1;
BA_ "SPN" SG_ 2365466366 Valve6ExtendedPortPressure 1976;
BA_ "SigType" SG_ 2365466366 Valve6ExtendedPortPressure 1;
BA_ "SPN" SG_ 2365466366 Valve6RetractPortMeasuredFlow 1972;
BA_ "SigType" SG_ 2365466366 Valve6RetractPortMeasuredFlow 1;
BA_ "SPN" SG_ 2365466366 Valve6ExtendedPortMeasuredFlow 1971;
BA_ "SigType" SG_ 2365466366 Valve6ExtendedPortMeasuredFlow 1;
BA_ "SPN" SG_ 2365466110 Valve5LimitStatus 5170;
BA_ "SPN" SG_ 2365466110 Valve5ReturnPortPressure 1966;
BA_ "SigType" SG_ 2365466110 Valve5ReturnPortPressure 1;
BA_ "SPN" SG_ 2365466110 Valve5RetractPortPressure 1965;
BA_ "SigType" SG_ 2365466110 Valve5RetractPortPressure 1;
BA_ "SPN" SG_ 2365466110 Valve5ExtendedPortPressure 1964;
BA_ "SigType" SG_ 2365466110 Valve5ExtendedPortPressure 1;
BA_ "SPN" SG_ 2365466110 Valve5RetractPortMeasuredFlow 1960;
BA_ "SigType" SG_ 2365466110 Valve5RetractPortMeasuredFlow 1;
BA_ "SPN" SG_ 2365466110 Valve5ExtendedPortMeasuredFlow 1959;
BA_ "SigType" SG_ 2365466110 Valve5ExtendedPortMeasuredFlow 1;
BA_ "SPN" SG_ 2365465854 Valve4LimitStatus 5168;
BA_ "SPN" SG_ 2365465854 Valve4ReturnPortPressure 1954;
BA_ "SigType" SG_ 2365465854 Valve4ReturnPortPressure 1;
BA_ "SPN" SG_ 2365465854 Valve4RetractPortPressure 1953;
BA_ "SigType" SG_ 2365465854 Valve4RetractPortPressure 1;
BA_ "SPN" SG_ 2365465854 Valve4ExtendedPortPressure 1952;
BA_ "SigType" SG_ 2365465854 Valve4ExtendedPortPressure 1;
BA_ "SPN" SG_ 2365465854 Valve4RetractPortMeasuredFlow 1948;
BA_ "SigType" SG_ 2365465854 Valve4RetractPortMeasuredFlow 1;
BA_ "SPN" SG_ 2365465854 Valve4ExtendedPortMeasuredFlow 1947;
BA_ "SigType" SG_ 2365465854 Valve4ExtendedPortMeasuredFlow 1;
BA_ "SPN" SG_ 2365465598 Valve3LimitStatus 5166;
BA_ "SPN" SG_ 2365465598 Valve3ReturnPortPressure 1942;
BA_ "SigType" SG_ 2365465598 Valve3ReturnPortPressure 1;
BA_ "SPN" SG_ 2365465598 Valve3RetractPortPressure 1941;
BA_ "SigType" SG_ 2365465598 Valve3RetractPortPressure 1;
BA_ "SPN" SG_ 2365465598 Valve3ExtendedPortPressure 1940;
BA_ "SigType" SG_ 2365465598 Valve3ExtendedPortPressure 1;
BA_ "SPN" SG_ 2365465598 Valve3RetractPortMeasuredFlow 1936;
BA_ "SigType" SG_ 2365465598 Valve3RetractPortMeasuredFlow 1;
BA_ "SPN" SG_ 2365465598 Valve3ExtendedPortMeasuredFlow 1935;
BA_ "SigType" SG_ 2365465598 Valve3ExtendedPortMeasuredFlow 1;
BA_ "SPN" SG_ 2365465342 Valve2LimitStatus 5164;
BA_ "SPN" SG_ 2365465342 Valve2ReturnPortPressure 1930;
BA_ "SigType" SG_ 2365465342 Valve2ReturnPortPressure 1;
BA_ "SPN" SG_ 2365465342 Valve2RetractPortPressure 1929;
BA_ "SigType" SG_ 2365465342 Valve2RetractPortPressure 1;
BA_ "SPN" SG_ 2365465342 Valve2ExtendedPortPressure 1928;
BA_ "SigType" SG_ 2365465342 Valve2ExtendedPortPressure 1;
BA_ "SPN" SG_ 2365465342 Valve2RetractPortMeasuredFlow 1924;
BA_ "SigType" SG_ 2365465342 Valve2RetractPortMeasuredFlow 1;
BA_ "SPN" SG_ 2365465342 Valve2ExtendedPortMeasuredFlow 1923;
BA_ "SigType" SG_ 2365465342 Valve2ExtendedPortMeasuredFlow 1;
VAL_ 2565340800 IndustryGroup 7 "Reserved for SAE" 5 "IndustrialProcessCtrlStationary" 4 "Marine" 3 "Construction" 2 "Agricultural and Forestry" 1 "On-Highway" 0 "Global" 6 "Reserved for SAE" ;
VAL_ 2565340800 VehicleSystem2 0 "Non-specific System" 127 "Not Available" 1 "Tractor" 2 "Tillage" 3 "Secondary Tillage" 4 "Planters/Seeders" 5 "Fertilizers" 6 "Sprayers" 7 "Harvesters" 8 "Root Harvesters" 9 "Forage" 10 "Irrigation" 11 "Transport/Trailer" 12 "Farm Yard Operations" 13 "Powered Auxiliary Device" 14 "Special Crops" 15 "Earth Work" 16 "Skidder" 17 "Sensor Systems" 19 "Timber Harvesters" 20 "Forwarders" 21 "Timber loaders" 22 "Timber Processing Machines" 23 "Mulchers" 24 "Utility Vehicles" 25 "Slurry Applicators" ;
VAL_ 2565340800 OperatingState2 0 "InputNotActivatedInLearnMode" 1 "InputActivatedInLearnMode" ;
VAL_ 2565340800 Function 43 "Transmission Display" 44 "Exhaust Emission Control" 45 "Vehicle Dynamic Stability Control" 46 "Oil Sensor Unit" 47 "Information System Controller" 48 "Ramp Control" 49 "Clutch/Converter Control" 50 "Auxiliary Heater" 51 "Forward-Looking Collision Warning System" 52 "Chassis Controller" 53 "Alternator/Charging System" 54 "Communications Unit, Cellular" 55 "Communications Unit, Satellite" 56 "Communications Unit, Radio" 57 "Steering Column Unit" 58 "Fan Drive Control" 59 "Starter" 60 "Cab Display" 61 "File Server/Printer" 62 "On-Board Diagnostic Unit" 63 "Engine Valve Controller" 64 "Endurance Braking" 65 "Gas Flow Measurement" 66 "I/O Controller" 67 "Electrical System Controller" 68 "Aftertreatment system gas measurement" 69 "Engine Emission Aftertreatement System" 70 "Auxiliary Regeneration Device" 71 "Transfer Case Control" 72 "Coolant Valve Controller" 73 "Rollover Detection Control" 74 "Lubrication System" 75 "Supplemental Fan" 76 "Temperature Sensor" 77 "Fuel Properties Sensor" 78 "Fire Suppression System" 79 "Reserved" 80 "Reserved" 81 "Reserved" 82 "Reserved" 83 "Reserved" 84 "Reserved" 85 "Reserved" 86 "Reserved" 87 "Reserved" 88 "Reserved" 89 "Reserved" 90 "Reserved" 91 "Reserved" 92 "Reserved" 93 "Reserved" 94 "Reserved" 95 "Reserved" 96 "Reserved" 97 "Reserved" 98 "Reserved" 99 "Reserved" 100 "Reserved" 0 "Engine" 1 "Auxiliary Power Unit (APU)" 2 "Electric Propulsion Control" 3 "Transmission" 4 "Battery Pack Monitor" 5 "Shift Control/Console" 6 "Power TakeOff - (Main or Rear)" 7 "Axle - Steering" 8 "Axle - Drive" 9 "Brakes - System Controller" 10 "Brakes - Steer Axle" 11 "Brakes - Drive Axle" 12 "Retarder - Engine" 13 "Retarder - Driveline" 14 "Cruise Control" 15 "Fuel System" 16 "Steering Controller" 17 "Suspension - Steer Axle" 18 "Suspension - Drive Axle" 19 "Instrument Cluster" 20 "Trip Recorder" 21 "Cab Climate Control" 22 "Aerodynamic Control" 23 "Vehicle Navigation" 24 "Vehicle Security" 25 "Network Interconnect ECU" 26 "Body Controller" 27 "Power TakeOff (Secondary or Front)" 28 "Off Vehicle Gateway" 29 "Virtual Terminal (in cab)" 30 "Management Computer" 31 "Propulsion Battery Charger" 32 "Headway Controller" 33 "System Monitor" 34 "Hydraulic Pump Controller" 35 "Suspension - System Controller" 36 "Pneumatic - System Controller" 37 "Cab Controller" 38 "Tire Pressure Control" 39 "Ignition Control Module" 40 "Seat Control" 41 "Lighting - Operator Controls" 42 "Water Pump Control" 101 "Reserved" 102 "Reserved" 103 "Reserved" 104 "Reserved" 105 "Reserved" 106 "Reserved" 107 "Reserved" 108 "Reserved" 109 "Reserved" 110 "Reserved" 111 "Reserved" 112 "Reserved" 113 "Reserved" 114 "Reserved" 115 "Reserved" 116 "Reserved" 117 "Reserved" 118 "Reserved" 119 "Reserved" 120 "Reserved" 121 "Reserved" 122 "Reserved" 123 "Reserved" 124 "Reserved" 125 "Reserved" 126 "Reserved" 127 "Reserved" ;
VAL_ 2565340800 OperatingState1 0 "LearnModeInactive" 1 "LearnModeActive" ;
VAL_ 2565340800 Status_2 0 "Hidden" 1 "Shown" ;
VAL_ 2565340800 ManufacturerCode 234 "Mondial electronic GmbH" 235 "SailorMade Marine Telemetry - Tetra Technology Ltd." 236 "Norac Systems International Inc" 237 "Agtron Enterprises Inc" 238 "ZF Friedrichshafen AG" 239 "May & Scofield Ltd" 240 "Vanair Mfg" 241 "Schneider Automation SAS " 242 "Kokusandenki Co. Ltd" 243 "eRide, Inc." 244 "Techno-Matic" 245 "Capstan Ag Systems, Inc." 246 "Class 1, Inc" 247 "ePULSE" 248 "Cooper Standard Automotive Active Systems Group" 264 "Autolync" 265 "MTS Sensor Technologie GmbH" 266 "International Thermal Research Ltd" 267 "Red Lion Controls, Inc" 268 "Accurate Technologies" 269 "Saft America Inc.,  Space & Defense Division" 270 "Tennant" 271 "Cole Hersee" 312 "Lectronix, Inc." 313 "Ilmor Engineering, Inc" 314 "CSM GmbH" 315 "Icom Incorporated" 316 "ITT Flow Control" 317 "Navtronics Bvba" 318 "SAT Plan" 319 "Cadec Global" 320 "Miedema Landbouwwerktuigenfabriek B.V." 321 "Ultra Electronics, Electrics" 322 "MICHENKA s.r.o." 323 "Mobileye Vision Technologies Ltd." 324 "Snap-on Diagnostics" 325 "ASM Automation Sensorik Messtechnik GmbH" 326 "Akron Brass Company" 327 "Sonceboz SA" 272 "Gross Mechanical Laboratories, Inc" 273 "Active Research Limited" 274 "LTW Technology Co., LTD" 275 "Navico Egersund AS" 276 "Aqua-Hot Heating Systems" 277 "LHP Telematics" 278 "Takata Electronics" 279 "Geometris LP" 280 "Leica Geosystems Pty Ltd" 299 "Rauch Landmaschinen GmbH" 300 "Systron Donner Automotive" 301 "Parker Hannifin (UK) Ltd FDE group" 302 "Nissin Kogyo Co., LTD" 303 "CTS Corporation" 304 "EmpirBus AB" 305 "NovAtel Inc" 306 "Sleipner Motor AB" 307 "MBW Technologies" 308 "Cyntrx" 309 "Krauss-Maffei Wegmann GmbH & Co. KG" 310 "TECNORD srl" 311 "Patrick Power Products" 281 "Precision Governors LLC" 282 "Medallion Instrumentation Systems" 283 "CWF Hamilton & Co Ltd" 284 "Mobile Tech Chile" 285 "Sea Recovery Corp" 286 "Coelmo srl" 287 "NTech Industries, Inc" 288 "Mitsubishi FUSO Truck & Bus Corp." 289 "Watlow" 290 "Kuebler GmbH" 291 "Groeneveld Transport Efficiency BV" 292 "IKUSI - Angel Iglesias S.A." 293 "Spyder Controls Corp." 294 "Grayhill Inc." 295 "BEP Marine" 296 "micro dynamics GmbH" 297 "Zonar Systems Inc" 298 "Holley Performance" 253 "Mobile Control Systems" 254 "GE Sensing" 255 "MEAS France" 256 "Tyco Electronics AMP" 257 "Honda Motor Co., Ltd" 258 "ARAG" 259 "Jetter AG" 260 "Reichhardt GmbH" 261 "Red Dot Corporation" 262 "HydraForce, Inc" 263 "IMMI" 223 "Vaueo Retarder Co., Ltd." 224 "EMMI Network, S.L." 225 "SKF" 226 "Monaco Coach Corporation" 227 "Lykketronic A/S" 228 "ZF Marine Electronics" 229 "Garmin International Inc." 230 "Saucon Technologies" 231 "Topcon Positioning Systems, Inc." 0 "Reserved" 1 "Allied Signal Inc." 2 "Allison Transmission, GMC" 3 "Ametek, US Gauge Division" 4 "Ametek-Dixson" 5 "AMP Inc." 6 "Berifors Electronics AB" 7 "Case Corp." 8 "Caterpillar Inc." 9 "Chrysler Corp." 10 "Cummins Engine Co." 11 "Dearborn Group Inc." 12 "Deere & Company, Precision Farming" 13 "Delco Electronics" 14 "Detroit Diesel Corporation" 15 "Dickey-John Corp." 16 "Eaton Corp." 17 "Eaton Corp. Res & Dev" 18 "Eaton Corp, Transmission Division" 19 "Eaton Corp. Trucking Info Services" 20 "Eaton Ltd" 21 "Echilin Inc., Midland Brake Inc." 22 "Ford Motor Co., Electronic Concepts $ Systems" 23 "Ford Motor Co., Heavy Truck" 24 "Ford Motor Co., Vehicle Controls" 25 "Daimler Trucks North America LLC" 26 "General Motors Corp., Service Technology Group" 27 "GMC" 28 "Grote Ind. Inc." 29 "Hino Motors Ltd." 30 "Isuzu Motors Ltd." 31 "J Pollak Corp." 32 "Jacobs Vehicle Systems" 33 "John Deere" 34 "Kelsey Hayes Co." 35 "Kenworth Truck Co." 36 "Lucas Ltd." 37 "Mack Trucks Inc." 38 "Micro Processor Systems Inc." 39 "Microfirm Inc." 40 "Motorola AIEG Inc." 41 "Motorola Inc." 42 "International Truck and Engine Corp. Engine Electronics" 43 "International Truck and Engine Corp. Vehicle Electronics" 44 "Nippondenso Co. Ltd." 45 "PACCAR" 46 "Noregon Systems, Inc" 47 "Phillips Semiconductor" 48 "Pollak Alphabet" 49 "RE America Inc." 50 "Robert Bosch Corp" 51 "Robert Bosch GmbH" 52 "Meritor Automotive, Inc." 53 "Continental Automotive Systems US, Inc." 54 "Meritor Wabco" 55 "Ryder System Inc." 56 "SAIC" 57 "Sauer-Danfoss Co." 58 "SPX Corporation, OTC Division" 59 "VES Inc." 60 "Volvo Trucks North America Inc." 61 "Volvo Truck Corp." 62 "Wabco" 63 "ZF Industries Inc." 64 "unused" 65 "MAN Nutzfahrzeuge AG" 66 "John Deere Construction Equipment Division" 67 "Funk Manufacturing Company" 68 "Scania" 69 "Trimble Navigation" 70 "Flex-Coil Limited" 71 "Vansco Electronics Ltd." 72 "Sisu Corporation" 73 "LeTourneau, Inc." 74 "Eaton Axle-Brake Division" 75 "Deere & Co. Agricultural Division" 76 "unused" 77 "Deere Power Systems Group" 78 "Frank W. Murphy Manufacturing, Inc." 79 "Daimler Benz AG - Engine Division (PBM)" 80 "Twin Disc, Inc." 81 "Fire Research Corp" 82 "Bobcat/Ingersoll-Rand" 83 "Bendix VORAD Technologies" 84 "New Holland UK Limited" 85 "Kohler Co." 86 "C.E. Niehoff & Company" 87 "J.C. Bamford Excavators Ltd (JCB)" 88 "Satloc Precision GPS" 89 "Kverneland Group, Electronics Division" 90 "Knorr-Bremse SfN GmbH" 91 "BSG Bodensee Steuergeraete GmbH" 92 "Ag-Chem Equipment Co., Inc." 93 "Perkins Engines Company Ltd." 94 "CNH Global N.V." 95 "Pacific Insight Electronics Corp." 96 "Mech@tronic IT GmbH" 97 "Ag Leader Technology, Inc." 98 "Mueller-Elektronik GmbH & Co." 99 "International Transmissions Ltd (ITL)" 100 "VDO Technik AG" 101 "Sensoria" 102 "AGCO GmbH & Co." 103 "CLAAS Agrosystems GmbH & Co. KG" 104 "Claas Selbstfahrende Erntemaschinen GmbH" 105 "Kiepe Elektrik GmbH & Co. KG" 106 "BAE Systems Controls, Inc." 107 "Grimme Landmaschinen GmbH & Co. KG" 108 "WTK-Elecktronik GmbH" 109 "TeeJet Technologies Denmark" 110 "EPIQ Sensor-Nite" 111 "Maschinenfabrik Bernard Krone GmbH" 112 "MECALAC" 113 "Stress-Tek, Inc." 114 "EControls, Inc." 115 "NACCO Materials Handling Group, Inc." 116 "BEELINE Technologies" 117 "HUSCO International" 118 "Intron GmbH" 119 "IntegriNautics" 120 "RDS Technology Ltd." 121 "HED (Hydro Electronic Devices, Inc.)" 122 "FG Wilson (Engineering) Limited" 123 "Basler Electric" 124 "Hydac Electronic" 125 "Nevada Automotive Test Center" 126 "Driver Tech" 127 "Holland USA" 128 "Gerhard Duecker GmbH & Co. KG" 129 "OMNEX Control Systems, Inc." 130 "Nido - Universal Machines B.V." 131 "ITT Industries" 132 "Mulag-Fahrzeugwerk" 133 "Bucher Schoerling GmbH" 134 "Iris Technology Ltd." 135 "Airmar Technology Corporation" 136 "Komatsu Ltd." 137 "Maretron" 138 "Georg Fritzmeier GmbH & Co. KG" 139 "Caterpillar Trimble Control Technologies (CTCT), LLC" 140 "Lowrance Electronics, Inc." 141 "Thales Navigation Ltd." 142 "TRW Automotive (Commercial Steering Systems)" 143 "W. Gmeiner GmbH & Co." 144 "Mercury Marine" 145 "MurCal Controls" 146 "Maxima Technologies" 147 "Nautibus Electronic GmbH" 148 "Blue Water Data, Inc." 149 "Holset" 150 "Fleetguard" 151 "Raven Industries Inc. - Flow Controls Division" 152 "elobau GmbH & Co. KG" 153 "Woodward, Industrial Controls Division" 154 "Westerbeke Corporation" 155 "Vetronix Corporation" 156 "ITT Industries - Cannon" 157 "ISSPRO Inc." 158 "Firestone Industrial Products Company" 159 "NTech Industries Inc." 160 "Nido" 161 "Offshore Systems (UK) Limited" 162 "Axiomatic Technologies" 163 "BRP Inc." 164 "DaimlerChrysler Off-Highway" 165 "CPAC Systems AB" 166 "Phoenix International" 167 "JLG Industries Inc." 168 "Xantrex" 169 "Marlin Technologies Inc." 170 "Computronics Corporation Ltd." 171 "Wachendorff Elektronik GmbH & Co. KG" 172 "Yanmar Marine USA" 173 "Ryeso, Inc." 174 "AB Volvo Penta" 175 "Veris Technologies, Inc." 176 "Moritz Aerospace" 177 "Diagnostic System Associates" 178 "Siemens VDO Automotive AG" 179 "TeeJet Technologies Denmark" 180 "Smart Power Systems" 181 "Coretronics, Inc." 182 "Vehicle Systems Engineering B.V." 183 "KDS Controls, Inc." 184 "EIA Electronics" 185 "Beede Electrical Instrument Company" 186 "Altronic, Inc." 187 "Air-Weigh" 188 "EMP Corp." 189 "QUALCOMM" 190 "Hella KGaA Hueck & Co." 191 "XRS Corporation" 192 "Floscan" 193 "Nobletec" 194 "TriMark Corporation" 195 "General Engine Products" 196 "LEMKEN GmbH & Co. KG" 197 "Mechron Power Systems" 198 "Mystic Valley Communications" 199 "Actia Corp." 200 "MGM Brakes" 201 "Disenos y Tecnologia S.A." 202 "Curtis Instruments, Inc." 203 "MILtronik GmbH" 204 "The Morey Corporation" 205 "SmarTire Systems Inc" 206 "port GmbH" 207 "Otto Engineering" 208 "Drew Technologies, Inc." 209 "Bell Equip. Co. SA (PTY) LTD" 210 "Iteris, Inc." 211 "DNA Group" 212 "Sure Power Industries, Inc." 213 "CNH Belgium N.V." 214 "MC elettronica Srl" 215 "Aetna Engineering/Fireboy-Xintex" 216 "Paneltronics Inc." 217 "RM Michaelides Software & Elektronik GmbH" 218 "Gits Manufacturing Company" 219 "Cat OEM Solutions" 220 "Beede Electrical Instrument Company, Inc." 221 "SiE" 222 "Generac Power Systems, Inc." 1850 "Teleflex" 1851 "Raymarine" 1852 "Navionics" 1853 "Japan Radio Co." 1854 "Northstar Technologies" 1855 "Furuno USA" 1856 "Trimble" 1857 "Simrad" 1858 "Litton" 1859 "Kvasar AB" 1860 "MMP" 1861 "Vector CANtech" 1862 "Sanshin" 1863 "Thomas G. Faria Co." 232 "TSD Integrated Controls" 233 "Yacht Monitoring Solutions Inc." 249 "Schaltbau GmbH" 250 "Kuhn Group" 251 "German Agricultural Society" 252 "Sensor-Technik Wiedemann GmbH" 328 "Qwerty Electronik AB" 329 "Deif A/S" 330 "Kidde Aerospace and Defense" 331 "Horton, Inc." 332 "HWH Corporation" 333 "Hadley Products Corporation" 334 "Takata-Petri AG" 335 "Evo Electric Ltd" 336 "APE s.r.o." 337 "Carraro S.p.A." 338 "GRAF-SYTECO" 339 "Competence Center ISOBUS e.V." 340 "Continental AG" 341 "Boning GmbH & Co" 342 "THOMAS MAGNETE GmbH" 343 "Baumer Group" 344 "Parvus Corporation" 345 "Korean Maritime University" 346 "Control Solutions" 347 "Honeywell" 348 "Amazonen Werke H. Dreyer" 349 "Suonentiet" 350 "Noris Marine Systems GmbH & Co KG" 351 "Thrane & Thrane" 352 "SAME DEUTZ-FAHR" 353 "Hegemon Electronics, Inc." 354 "Junkkari OY" 355 "Mastervolt International B.V." 356 "Fischer Panda Generators, Inc" 357 "Hardi International A/S" 358 "Victron Energy BV" 359 "Ludwig Bergmann GmbH" 360 "HJS Emission Technology GmbH & Co KG" 361 "InMach" 362 "Alois Poettinger Maschinenfabrik GmbH" 363 "BEI Duncan" 364 "OEM Controls Inc." 365 "Digi-Star, LLC" 366 "Viewnyx Corp." 367 "Fliegl Agrartechnik" 368 "HANSENHOF_electronic" 369 "Power Torque Engineering Ltd" 370 "Rolls-Royce Marine AS" 371 "Heinzmann GmbH & Co. KG" 373 "Electronic Design Inc." 374 "Northern Lights, Inc." 381 "B&G" 372 "Delphi" 375 "Williams Controls Inc." 376 "Quake Global" 377 "ifm electronic gmbh" 378 "Glendinning Marine Products" 379 "Yamabiko Corporation" 380 "Suntech International Ltd." 382 "National Agricultural and Food Research Organization" 383 "MCL Industries" 384 "Camano Light" 385 "Johnson Outdoor Marine Electronics" 386 "JLG Automation BVBA" 387 "Orscheln Products, LLC" 388 "Innomatix, LLC" 389 "Benchmark Electronics, Minnesota Division" 390 "Partech Inc." 391 "Electronic Design for Industry, Inc" 392 "Tianyuan Technology Co Ltd." 393 "Harvest Tec, Inc" 394 "Capi 2 Nederland BV" 395 "GENTEC S.R.L." 396 "Beyond Measure" 397 "Sanyo-kiki Co Ltd." 398 "Hilite International" 399 "ISEKI & Co., Ltd." 400 "Livorsi Marine" 401 "Torqeedo GmbH" 402 "Simma Software, Inc." 403 "Trackwell ADS, Inc." 404 "Com Nav Marine Ltd" 405 "Wema System AS" 406 "Vecima Networks Inc." 407 "Comtech Mobile Datacom" 408 "Corvus Energy Ltd." 409 "Transfluid S.r.L." 410 "COBO S.p.A. Divisione 3B6" 411 "Hy-Drive Technologies Ltd." 412 "WebTech Wireless Inc." 413 "Datapross Nijbroek bv" 414 "Cattron Group International" 415 "Valid Manufacturing Ltd." 416 "Kubota Corporation" 417 "KZValve" 418 "Intellistick Inc" 419 "Fusion Electronics Ltd" 420 "Vermeer Corporation, ACS Group" 421 "Vertex Standard Co., Ltd" 422 "True Heading AB" 423 "BSM Wireless, Inc." 424 "Odyne LLC" 425 "Methode Electronics Inc, MDI" 426 "Egersund Marine Electronics AS" 427 "em-trak Marine Electronics Ltd" 428 "Mfg_428" 429 "Rota Engineering Ltd." 455 "ADZ NAGANO GmbH" 456 "General Kinetics" 457 "RUSELPROM-ElectricDrive Ltd" 458 "Control Solutions, Inc." 459 "Alltek Marine Electronics Corp" 460 "San Giorgio S.E.I.N." 461 "HAWE Hydraulik SE" 462 "IHI Shibaura Machinery Corporation" 463 "PROBOTIQ" 464 "Leach International Corporation" 465 "Ashcroft Inc" 466 "Veethree Electronics and Marine LLC" 467 "Lely Industries N.V." 468 "Tyco Fire Protection Products" 469 "RA Consulting GmbH" 470 "SI-TEX Marine Electronics" 471 "Sea Cross Marine AB" 472 "Tenneco Inc." 473 "Boss Industries, Inc." 474 "Persen Technologies Inc." 475 "GME" 476 "Hummingbird Marine Electronics" 477 "OilQuick AB" 478 "OceanSat BV" 479 "Vapor Bus International" 430 "Auteq Telematica S.A." 431 "Tohatsu Corporation" 432 "S&A Systems, Inc." 433 "Rowe Electronics" 434 "Stored Energy Systems" 435 "Zunhammer GmbH" 436 "Kinze Manufacturing" 437 "Digital Yacht Limited" 438 "Comar Systems Ltd" 439 "Hyundai Heavy Industries" 440 "Cummins Power Generation" 441 "PTG Reifendruckregelsysteme GmbH" 442 "Horsch Maschinen GmbH" 443 "SignalQuest, Inc." 444 "ITT Power Solutions" 445 "KAT MECHATRONIC, Electronic Product Division" 446 "CertTech, L.L.C." 447 "Great Plains Mfg." 448 "Stanadyne Corporation, Electronics Systems" 449 "Polaris Industries Inc" 450 "Dycor Technologies Ltd." 451 "Parker Hannifin Corp" 452 "WIKA Alexander Wiegand SE & Co. KG" 453 "Cooper Bussmann" 454 "NGK Spark Plug Co. Ltd" 480 "EnerDel, Inc." 481 "Chetco Digital Instruments" 482 "Tricon Electronics" 483 "Valeo" 484 "Headsight Inc." 485 "MATT automotive" 486 "Westport Innovations Inc." 487 "DSE Test Solutions A/S" 488 "The Charles Machine Works, Inc." 489 "Appareo Systems" 490 "QuikQ" 491 "Penny and Giles Ltd" 492 "Inergy Automotive Systems" 493 "Watcheye" 494 "Synerject" 495 "HOLMER Maschinenbau GmbH" 496 "W. Gessmann GmbH" 497 "SENTRON Sistemas Embarcados" 498 "Innovative Design Solutions, Inc." 499 "LCJ Capteurs" 500 "Oxbo International Corporation" 501 "Agrotronix S.A." 502 "Attwood Corporation" 503 "Naviop S.R.L." 504 "Vesper Marine" 505 "Yetter Farm Equipment" 506 "IHI STAR Machinery Corporation" 507 "Test Center ISOBUS" 508 "Transtech Innovations" 509 "MOTORTECH GmbH" 510 "Marinesoft Co. Ltd" 511 "Sulky" 512 "Inpower LLC" 513 "FarmscanAg" 514 "DISTek Integration, Inc." 515 "GINAF Trucks Nederland B.V." 516 "AVAT Automation GmbH" 517 "Noland Engineering" 518 "Transas USA Inc." 519 "Peeters Landbouwmachines b.v." 520 "Trapeze" ;
VAL_ 2565340800 TextOption 0 "Opaque" 1 "Transparent" ;
VAL_ 2565340800 KeyObjectParentID 2 "KeyIsStillHeld" 1 "KeyHasBeenPressed" 0 "KeyHasBeenReleased" ;
VAL_ 2565340800 SubCommandID 0 "SetGraphicsCursor" 1 "MoveGraphicsCursor" 2 "SetForegroundColour" 3 "SetBackgroundColour" 4 "SetLineAttributesObjectID" 5 "SetFillAttributesObjectID" 6 "SetFontAttributesID" 7 "EraseRectangle" 8 "DrawPoint" 9 "DrawLine" 10 "DrawRectangle" 11 "DrawClosedEllipse" 12 "DrawPolygon" 13 "DrawText" 14 "PanViewport" 15 "ZoomViewport" 16 "PanAndZoomViewport" 17 "ChangeViewportSize" 18 "DrawVTObject" 19 "CopyCanvasToPictureGraphic" 20 "CopyViewportToPictureGraphic" ;
VAL_ 2565340800 EnableOrDisable 1 "Enable" 0 "Disable" ;
VAL_ 2565340800 ShowOrHide 1 "Show" 0 "Hide" ;
VAL_ 2565340800 AssignmentErrorNotAccepted 1 "AssignmentNotAccepted" 0 "AssignmentAccepted" ;
VAL_ 2565340800 Status_1 0 "Hidden" 1 "Shown" ;
VAL_ 2565340800 KeyObjectID 2 "KeyIsStillHeld" 1 "KeyHasBeenPressed" 0 "KeyHasBeenReleased" ;
VAL_ 2565340800 WSMaintenanceVersion 3 "CompliantWithVTVersion3" 4 "CompliantWithVTVersion4" 255 "CompliantWithVTVersion2AndPrior" ;
VAL_ 2565340800 AuxCapabilitiesRequestType 0 "RequestCapabilitiesOfAuxiliaryInputs" 1 "RequestCapabilitiesOfAuxFunctions" ;
VAL_ 2565340800 LockUnlockCommand 0 "UnlockMask" 1 "LockMask" ;
VAL_ 2565340800 MaskType 2 "Alarm" 1 "Data" ;
VAL_ 2565340800 ButtonActivationCode 2 "ButtonsStillHeld" 1 "ButtonHasBeenLatched" 0 "ButtonHasBeenUnlatched" 3 "ButtonPressAborted" ;
VAL_ 2565340800 KeyActivationCode 2 "KeyIsStillHeld" 1 "KeyHasBeenPressed" 0 "KeyHasBeenReleased" 3 "KeyPressAborted" ;
VAL_ 2565340800 VTFunctionECUtoVT 253 "UnsupportedVTFunction" 8 "VTChangeStringValueResponse" 180 "ChangeChildPosition" 17 "ObjectPoolTransfer" 196 "GetWindowMaskData" 7 "VTChangeSoftKeyMaskResponse" 6 "VTChangeActiveMaskResponse" 5 "VTChangeNumericValueResponse" 4 "VTESCResponse" 3 "VTSelectInputObjectResponse" 179 "ChangeStringValue" 255 "WorkingSetMaintenance" 223 "GetVersions" 210 "DeleteVersion" 209 "LoadVersion" 208 "StoreVersion" 199 "GetHardware" 195 "GetTextFontData" 194 "GetNumberOfSoftKeys" 192 "GetMemory" 178 "DeleteObjectPool" 177 "ChangeListItem" 176 "ChangePriority" 175 "ChangeAttribute" 174 "ChangeSoftKeyMask" 173 "ChangeActiveMask" 172 "ChangeFillAttributes" 171 "ChangeLineAttributes" 170 "ChangeFontAttributes" 169 "ChangeEndPoint" 168 "ChangeNumericValue" 167 "ChangeBackgroundColour" 166 "ChangeSize" 165 "ChangeChildLocation" 164 "SetAudioVolume" 163 "ControlAudioDevice" 162 "SelectInputObject" 161 "EnableDisableObject" 160 "ShowHideObject" 146 "ESC" 32 "AuxiliaryAssignmentResponse" 18 "EndOfObjectPool" 2 "PointingEventResponse" 1 "ButtonActivationResponse" 0 "SoftKeyActivationResponse" 181 "SetObjectLabel" 182 "ChangePolygonPoint" 183 "ChangePolygonScale" 184 "GraphicsContextCommand" 185 "GetAttribute" 186 "SelectColourMap" 9 "VTOnUserLayoutHideShowResponse" 34 "AuxiliaryPreferredAssignment" 189 "LockUnlockMask" 190 "ExecuteMacro" 35 "AuxiliaryInputMaintenance" 37 "AuxiliaryInputStatusEnableCommandResponse" 193 "GetSupported WideChars" 33 "Auxiliary Input Status" 36 "AuxiliaryAssignmentResponseType2" 187 "Identify VT" 197 "GetSupportedObjects" 188 "ExecuteExtendedMacro" 211 "ExtendedGetVersions" 212 "ExtendedStoreVersion" 213 "ExtendedLoadVersion" 214 "ExtendedDeleteVersion" 39 "AuxiliaryCapabilitiesRequest" ;
VAL_ 2565799552 IndustryGroup 7 "Reserved for SAE" 5 "IndustrialProcessCtrlStationary" 4 "Marine" 3 "Construction" 2 "Agricultural and Forestry" 1 "On-Highway" 0 "Global" ;
VAL_ 2565799552 VehicleSystem 127 "Not Available" 0 "Non-specific System" ;
VAL_ 2565799552 VehicleSystem5 0 "Ind. Process Control Stationary" 127 "Not Available" ;
VAL_ 2565799552 VehicleSystem4 0 "Non-specific System" 127 "Not Available" 10 "System Tools" 20 "Safety Systems" 25 "Inter/Intranetwork Device" 30 "Electrical Distribution" 40 "Steering and Control Surfaces" 50 "Propulsion" 60 "Navigation" 70 "Communications" 80 "Instrumentation/General Systems (deprecate)" 90 "Internal Environment" 100 "Deck, Cargo and Fishing Equipment" 35 "Electrical Generation" 75 "Sensor Communication Interface" 85 "External Environment" 120 "Display" 125 "Entertainment" ;
VAL_ 2565799552 VehicleSystem3 0 "Non-specific System" 127 "Not Available" 1 "Skid Steer Loader" 2 "Articulated Dump Truck" 3 "Backhoe" 4 "Crawler" 5 "Excavator" 6 "Forklift" 7 "Four Wheel Drive Loader" 8 "Grader" ;
VAL_ 2565799552 VehicleSystem2 0 "Non-specific System" 127 "Not Available" 1 "Tractor" 2 "Tillage" 3 "Secondary Tillage" 4 "Planters/Seeders" 5 "Fertilizers" 6 "Sprayers" 7 "Harvesters" 8 "Root Harvesters" 9 "Forage" 10 "Irrigation" 11 "Transport/Trailer" 12 "Farm Yard Operations" 13 "Powered Auxiliary Device" 14 "Special Crops" 15 "Earth Work" 16 "Skidder" 17 "Sensor Systems" 19 "Timber Harvesters" 20 "Forwarders" 21 "Timber loaders" 22 "Timber Processing Machines" 23 "Mulchers" 24 "Utility Vehicles" 25 "Slurry Applicators" ;
VAL_ 2565799552 VehicleSystem1 0 "Non-specific System" 127 "Not Available" 1 "Tractor" 2 "Trailer" ;
VAL_ 2565799552 Function 43 "Transmission Display" 44 "Exhaust Emission Control" 45 "Vehicle Dynamic Stability Control" 46 "Oil Sensor Unit" 47 "Information System Controller" 48 "Ramp Control" 49 "Clutch/Converter Control" 50 "Auxiliary Heater" 51 "Forward-Looking Collision Warning System" 52 "Chassis Controller" 53 "Alternator/Charging System" 54 "Communications Unit, Cellular" 55 "Communications Unit, Satellite" 56 "Communications Unit, Radio" 57 "Steering Column Unit" 58 "Fan Drive Control" 59 "Starter" 60 "Cab Display" 61 "File Server/Printer" 62 "On-Board Diagnostic Unit" 63 "Engine Valve Controller" 64 "Endurance Braking" 65 "Gas Flow Measurement" 66 "I/O Controller" 67 "Electrical System Controller" 68 "Aftertreatment system gas measurement" 69 "Engine Emission Aftertreatement System" 70 "Auxiliary Regeneration Device" 71 "Transfer Case Control" 72 "Coolant Valve Controller" 73 "Rollover Detection Control" 74 "Lubrication System" 75 "Supplemental Fan" 76 "Temperature Sensor" 77 "Fuel Properties Sensor" 78 "Fire Suppression System" 79 "Reserved" 80 "Reserved" 81 "Reserved" 82 "Reserved" 83 "Reserved" 84 "Reserved" 85 "Reserved" 86 "Reserved" 87 "Reserved" 88 "Reserved" 89 "Reserved" 90 "Reserved" 91 "Reserved" 92 "Reserved" 93 "Reserved" 94 "Reserved" 95 "Reserved" 96 "Reserved" 97 "Reserved" 98 "Reserved" 99 "Reserved" 100 "Reserved" 0 "Engine" 1 "Auxiliary Power Unit (APU)" 2 "Electric Propulsion Control" 3 "Transmission" 4 "Battery Pack Monitor" 5 "Shift Control/Console" 6 "Power TakeOff - (Main or Rear)" 7 "Axle - Steering" 8 "Axle - Drive" 9 "Brakes - System Controller" 10 "Brakes - Steer Axle" 11 "Brakes - Drive Axle" 12 "Retarder - Engine" 13 "Retarder - Driveline" 14 "Cruise Control" 15 "Fuel System" 16 "Steering Controller" 17 "Suspension - Steer Axle" 18 "Suspension - Drive Axle" 19 "Instrument Cluster" 20 "Trip Recorder" 21 "Cab Climate Control" 22 "Aerodynamic Control" 23 "Vehicle Navigation" 24 "Vehicle Security" 25 "Network Interconnect ECU" 26 "Body Controller" 27 "Power TakeOff (Secondary or Front)" 28 "Off Vehicle Gateway" 29 "Virtual Terminal (in cab)" 30 "Management Computer" 31 "Propulsion Battery Charger" 32 "Headway Controller" 33 "System Monitor" 34 "Hydraulic Pump Controller" 35 "Suspension - System Controller" 36 "Pneumatic - System Controller" 37 "Cab Controller" 38 "Tire Pressure Control" 39 "Ignition Control Module" 40 "Seat Control" 41 "Lighting - Operator Controls" 42 "Water Pump Control" 101 "Reserved" 102 "Reserved" 103 "Reserved" 104 "Reserved" 105 "Reserved" 106 "Reserved" 107 "Reserved" 108 "Reserved" 109 "Reserved" 110 "Reserved" 111 "Reserved" 112 "Reserved" 113 "Reserved" 114 "Reserved" 115 "Reserved" 116 "Reserved" 117 "Reserved" 118 "Reserved" 119 "Reserved" 120 "Reserved" 121 "Reserved" 122 "Reserved" 123 "Reserved" 124 "Reserved" 125 "Reserved" 126 "Reserved" 127 "Reserved" ;
VAL_ 2565799552 ManufacturerCode 234 "Mondial electronic GmbH" 235 "SailorMade Marine Telemetry - Tetra Technology Ltd." 236 "Norac Systems International Inc" 237 "Agtron Enterprises Inc" 238 "ZF Friedrichshafen AG" 239 "May & Scofield Ltd" 240 "Vanair Mfg" 241 "Schneider Automation SAS " 242 "Kokusandenki Co. Ltd" 243 "eRide, Inc." 244 "Techno-Matic" 245 "Capstan Ag Systems, Inc." 246 "Class 1, Inc" 247 "ePULSE" 248 "Cooper Standard Automotive Active Systems Group" 264 "Autolync" 265 "MTS Sensor Technologie GmbH" 266 "International Thermal Research Ltd" 267 "Red Lion Controls, Inc" 268 "Accurate Technologies" 269 "Saft America Inc.,  Space & Defense Division" 270 "Tennant" 271 "Cole Hersee" 312 "Lectronix, Inc." 313 "Ilmor Engineering, Inc" 314 "CSM GmbH" 315 "Icom Incorporated" 316 "ITT Flow Control" 317 "Navtronics Bvba" 318 "SAT Plan" 319 "Cadec Global" 320 "Miedema Landbouwwerktuigenfabriek B.V." 321 "Ultra Electronics, Electrics" 322 "MICHENKA s.r.o." 323 "Mobileye Vision Technologies Ltd." 324 "Snap-on Diagnostics" 325 "ASM Automation Sensorik Messtechnik GmbH" 326 "Akron Brass Company" 327 "Sonceboz SA" 272 "Gross Mechanical Laboratories, Inc" 273 "Active Research Limited" 274 "LTW Technology Co., LTD" 275 "Navico Egersund AS" 276 "Aqua-Hot Heating Systems" 277 "LHP Telematics" 278 "Takata Electronics" 279 "Geometris LP" 280 "Leica Geosystems Pty Ltd" 299 "Rauch Landmaschinen GmbH" 300 "Systron Donner Automotive" 301 "Parker Hannifin (UK) Ltd FDE group" 302 "Nissin Kogyo Co., LTD" 303 "CTS Corporation" 304 "EmpirBus AB" 305 "NovAtel Inc" 306 "Sleipner Motor AB" 307 "MBW Technologies" 308 "Cyntrx" 309 "Krauss-Maffei Wegmann GmbH & Co. KG" 310 "TECNORD srl" 311 "Patrick Power Products" 281 "Precision Governors LLC" 282 "Medallion Instrumentation Systems" 283 "CWF Hamilton & Co Ltd" 284 "Mobile Tech Chile" 285 "Sea Recovery Corp" 286 "Coelmo srl" 287 "NTech Industries, Inc" 288 "Mitsubishi FUSO Truck & Bus Corp." 289 "Watlow" 290 "Kuebler GmbH" 291 "Groeneveld Transport Efficiency BV" 292 "IKUSI - Angel Iglesias S.A." 293 "Spyder Controls Corp." 294 "Grayhill Inc." 295 "BEP Marine" 296 "micro dynamics GmbH" 297 "Zonar Systems Inc" 298 "Holley Performance" 253 "Mobile Control Systems" 254 "GE Sensing" 255 "MEAS France" 256 "Tyco Electronics AMP" 257 "Honda Motor Co., Ltd" 258 "ARAG" 259 "Jetter AG" 260 "Reichhardt GmbH" 261 "Red Dot Corporation" 262 "HydraForce, Inc" 263 "IMMI" 223 "Vaueo Retarder Co., Ltd." 224 "EMMI Network, S.L." 225 "SKF" 226 "Monaco Coach Corporation" 227 "Lykketronic A/S" 228 "ZF Marine Electronics" 229 "Garmin International Inc." 230 "Saucon Technologies" 231 "Topcon Positioning Systems, Inc." 0 "Reserved" 1 "Allied Signal Inc." 2 "Allison Transmission, GMC" 3 "Ametek, US Gauge Division" 4 "Ametek-Dixson" 5 "AMP Inc." 6 "Berifors Electronics AB" 7 "Case Corp." 8 "Caterpillar Inc." 9 "Chrysler Corp." 10 "Cummins Engine Co." 11 "Dearborn Group Inc." 12 "Deere & Company, Precision Farming" 13 "Delco Electronics" 14 "Detroit Diesel Corporation" 15 "Dickey-John Corp." 16 "Eaton Corp." 17 "Eaton Corp. Res & Dev" 18 "Eaton Corp, Transmission Division" 19 "Eaton Corp. Trucking Info Services" 20 "Eaton Ltd" 21 "Echilin Inc., Midland Brake Inc." 22 "Ford Motor Co., Electronic Concepts $ Systems" 23 "Ford Motor Co., Heavy Truck" 24 "Ford Motor Co., Vehicle Controls" 25 "Daimler Trucks North America LLC" 26 "General Motors Corp., Service Technology Group" 27 "GMC" 28 "Grote Ind. Inc." 29 "Hino Motors Ltd." 30 "Isuzu Motors Ltd." 31 "J Pollak Corp." 32 "Jacobs Vehicle Systems" 33 "John Deere" 34 "Kelsey Hayes Co." 35 "Kenworth Truck Co." 36 "Lucas Ltd." 37 "Mack Trucks Inc." 38 "Micro Processor Systems Inc." 39 "Microfirm Inc." 40 "Motorola AIEG Inc." 41 "Motorola Inc." 42 "International Truck and Engine Corp. Engine Electronics" 43 "International Truck and Engine Corp. Vehicle Electronics" 44 "Nippondenso Co. Ltd." 45 "PACCAR" 46 "Noregon Systems, Inc" 47 "Phillips Semiconductor" 48 "Pollak Alphabet" 49 "RE America Inc." 50 "Robert Bosch Corp" 51 "Robert Bosch GmbH" 52 "Meritor Automotive, Inc." 53 "Continental Automotive Systems US, Inc." 54 "Meritor Wabco" 55 "Ryder System Inc." 56 "SAIC" 57 "Sauer-Danfoss Co." 58 "SPX Corporation, OTC Division" 59 "VES Inc." 60 "Volvo Trucks North America Inc." 61 "Volvo Truck Corp." 62 "Wabco" 63 "ZF Industries Inc." 64 "unused" 65 "MAN Nutzfahrzeuge AG" 66 "John Deere Construction Equipment Division" 67 "Funk Manufacturing Company" 68 "Scania" 69 "Trimble Navigation" 70 "Flex-Coil Limited" 71 "Vansco Electronics Ltd." 72 "Sisu Corporation" 73 "LeTourneau, Inc." 74 "Eaton Axle-Brake Division" 75 "Deere & Co. Agricultural Division" 76 "unused" 77 "Deere Power Systems Group" 78 "Frank W. Murphy Manufacturing, Inc." 79 "Daimler Benz AG - Engine Division (PBM)" 80 "Twin Disc, Inc." 81 "Fire Research Corp" 82 "Bobcat/Ingersoll-Rand" 83 "Bendix VORAD Technologies" 84 "New Holland UK Limited" 85 "Kohler Co." 86 "C.E. Niehoff & Company" 87 "J.C. Bamford Excavators Ltd (JCB)" 88 "Satloc Precision GPS" 89 "Kverneland Group, Electronics Division" 90 "Knorr-Bremse SfN GmbH" 91 "BSG Bodensee Steuergeraete GmbH" 92 "Ag-Chem Equipment Co., Inc." 93 "Perkins Engines Company Ltd." 94 "CNH Global N.V." 95 "Pacific Insight Electronics Corp." 96 "Mech@tronic IT GmbH" 97 "Ag Leader Technology, Inc." 98 "Mueller-Elektronik GmbH & Co." 99 "International Transmissions Ltd (ITL)" 100 "VDO Technik AG" 101 "Sensoria" 102 "AGCO GmbH & Co." 103 "CLAAS Agrosystems GmbH & Co. KG" 104 "Claas Selbstfahrende Erntemaschinen GmbH" 105 "Kiepe Elektrik GmbH & Co. KG" 106 "BAE Systems Controls, Inc." 107 "Grimme Landmaschinen GmbH & Co. KG" 108 "WTK-Elecktronik GmbH" 109 "TeeJet Technologies Denmark" 110 "EPIQ Sensor-Nite" 111 "Maschinenfabrik Bernard Krone GmbH" 112 "MECALAC" 113 "Stress-Tek, Inc." 114 "EControls, Inc." 115 "NACCO Materials Handling Group, Inc." 116 "BEELINE Technologies" 117 "HUSCO International" 118 "Intron GmbH" 119 "IntegriNautics" 120 "RDS Technology Ltd." 121 "HED (Hydro Electronic Devices, Inc.)" 122 "FG Wilson (Engineering) Limited" 123 "Basler Electric" 124 "Hydac Electronic" 125 "Nevada Automotive Test Center" 126 "Driver Tech" 127 "Holland USA" 128 "Gerhard Duecker GmbH & Co. KG" 129 "OMNEX Control Systems, Inc." 130 "Nido - Universal Machines B.V." 131 "ITT Industries" 132 "Mulag-Fahrzeugwerk" 133 "Bucher Schoerling GmbH" 134 "Iris Technology Ltd." 135 "Airmar Technology Corporation" 136 "Komatsu Ltd." 137 "Maretron" 138 "Georg Fritzmeier GmbH & Co. KG" 139 "Caterpillar Trimble Control Technologies (CTCT), LLC" 140 "Lowrance Electronics, Inc." 141 "Thales Navigation Ltd." 142 "TRW Automotive (Commercial Steering Systems)" 143 "W. Gmeiner GmbH & Co." 144 "Mercury Marine" 145 "MurCal Controls" 146 "Maxima Technologies" 147 "Nautibus Electronic GmbH" 148 "Blue Water Data, Inc." 149 "Holset" 150 "Fleetguard" 151 "Raven Industries Inc. - Flow Controls Division" 152 "elobau GmbH & Co. KG" 153 "Woodward, Industrial Controls Division" 154 "Westerbeke Corporation" 155 "Vetronix Corporation" 156 "ITT Industries - Cannon" 157 "ISSPRO Inc." 158 "Firestone Industrial Products Company" 159 "NTech Industries Inc." 160 "Nido" 161 "Offshore Systems (UK) Limited" 162 "Axiomatic Technologies" 163 "BRP Inc." 164 "DaimlerChrysler Off-Highway" 165 "CPAC Systems AB" 166 "Phoenix International" 167 "JLG Industries Inc." 168 "Xantrex" 169 "Marlin Technologies Inc." 170 "Computronics Corporation Ltd." 171 "Wachendorff Elektronik GmbH & Co. KG" 172 "Yanmar Marine USA" 173 "Ryeso, Inc." 174 "AB Volvo Penta" 175 "Veris Technologies, Inc." 176 "Moritz Aerospace" 177 "Diagnostic System Associates" 178 "Siemens VDO Automotive AG" 179 "TeeJet Technologies Denmark" 180 "Smart Power Systems" 181 "Coretronics, Inc." 182 "Vehicle Systems Engineering B.V." 183 "KDS Controls, Inc." 184 "EIA Electronics" 185 "Beede Electrical Instrument Company" 186 "Altronic, Inc." 187 "Air-Weigh" 188 "EMP Corp." 189 "QUALCOMM" 190 "Hella KGaA Hueck & Co." 191 "XRS Corporation" 192 "Floscan" 193 "Nobletec" 194 "TriMark Corporation" 195 "General Engine Products" 196 "LEMKEN GmbH & Co. KG" 197 "Mechron Power Systems" 198 "Mystic Valley Communications" 199 "Actia Corp." 200 "MGM Brakes" 201 "Disenos y Tecnologia S.A." 202 "Curtis Instruments, Inc." 203 "MILtronik GmbH" 204 "The Morey Corporation" 205 "SmarTire Systems Inc" 206 "port GmbH" 207 "Otto Engineering" 208 "Drew Technologies, Inc." 209 "Bell Equip. Co. SA (PTY) LTD" 210 "Iteris, Inc." 211 "DNA Group" 212 "Sure Power Industries, Inc." 213 "CNH Belgium N.V." 214 "MC elettronica Srl" 215 "Aetna Engineering/Fireboy-Xintex" 216 "Paneltronics Inc." 217 "RM Michaelides Software & Elektronik GmbH" 218 "Gits Manufacturing Company" 219 "Cat OEM Solutions" 220 "Beede Electrical Instrument Company, Inc." 221 "SiE" 222 "Generac Power Systems, Inc." 1850 "Teleflex" 1851 "Raymarine" 1852 "Navionics" 1853 "Japan Radio Co." 1854 "Northstar Technologies" 1855 "Furuno USA" 1856 "Trimble" 1857 "Simrad" 1858 "Litton" 1859 "Kvasar AB" 1860 "MMP" 1861 "Vector CANtech" 1862 "Sanshin" 1863 "Thomas G. Faria Co." 232 "TSD Integrated Controls" 233 "Yacht Monitoring Solutions Inc." 249 "Schaltbau GmbH" 250 "Kuhn Group" 251 "German Agricultural Society" 252 "Sensor-Technik Wiedemann GmbH" 328 "Qwerty Electronik AB" 329 "Deif A/S" 330 "Kidde Aerospace and Defense" 331 "Horton, Inc." 332 "HWH Corporation" 333 "Hadley Products Corporation" 334 "Takata-Petri AG" 335 "Evo Electric Ltd" 336 "APE s.r.o." 337 "Carraro S.p.A." 338 "GRAF-SYTECO" 339 "Competence Center ISOBUS e.V." 340 "Continental AG" 341 "Boning GmbH & Co" 342 "THOMAS MAGNETE GmbH" 343 "Baumer Group" 344 "Parvus Corporation" 345 "Korean Maritime University" 346 "Control Solutions" 347 "Honeywell" 348 "Amazonen Werke H. Dreyer" 349 "Suonentiet" 350 "Noris Marine Systems GmbH & Co KG" 351 "Thrane & Thrane" 352 "SAME DEUTZ-FAHR" 353 "Hegemon Electronics, Inc." 354 "Junkkari OY" 355 "Mastervolt International B.V." 356 "Fischer Panda Generators, Inc" 357 "Hardi International A/S" 358 "Victron Energy BV" 359 "Ludwig Bergmann GmbH" 360 "HJS Emission Technology GmbH & Co KG" 361 "InMach" 362 "Alois Poettinger Maschinenfabrik GmbH" 363 "BEI Duncan" 364 "OEM Controls Inc." 365 "Digi-Star, LLC" 366 "Viewnyx Corp." 367 "Fliegl Agrartechnik" 368 "HANSENHOF_electronic" 369 "Power Torque Engineering Ltd" 370 "Rolls-Royce Marine AS" 371 "Heinzmann GmbH & Co. KG" 373 "Electronic Design Inc." 374 "Northern Lights, Inc." 381 "B&G" 372 "Delphi" 375 "Williams Controls Inc." 376 "Quake Global" 377 "ifm electronic gmbh" 378 "Glendinning Marine Products" 379 "Yamabiko Corporation" 380 "Suntech International Ltd." 382 "National Agricultural and Food Research Organization" 383 "MCL Industries" 384 "Camano Light" 385 "Johnson Outdoor Marine Electronics" 386 "JLG Automation BVBA" 387 "Orscheln Products, LLC" 388 "Innomatix, LLC" 389 "Benchmark Electronics, Minnesota Division" 390 "Partech Inc." 391 "Electronic Design for Industry, Inc" 392 "Tianyuan Technology Co Ltd." 393 "Harvest Tec, Inc" 394 "Capi 2 Nederland BV" 395 "GENTEC S.R.L." 396 "Beyond Measure" 397 "Sanyo-kiki Co Ltd." 398 "Hilite International" 399 "ISEKI & Co., Ltd." 400 "Livorsi Marine" 401 "Torqeedo GmbH" 402 "Simma Software, Inc." 403 "Trackwell ADS, Inc." 404 "Com Nav Marine Ltd" 405 "Wema System AS" 406 "Vecima Networks Inc." 407 "Comtech Mobile Datacom" 408 "Corvus Energy Ltd." 409 "Transfluid S.r.L." 410 "COBO S.p.A. Divisione 3B6" 411 "Hy-Drive Technologies Ltd." 412 "WebTech Wireless Inc." 413 "Datapross Nijbroek bv" 414 "Cattron Group International" 415 "Valid Manufacturing Ltd." 416 "Kubota Corporation" 417 "KZValve" 418 "Intellistick Inc" 419 "Fusion Electronics Ltd" 420 "Vermeer Corporation, ACS Group" 421 "Vertex Standard Co., Ltd" 422 "True Heading AB" 423 "BSM Wireless, Inc." 424 "Odyne LLC" 425 "Methode Electronics Inc, MDI" 426 "Egersund Marine Electronics AS" 427 "em-trak Marine Electronics Ltd" 428 "Mfg_428" 429 "Rota Engineering Ltd." 455 "ADZ NAGANO GmbH" 456 "General Kinetics" 457 "RUSELPROM-ElectricDrive Ltd" 458 "Control Solutions, Inc." 459 "Alltek Marine Electronics Corp" 460 "San Giorgio S.E.I.N." 461 "HAWE Hydraulik SE" 462 "IHI Shibaura Machinery Corporation" 463 "PROBOTIQ" 464 "Leach International Corporation" 465 "Ashcroft Inc" 466 "Veethree Electronics and Marine LLC" 467 "Lely Industries N.V." 468 "Tyco Fire Protection Products" 469 "RA Consulting GmbH" 470 "SI-TEX Marine Electronics" 471 "Sea Cross Marine AB" 472 "Tenneco Inc." 473 "Boss Industries, Inc." 474 "Persen Technologies Inc." 475 "GME" 476 "Hummingbird Marine Electronics" 477 "OilQuick AB" 478 "OceanSat BV" 479 "Vapor Bus International" 430 "Auteq Telematica S.A." 431 "Tohatsu Corporation" 432 "S&A Systems, Inc." 433 "Rowe Electronics" 434 "Stored Energy Systems" 435 "Zunhammer GmbH" 436 "Kinze Manufacturing" 437 "Digital Yacht Limited" 438 "Comar Systems Ltd" 439 "Hyundai Heavy Industries" 440 "Cummins Power Generation" 441 "PTG Reifendruckregelsysteme GmbH" 442 "Horsch Maschinen GmbH" 443 "SignalQuest, Inc." 444 "ITT Power Solutions" 445 "KAT MECHATRONIC, Electronic Product Division" 446 "CertTech, L.L.C." 447 "Great Plains Mfg." 448 "Stanadyne Corporation, Electronics Systems" 449 "Polaris Industries Inc" 450 "Dycor Technologies Ltd." 451 "Parker Hannifin Corp" 452 "WIKA Alexander Wiegand SE & Co. KG" 453 "Cooper Bussmann" 454 "NGK Spark Plug Co. Ltd" 480 "EnerDel, Inc." 481 "Chetco Digital Instruments" 482 "Tricon Electronics" 483 "Valeo" 484 "Headsight Inc." 485 "MATT automotive" 486 "Westport Innovations Inc." 487 "DSE Test Solutions A/S" 488 "The Charles Machine Works, Inc." 489 "Appareo Systems" 490 "QuikQ" 491 "Penny and Giles Ltd" 492 "Inergy Automotive Systems" 493 "Watcheye" 494 "Synerject" 495 "HOLMER Maschinenbau GmbH" 496 "W. Gessmann GmbH" 497 "SENTRON Sistemas Embarcados" 498 "Innovative Design Solutions, Inc." 499 "LCJ Capteurs" 500 "Oxbo International Corporation" 501 "Agrotronix S.A." 502 "Attwood Corporation" 503 "Naviop S.R.L." 504 "Vesper Marine" 505 "Yetter Farm Equipment" 506 "IHI STAR Machinery Corporation" 507 "Test Center ISOBUS" 508 "Transtech Innovations" 509 "MOTORTECH GmbH" 510 "Marinesoft Co. Ltd" 511 "Sulky" 512 "Inpower LLC" 513 "FarmscanAg" 514 "DISTek Integration, Inc." 515 "GINAF Trucks Nederland B.V." 516 "AVAT Automation GmbH" 517 "Noland Engineering" 518 "Transas USA Inc." 519 "Peeters Landbouwmachines b.v." 520 "Trapeze" ;
VAL_ 2365475073 GroundBasedMachineDirection 3 "NotAvailable" 2 "ErrorIndication" 1 "Forward" 0 "Reverse" ;
VAL_ 2360147710 GuidSysComExitReasonCode 0 "No reason/all clear " 1 "Operator presence not detected" 2 "Implement released control of function " 3 "Operator override of function" 4 "Operator control not in valid position" 5 "Remote command timeout" 6 "Remote command out of range/invalid" 7 "Function not calibrated" 8 "Operator control fault" 9 "Function fault" 20 "Hydraulic oil level too low " 21 "Hydraulic oil temperature too low" 22 "Vehicle transmission gear does not allow remote commands" 23 "Vehicle speed too low " 24 "Vehicle speed too high" 25 "Alternate guidance system active" 26 "Control unit in diagnostic mode" 62 "Error " 63 "Not available (parameter not supported)" ;
VAL_ 2360147710 GuidanceLimitStatus 0 "Not limited" 1 "Operator limited/controlled (request cannot be implemented) " 2 "Limited high (only lower command values result in a change) " 3 "Limited low (only higher command values result in a change)" 4 "Reserved" 5 "Reserved" 6 "Non-recoverable fault " 7 "Not available (parameter not supported) " ;
VAL_ 2360147710 RequestResetCommandStatus 3 "NotAvailable" 2 "Error" 1 "ResetRequired" 0 "ResetNotRequired" ;
VAL_ 2360147710 SteeringInputPositionStatus 3 "NotAvailable" 2 "Error" 1 "CorrectPosition" 0 "NotTheCorrectPosition" ;
VAL_ 2360147710 SteeringSystemReadiness 3 "NotAvailable" 2 "Error" 1 "SystemIsReady" 0 "SystemIsNotReady" ;
VAL_ 2360147710 MechanicalSystemLockout 3 "NotAvailable" 2 "Error" 1 "Active" 0 "NotActive" ;
VAL_ 2360213246 CurvatureCommandStatus 3 "NotAvailable" 2 "Error" 1 "IntendedToSteer" 0 "NotIntendedToSteer" ;
VAL_ 2563047166 FailSaveModeCmd 3 "DoNotCare" 1 "Float" 0 "Block" ;
VAL_ 2563047166 StateCmd 15 "Reserved" 3 "Float" 2 "Retract" 1 "Extend" 0 "Block" ;
VAL_ 2563112702 ValveLimitStatus 0 "Not limited" 1 "Operator Limited" 2 "Limited High" 3 "Limited Low" 4 "Reserved" 5 "Reserver" 6 "Non-recoverable Fault" 7 "Not available" ;
VAL_ 2563178238 ValveLimitStatus 0 "Not limited" 1 "Operator Limited" 2 "Limited High" 3 "Limited Low" 4 "Reserved" 5 "Reserver" 6 "Non-recoverable Fault" 7 "Not available" ;
VAL_ 2563178238 FailSafeMode 3 "NotAvailable" 2 "ErrorIndication" 1 "Float" 0 "Block" ;
VAL_ 2563178238 ValveState 15 "DoNotCare" 14 "ErrorIndication" 3 "Floating" 2 "Retract" 1 "Extend" 0 "Blocked" ;
VAL_ 2628452094 RF_ReportHiddenFiles 0 "DoNotReportHiddenFiles" 1 "ReportHiddenFiles" 255 "NotAvailable" ;
VAL_ 2628452094 SF_PositionMode 0 "From the beginning of the file" 1 "From the current pointer pos" 2 "From the end of the file" ;
VAL_ 2628452094 OF_FlagExclusiveAccess 0 "Open file for shared read access" 1 "Open file with exclusive access" ;
VAL_ 2628452094 OF_FlagAppend 0 "Open file for random access" 1 "Open file for appending data" ;
VAL_ 2628452094 SET_ATTR_Hidden 0 "Clear 'hidden' attribute" 1 "Set 'hidden' attribute" 2 "Reserved" 3 "Leave 'hidden' attribute" ;
VAL_ 2628452094 OF_FlagCreateNew 0 "Open an existing file" 1 "Create new file if not existing" ;
VAL_ 2628452094 MF_MoveModeRecursive 0 "'recursive' mode is not set" 1 "'recursive' mode is set" ;
VAL_ 2628452094 DF_DeleteModeRecursive 0 "'recursive' mode is not set" 1 "'recursive' mode is set" ;
VAL_ 2628452094 MF_MoveModeForce 0 "'force' mode is not set" 1 "'force' mode is set" ;
VAL_ 2628452094 DF_DeleteModeForce 0 "'force' mode is not set" 1 "'force' mode is set" ;
VAL_ 2628452094 SET_ATTR_ReadOnly 0 "Clear 'read-only' attribute" 1 "Set 'read-only' attribute" 2 "Reserved" 3 "Leave 'read-only' attribute" ;
VAL_ 2628452094 OF_FlagReadWrite 0 "Open file for reading only" 1 "Open file for writing only" 2 "Open file for reading & writing" 3 "Open directory for reading" ;
VAL_ 2628452094 MF_MoveModeCopy 0 "'copy' mode is not set" 1 "'copy' mode is set" ;
VAL_ 2628452094 DF_DeleteMode 0 "'copy' mode is not set" 1 "'copy' mode is set" ;
VAL_ 2628452094 VS_RequestVolumeToPrepareForRemo 1 "RequestVolumeToPrepareForRemoval" ;
VAL_ 2628452094 VS_ReportVolumeUsedByClient 0 "ReportVolumeNotInUseByClient" 1 "ReportVolumeInUseByClient" ;
VAL_ 2628452094 CM_VersionNumber 0 "DIS" 1 "FDIS" 2 "FirstPublishedEditionOfIS" 3 "FirstPublishedEditionAndAmd1OfIS" 255 "CompliantToVersion2AndPrior" ;
VAL_ 2628452094 FSClientCommand 0 "CMConnectionMaintenance" 16 "DHGetCurrentDirectory" 32 "FAOpenFile" 33 "FASeekFile" 34 "FAReadFile" 35 "FAWriteFile" 36 "FACloseFile" 48 "FHMoveFile" 49 "FHDeleteFile" 50 "FHGetFileAttributes" 51 "FHSetFileAttributes" 17 "DHChangeCurrentDirectory" 52 "FHGetFileDateTime" 64 "VHVolumeInitialization" 1 "CMGetFileServerProperties" 2 "VSVolumeStatusRequest" ;
VAL_ 2628517630 GA_ATTR_VolumeRemovable 0 "Volume is removable" 1 "Volume is not removable" ;
VAL_ 2628517630 GA_ATTR_SupportsLongFilenames 0 "Volume supports no long filename" 1 "Volume supports long filenames" ;
VAL_ 2628517630 VI_ATTR_Directory 0 "Handle does not specify a dir" 1 "Handle specifies a directory" ;
VAL_ 2628517630 GA_ATTR_IsVolume 0 "'System' attribute is not set" 1 "'System' attribute is set" ;
VAL_ 2628517630 GA_ATTR_VolSupportsHiddenAttr 0 "Volume not support hidden attr." 1 "Volume supports hidden attribute" ;
VAL_ 2628517630 GA_ATTR_Hidden 0 "'Hidden' attribute is not set" 1 "'Hidden' attribute is set" ;
VAL_ 2628517630 GA_ATTR_ReadOnly 0 "'Read-only' attribute is not set" 1 "'Read-only' attribute is set" ;
VAL_ 2628517630 GSP_SupportMultipleVolumes 0 "Beschreibung für den Wert '0'" ;
VAL_ 2628517630 FDT_ErrorCode 0 "Success" 1 "Access Denied" 3 "Too many files open" 4 "File, path or volume not found" 6 "Invalid given source name" 10 "Media is not present" 44 "Any other error" 43 "Out ot memory" 11 "Failure during a read operation" 13 " Volume possibly not initialized" ;
VAL_ 2628517630 RF_ErrorCode 45 "File pointer at end of file" 44 "Any other error" 42 "Invalid request length" 5 "Invalid handle" 0 "Success" 11 "Failure during read operation" 43 "Out of memory" 1 "Access denied" ;
VAL_ 2628517630 SF_ErrorCode 0 "Success" 5 "Invalid handle" 42 "Invalid request length" 44 "Any other error" 45 "File pointer at end of file" 11 "Failure during read operation" 43 "Out of memory" ;
VAL_ 2628517630 OF_ErrorCode 0 "Success" 1 "Access Denied" 2 "Invalid Access" 3 "Too many files open" 4 "File, path or volume not found" 6 "Invalid given source name" 8 "Volume out of free space" 10 "Media is not present" 44 "Any other error" 43 "Out of memory" 13 "Volume possibly not initialized" ;
VAL_ 2628517630 WF_ErrorCode 0 "Success" 1 "Access Denied" 5 "Invalid handle" 8 "Volume out of free space" 9 "Failure during a write operation" 42 "Invalid request length" 44 "Any other error" 43 "Out of memory" ;
VAL_ 2628517630 CF_ErrorCode 0 "Success" 1 "Access Denied" 5 "Invalid handle" 8 "Volume out of free space" 9 "Failure during a write operation" 44 "Any other error" 43 "Out ot memory" ;
VAL_ 2628517630 MF_ErrorCode 0 "Success" 1 "Access Denied" 3 "Too many files open" 6 "Invalid given source name" 7 "Invalid given destination name" 8 "Volume out of free space" 9 "Verify failure during a write op" 10 "Media is not present" 44 "Any other error" 43 "Out of memory" 4 "File, path or volume not found" 13 "Volume possibly not initialized" ;
VAL_ 2628517630 GA_ErrorCode 0 "Success" 1 "Access Denied" 3 "Too many files open" 4 "File, path or volume not found" 6 "Invalid given source name" 10 "Media is not present" 44 "Any other error" 43 "Out of memory" 11 "Failure during read operation" 13 "Volume possibly not initialized" ;
VAL_ 2628517630 SA_ErrorCode 0 "Success" 1 "Access Denied" 3 "Too many files open" 4 "File, path or volume not found" 6 "Invalid given source name" 8 "Volume out of free space" 9 "Failure during write operation" 10 "Media is not present" 44 "Any other error" 43 "Out of memory" 11 "Failure during read operation" 13 "Volume possibly not initialized" ;
VAL_ 2628517630 GCD_ErrorCode 0 "Success" 10 "Media is not present" 44 "Any other error" 43 "Out of Memory" 13 "Volume possibly not initialized" ;
VAL_ 2628517630 CCD_ErrorCode 0 "Success" 10 "Media is not present" 44 "Any other error" 43 "Out of memory" 13 "Volume possibly not initialized" 1 "Access denied" 2 "Invalid Access" 4 "File, path or volume not found" 7 "Invalid destination name given" ;
VAL_ 2628517630 DF_ErrorCode 0 "Success" 1 "Access Denied" 4 "File, path or volume not found" 6 "Invalid given source name" 10 "Media is not present" 44 "Any other error" 43 "Out of memory" 9 "Failure during write operation" 11 "Failure during read operation" 13 "Volume possibly not initialized" ;
VAL_ 2628517630 VI_ErrorCode 0 "Success" 1 "Access Denied" 4 "File, path or volume not found" 6 "Invalid given source name" 8 "Volume out of free space" 9 "Failure during write operation" 42 "Invalid request length" 44 "Any other error" 43 "Out of memory" 10 "Media is not present" 11 "Failure during read operation" 13 "Volume possibly not initialized" ;
VAL_ 2628517630 GSP_VersionNumber 0 "DIS" 1 "FDIS" 2 "FirstPublishedEditionOfIS" 3 "FirstPublishedEditionAndAmd1OfIS" 255 "CompliantToVersion2AndPrior" ;
VAL_ 2628517630 VS_VolumeStatus 0 "Present" 1 "InUse" 2 "PreparingForRemoval" 3 "Removed" ;
VAL_ 2628517630 FSServerCommand 0 "CMFileServerStatus" 16 "DHGetCurrentDirectory" 32 "FAOpenFile" 33 "FASeekFile" 34 "FAReadFile" 35 "FAWriteFile" 36 "FACloseFile" 48 "FHMoveFile" 49 "FHDeleteFile" 50 "FHGetFileAttributes" 51 "FHSetFileAttribute" 17 "DHChangeCurrentDirectory" 52 "FHGetFileDateTime" 64 "VHVolumeInitialization" 1 "CMGetFileServerProperties" 2 "VSVolumeStatusResponse" ;
VAL_ 2364540158 EngStarterMode 15 "not available" 14 "error" 12 "starter inhibited  reason unknown" 9 "starter inhibited due to intake air shutoff valve being active" 8 "starter inhibited due to starter overtemp" 7 "starter inhibited due to active immobilizer" 6 "starter inhibited due to driveline engaged or other transmission inhibit" 5 "starter inhibited due to engine not ready for start preheating" 4 "starter inhibited due to engine already running" 3 "start finished starter not active after having been actively engaged after 50ms mode goes to 0000" 2 "starter active gear engaged" 1 "starter active gear not engaged" 0 "start not requested" 10 "starter inhibited due to active SCR inducement" 11 "Reserved" 13 "error legacy implementation only use 1110" ;
VAL_ 2364540158 ActlEngPrcntTorqueHighResolution 0 "0000" 1 "0125" 7 "0875" 8 "1111  not available" ;
VAL_ 2563309310 PGNumber 255 "NotAvailable" ;
VAL_ 2563309310 ControlByte 255 "EAbort" 20 "ERTS" 21 "ECTS" 22 "EDPO" 23 "EEoMACK" 24 "EAbort" ;
VAL_ 2563309310 ConnectionAbortReason 15 "ECTS requested packets exceeds message size" 14 "Unexpected ECTS PGN (PGN in ECTS is bad)" 13 "Deprecated use 254 instead" 12 "Bad EDPO offset" 11 "EDPO number of packets is greater than CTS" 10 "Unexpected EDPO PGN (PGN in EDPO is bad)" 9 "Unexpected EDPO packet" 8 "Duplicate sequence number" 1 "Already in one or more connection-managed sessions" 2 "System resources were needed for another task" 3 "Timeout occurred" 4 "CTS messages received when data transfer is in progress" 5 "Maximum retransmit request limit reached" 6 "Unexpected data transfer packet" 7 "Bad sequence number" ;
VAL_ 2583168510 RefrenceStationType1 14 "Error" 1 "GLONASS" 0 "GPS" ;
VAL_ 2583168510 GNSSIntegrity 3 "Unsafe" 2 "Caution" 1 "Safe" 0 "No integrity checking" ;
VAL_ 2583168510 GNSSMethod 14 "Error" 8 "Simulate mode" 7 "Manual input" 6 "Estimated (DR) mode" 5 "RTK float" 4 "RTK fixed integer" 3 "Precise GNSS" 2 "DGNSS fix" 1 "GNSS fix" 0 "no GPS" ;
VAL_ 2583168510 TypeOfSystem 4 "GPS and SBAS and GLONASS" 3 "GPS and SBAS(WAAS)" 2 "GPS and GLONASS" 1 "GLONASS" 0 "GPS" ;
VAL_ 2566849534 ManufacturerSpecific8 255 "NotAvailable" ;
VAL_ 2566849534 ManufacturerSpecific7 255 "NotAvailable" ;
VAL_ 2566849534 ManufacturerSpecific6 255 "NotAvailable" ;
VAL_ 2566849534 ManufacturerSpecific5 255 "NotAvailable" ;
VAL_ 2566849534 ManufacturerSpecific4 255 "NotAvailable" ;
VAL_ 2566849534 ManufacturerSpecific3 255 "NotAvailable" ;
VAL_ 2566849534 ManufacturerSpecific2 255 "NotAvailable" ;
VAL_ 2566849534 ManufacturerSpecific1 255 "NotAvailable" ;
VAL_ 2566849278 ManufacturerSpecific8 255 "NotAvailable" ;
VAL_ 2566849278 ManufacturerSpecific7 255 "NotAvailable" ;
VAL_ 2566849278 ManufacturerSpecific6 255 "NotAvailable" ;
VAL_ 2566849278 ManufacturerSpecific5 255 "NotAvailable" ;
VAL_ 2566849278 ManufacturerSpecific4 255 "NotAvailable" ;
VAL_ 2566849278 ManufacturerSpecific3 255 "NotAvailable" ;
VAL_ 2566849278 ManufacturerSpecific2 255 "NotAvailable" ;
VAL_ 2566849278 ManufacturerSpecific1 255 "NotAvailable" ;
VAL_ 2566849022 ManufacturerSpecific8 255 "NotAvailable" ;
VAL_ 2566849022 ManufacturerSpecific7 255 "NotAvailable" ;
VAL_ 2566849022 ManufacturerSpecific6 255 "NotAvailable" ;
VAL_ 2566849022 ManufacturerSpecific5 255 "NotAvailable" ;
VAL_ 2566849022 ManufacturerSpecific4 255 "NotAvailable" ;
VAL_ 2566849022 ManufacturerSpecific3 255 "NotAvailable" ;
VAL_ 2566849022 ManufacturerSpecific2 255 "NotAvailable" ;
VAL_ 2566849022 ManufacturerSpecific1 255 "NotAvailable" ;
VAL_ 2566848766 ManufacturerSpecific8 255 "NotAvailable" ;
VAL_ 2566848766 ManufacturerSpecific7 255 "NotAvailable" ;
VAL_ 2566848766 ManufacturerSpecific6 255 "NotAvailable" ;
VAL_ 2566848766 ManufacturerSpecific5 255 "NotAvailable" ;
VAL_ 2566848766 ManufacturerSpecific4 255 "NotAvailable" ;
VAL_ 2566848766 ManufacturerSpecific3 255 "NotAvailable" ;
VAL_ 2566848766 ManufacturerSpecific2 255 "NotAvailable" ;
VAL_ 2566848766 ManufacturerSpecific1 255 "NotAvailable" ;
VAL_ 2365475326 GroundBasedMachineDirection 3 "NotAvailable" 2 "ErrorIndication" 1 "Forward" 0 "Reverse" ;
VAL_ 2365475070 OperatorDirectionReversed 0 "Not reversed" 1 "Reversed" 2 "Error" 3 "Not available" ;
VAL_ 2365475070 StartStopState 3 "Don't Care" 2 "Reserved" 1 "Start or enable implement work" 0 "Stop or disable implement work" ;
VAL_ 2365475070 KeySwitchState 3 "NotAvailable" 2 "ErrorIndication" 1 "KeySwitchNotOff" 0 "KeySwitchOff" ;
VAL_ 2365475070 WheelBasedMachineDirection 3 "NotAvailable" 2 "ErrorIndicator" 1 "Forward" 0 "Reverse" ;
VAL_ 2566801406 ImplementInWorkState 3 "Not available" 2 "Error indication" 1 "Implement is in work state" 0 "Implement is not in work state" ;
VAL_ 2566801406 ImplementTransportState 3 "Not available" 2 "Error indication" 1 "Implement may be transported" 0 "Implement may not be transported" ;
VAL_ 2566801406 ImplementParkState 3 "Not available" 2 "Error indication" 1 "Implement may be disconnected" 0 "Implement may not be disconnected" ;
VAL_ 2566801406 ImplementReadyToWorkState 3 "Not available" 2 "Error indication" 1 "Implement is ready for field work" 0 "Implement is not ready for field work" ;
VAL_ 2566801406 MaintainECUPower 3 "DoNotCare" 1 "RequireForTwoMoreSecOfECU_PWR" 0 "NoFurtherRequireForECU_PWR" ;
VAL_ 2566801406 MaintainActuatorPower 3 "DoNotCare" 1 "RequireForTwoMoreSecOfPWR" 0 "NoFurtherRequirementForPWR" ;
VAL_ 2365474558 FrontHitchExitReasonCode 0 "No reason/all clear " 1 "Operator presence not detected" 2 "Implement released control of function" 3 "Operator override of function " 4 "Operator control not in valid position " 5 "Remote command timeout " 6 "Remote command out of range/invalid " 7 "Function not calibrated " 8 "Operator control fault " 9 "Function fault " 20 "Hydraulic oil level too low " 21 "Hitch locked out " 62 "Error" 63 "Not available (parameter not supported) " ;
VAL_ 2365474558 FrontHitchInWorkIndication 3 "NotAvailable" 2 "ErrorIndication" 1 "HitchPositionIsInWorl" 0 "HitchPositionIsOutOfWork" ;
VAL_ 2365474558 FrontHitchPositionLimitStatus 0 "Not limited" 1 "Operator Limited" 2 "Limited High" 3 "Limited Low" 4 "Reserved" 5 "Reserver" 6 "Non-recoverable Fault" 7 "Not available" ;
VAL_ 2365474302 RearHitchExitReasonCode 0 "No reason/all clear " 1 "Operator presence not detected" 2 "Implement released control of function" 3 "Operator override of function " 4 "Operator control not in valid position " 5 "Remote command timeout " 6 "Remote command out of range/invalid " 7 "Function not calibrated " 8 "Operator control fault " 9 "Function fault " 20 "Hydraulic oil level too low " 21 "Hitch locked out " 62 "Error" 63 "Not available (parameter not supported) " ;
VAL_ 2365474302 RearHitchInWorkIndication 3 "NotAvailable" 2 "ErrorIndication" 1 "HitchPositionIsInWork" 0 "HitchPositionIsOutOfWork" ;
VAL_ 2365474302 RearHitchPositionLimitStatus 0 "Not limited" 1 "Operator Limited" 2 "Limited High" 3 "Limited Low" 4 "Reserved" 5 "Reserver" 6 "Non-recoverable Fault" 7 "Not available" ;
VAL_ 2365474046 FrontPTOExitReasonCode 0 "No reason/all clear" 1 "Operator presence not detected" 2 "Implement released control of function" 3 "Operator override of function " 4 "Operator control not in valid position " 5 "Remote command timeout " 6 "Remote command out of range/invalid " 7 "Function not calibrated " 8 "Operator control fault " 9 "Function fault " 20 "Invalid PTO gear" 62 "Error " 63 "Not available (parameter not supported)" ;
VAL_ 2365474046 FrontPTOModeRqStatus 0 "External Request accepted" 1 "Control Override" 2 "Error" 3 "Not available" ;
VAL_ 2365474046 FrontPTOEconomyModeRqStatus 0 "External Request accepted" 1 "Control Override" 2 "Error" 3 "Not available" ;
VAL_ 2365474046 FrontPTOShaftSpeedLimitStatus 0 "Not limited" 1 "Operator Limited" 2 "Limited High" 3 "Limited Low" 4 "Reserved" 5 "Reserver" 6 "Non-recoverable Fault" 7 "Not available" ;
VAL_ 2365474046 FrontPTOEngagement 3 "NotAvailable" 2 "ErrorIndication" 1 "PTOEngaged" 0 "PTODisengaged" ;
VAL_ 2365474046 FrontPTOMode 3 "NotAvailable" 2 "ErrorIndication" 1 "PTOModeIs1000" 0 "PTOModeIs540" ;
VAL_ 2365474046 FrontPTOEconomyMode 3 "NotAvailable" 2 "ErrorIndication" 1 "PTOEconomyModeIsEngaged" 0 "PTOEconomyModeIsDisengaged" ;
VAL_ 2365474046 FrontPTOEngagementRqStatus 0 "External Request accepted" 1 "Control Override" 2 "Error" 3 "Not available" ;
VAL_ 2365473790 RearPTOExitReasonCode 0 "No reason/all clear" 1 "Operator presence not detected" 2 "Implement released control of function" 3 "Operator override of function " 4 "Operator control not in valid position " 5 "Remote command timeout " 6 "Remote command out of range/invalid " 7 "Function not calibrated " 8 "Operator control fault " 9 "Function fault " 20 "Invalid PTO gear" 62 "Error " 63 "Not available (parameter not supported)" ;
VAL_ 2365473790 RearPTOModeRqStatus 0 "External Request accepted" 1 "Control Override" 2 "Error" 3 "Not available" ;
VAL_ 2365473790 RearPTOEconomyModeRqStatus 0 "External Request accepted" 1 "Control Override" 2 "Error" 3 "Not available" ;
VAL_ 2365473790 RearPTOShaftSpeedLimitStatus 0 "Not limited" 1 "Operator Limited" 2 "Limited High" 3 "Limited Low" 4 "Reserved" 5 "Reserver" 6 "Non-recoverable Fault" 7 "Not available" ;
VAL_ 2365473790 RearPTOEngagement 3 "NotAvailable" 2 "ErrorIndication" 1 "PTOEngaged" 0 "PTODisengaged" ;
VAL_ 2365473790 RearPTOMode 3 "NotAvailable" 2 "ErrorIndication" 1 "PTOModeIs1000" 0 "PTOModeIs540" ;
VAL_ 2365473790 RearPTOEconomyMode 3 "NotAvailabel" 2 "ErrorIndication" 1 "PTOEconomyModeIsEngaged" 0 "PTOEconomyModeIsDisengaged" ;
VAL_ 2365473790 RearPTOEngagementRqStatus 0 "External Request accepted" 1 "Control Override" 2 "Error" 3 "Not available" ;
VAL_ 2365473534 FrontPTOModeCmd 3 "DoNotCare" 1 "Select1000rpmMode" 0 "Select540rpmMode" ;
VAL_ 2365473534 RearPTOModeCmd 3 "DoNotCare" 1 "Select1000rpmMode" 0 "Select540rpmMode" ;
VAL_ 2365473534 FrontPTOEconomyModeCmd 3 "DoNotCare" 1 "EngagePTOEconomyMode" 0 "DisengagePTOEconomyMode" ;
VAL_ 2365473534 RearPTOEconomyModeCmd 3 "DoNotCare" 1 "EngagePTOEconomyMode" 0 "DisengagePTOEconomyMode" ;
VAL_ 2365473534 FrontPTOEngagementCmd 3 "DoNotCare" 1 "EngagePTO" 0 "DisengagePTO" ;
VAL_ 2365473534 RearPTOEngagementCmd 3 "DoNotCare" 1 "EngangePTO" 0 "DisengagePTO" ;
VAL_ 2365473278 ImplementRearWorkLightCmd 0 "Deactivate" 1 "Activate" 2 "Reserved" 3 "Dont Care" ;
VAL_ 2365473278 ImplementLeftFacingWorkLightCmd 3 "Dont Care" 1 "Activate" 0 "Deactivate" 2 "Reserved" ;
VAL_ 2365473278 ImplementRightFacingWorkLightCmd 0 "Deactivate" 1 "Activate" 2 "Reserved" 3 "Dont Care" ;
VAL_ 2365473278 LightingDataRequestCmd 3 "DoNotCare" 1 "Acitvate" 0 "Deactivate" ;
VAL_ 2365473278 ImplementLeftForwardLightCmd 3 "DoNotCare" 1 "Acitvate" 0 "Deactivate" ;
VAL_ 2365473278 ImplementRightForwardLightCmd 3 "DoNotCare" 1 "Acitvate" 0 "Deactivate" ;
VAL_ 2365473278 ImplementOEMOption1LightCmd 0 "Deactivate" 1 "Activate" 2 "Reserved" 3 "Dont Care" ;
VAL_ 2365473278 ImplementOEMOption2LightCmd 0 "Deactivate" 1 "Activate" 2 "Reserved" 3 "Dont Care" ;
VAL_ 2365473278 TractorFrontHighWorkLightCmd 3 "DoNotCare" 1 "Acitvate" 0 "Deactivate" ;
VAL_ 2365473278 TractorFrontLowWorkLightCmd 3 "DoNotCare" 1 "Acitvate" 0 "Deactivate" ;
VAL_ 2365473278 TractorSideHighWorkLightCmd 3 "DoNotCare" 1 "Acitvate" 0 "Deactivate" ;
VAL_ 2365473278 TractorSideLowWorkLightCmd 3 "DoNotCare" 1 "Acitvate" 0 "Deactivate" ;
VAL_ 2365473278 TractorRearHighWorkLightCmd 3 "DoNotCare" 1 "Acitvate" 0 "Deactivate" ;
VAL_ 2365473278 TractorRearLowWorkLightCmd 3 "DoNotCare" 1 "Acitvate" 0 "Deactivate" ;
VAL_ 2365473278 TractorUndersideWorkLightCmd 3 "DoNotCare" 1 "Acitvate" 0 "Deactivate" ;
VAL_ 2365473278 RearFogLightCmd 3 "Dont Care" 1 "Activate" 0 "Deactivate" 2 "Reserved" ;
VAL_ 2365473278 TractorMarkerLightCmd 3 "Dont Care" 1 "Activate" 0 "Deactivate" 2 "Reserved" ;
VAL_ 2365473278 ImplementMarkerLightCmd 3 "Dont Care" 1 "Activate" 0 "Deactivate" 2 "Reserved" ;
VAL_ 2365473278 TractorClearanceLightCmd 3 "Dont Care" 1 "Activate" 0 "Deactivate" 2 "Reserved" ;
VAL_ 2365473278 ImplementClearanceLightCmd 3 "Dont Care" 1 "Activate" 0 "Deactivate" 2 "Reserved" ;
VAL_ 2365473278 LeftStopLightCmd 3 "Dont Care" 1 "Activate" 0 "Deactivate" 2 "Reserved" ;
VAL_ 2365473278 RightStopLightCmd 0 "Deactivate" 1 "Activate" 2 "Reserved" 3 "Dont Care" ;
VAL_ 2365473278 CentreStopLightCmd 3 "DoNotCare" 1 "Acitvate" 0 "Deactivate" ;
VAL_ 2365473278 BackUpLightAndAlarmHornCmd 3 "Dont Care" 1 "Activate" 0 "Deactivate" 2 "Reserved" ;
VAL_ 2365473278 LeftTurnSignalLightCmd 3 "DoNotCare" 1 "Activate" 0 "Deactivate" ;
VAL_ 2365473278 RightTurnSignalLightCmd 3 "DoNotCare" 1 "Activate" 0 "Deactivate" ;
VAL_ 2365473278 RotatingBeaconLightCmd 0 "Deactivate" 1 "Activate" 2 "Reserved" 3 "Dont Care" ;
VAL_ 2365473278 TractorFrontFogLightCmd 3 "DoNotCare" 1 "Activate" 0 "Deactivate" ;
VAL_ 2365473278 HighBeamHeadLightCmd 3 "Dont Care" 1 "Activate" 0 "Deactivate" 2 "Reserved" ;
VAL_ 2365473278 LowBeamHeadLightCmd 3 "Dont Care" 1 "Activate" 0 "Deactivate" 2 "Reserved" ;
VAL_ 2365473278 AlternateHeadLightCmd 3 "DoNotCare" 1 "Activate" 0 "Deactivate" ;
VAL_ 2365473278 DaytimeRunningLightCmd 3 "DoNotCare" 1 "Activate" 0 "Deactivate" ;
VAL_ 2566799614 ImplementRearWorkLightData 3 "NotAvailable" 2 "FaultDetected" 1 "Activated" 0 "Deactivated" ;
VAL_ 2566799614 ImplLeftFacingWorkLightData 3 "NotAvailable" 2 "FaultDetected" 1 "Activated" 0 "Deactivated" ;
VAL_ 2566799614 ImplRightFacingWorkLightData 3 "NotAvailable" 2 "FaultDetected" 1 "Activated" 0 "Deactivated" ;
VAL_ 2566799614 ImplementLeftForwardLightData 3 "NotAvailable" 2 "FaultDetected" 1 "Activated" 0 "Deactivated" ;
VAL_ 2566799614 ImplementRightForwardLightData 3 "NotAvailable" 2 "FaultDetected" 1 "Activated" 0 "Deactivated" ;
VAL_ 2566799614 ImplementOEMOption1LightData 3 "NotAvailable" 2 "FaultDetected" 1 "Activated" 0 "Deactivated" ;
VAL_ 2566799614 ImplementOEMOption2LightData 3 "NotAvailable" 2 "FaultDetected" 1 "Activated" 0 "Deactivated" ;
VAL_ 2566799614 TractorFrontHighWorkLightData 3 "NotAvailable" 2 "FaultDetected" 1 "Activated" 0 "Deactivated" ;
VAL_ 2566799614 TractorFrontLowWorkLightData 3 "NotAvailable" 2 "FaultDetected" 1 "Activated" 0 "Deactivated" ;
VAL_ 2566799614 TractorSideHighWorkLightData 3 "NotAvailable" 2 "FaultDetected" 1 "Activated" 0 "Deactivated" ;
VAL_ 2566799614 TractorSideLowWorkLightData 3 "NotAvailable" 2 "FaultDetected" 1 "Activated" 0 "Deactivated" ;
VAL_ 2566799614 TractorRearHighWorkLightData 3 "NotAvailable" 2 "FaultDetected" 1 "Activated" 0 "Deactivated" ;
VAL_ 2566799614 TractorRearLowWorkLightData 3 "NotAvailable" 2 "FaultDetected" 1 "Activated" 0 "Deactivated" ;
VAL_ 2566799614 TractorUndersideWorkLightData 3 "NotAvailable" 2 "FaultDetected" 1 "Activated" 0 "Deactivated" ;
VAL_ 2566799614 RearFogLightData 3 "NotAvailable" 2 "FaultDetected" 1 "Activated" 0 "Deactivated" ;
VAL_ 2566799614 TractorMarkerLightData 3 "NotAvailable" 2 "FaultDetected" 1 "Activated" 0 "Deactivated" ;
VAL_ 2566799614 ImplementMarkerLightData 3 "NotAvailable" 2 "FaultDetected" 1 "Activated" 0 "Deactivated" ;
VAL_ 2566799614 TractorClearanceLightData 3 "NotAvailable" 2 "FaultDetected" 1 "Activated" 0 "Deactivated" ;
VAL_ 2566799614 ImplementClearanceLightData 3 "NotAvailable" 2 "FaultDetected" 1 "Activated" 0 "Deactivated" ;
VAL_ 2566799614 LefttStopLightData 3 "NotAvailable" 2 "FaultDetected" 1 "Activated" 0 "Deactivated" ;
VAL_ 2566799614 RightStopLightData 3 "NotAvailable" 2 "FaultDetected" 1 "Activated" 0 "Deactivated" ;
VAL_ 2566799614 CentreStopLightData 3 "NotAvailable" 2 "FaultDetected" 1 "Activated" 0 "Deactivated" ;
VAL_ 2566799614 BackUpLightAndAlarmHornData 3 "NotAvailable" 2 "FaultDetected" 1 "Activated" 0 "Deactivated" ;
VAL_ 2566799614 LeftTurnSignalLightData 3 "NotAvailable" 2 "FaultDetected" 1 "Activated" 0 "Deactivated" ;
VAL_ 2566799614 RightTurnSignalLightData 3 "NotAvailable" 2 "FaultDetected" 1 "Activated" 0 "Deactivated" ;
VAL_ 2566799614 RotationBeaconLightData 3 "NotAvailable" 2 "FaultDetected" 1 "Activated" 0 "Deactivated" ;
VAL_ 2566799614 TractorFrontFogLightData 3 "NotAvailable" 2 "FaultDetected" 1 "Activated" 0 "Deactivated" ;
VAL_ 2566799614 HighBeamHeadLightData 3 "Not Available" 2 "Fault Detected" 1 "Activated" 0 "Deactivated" ;
VAL_ 2566799614 LowBeamHeadLightData 3 "Not Available" 2 "Fault Detected" 1 "Activated" 0 "Deactivated" ;
VAL_ 2566799614 AlternateHeadLightData 3 "NotAvailable" 2 "FaultDetected" 1 "Activated" 0 "Deactivated" ;
VAL_ 2566799614 DaytimeRunningLightData 3 "NotAvailable" 2 "FaultDetected" 1 "Activated" 0 "Deactivated" ;
VAL_ 2365472766 Valve15FailSaveModeCmd 3 "DoNotCare" 1 "Float" 0 "Block" ;
VAL_ 2365472766 Valve15StateCmd 15 "Reserved" 3 "Float" 2 "Retract" 1 "Extend" 0 "Block" ;
VAL_ 2365472510 Valve14FailSaveModeCmd 3 "DoNotCare" 1 "Float" 0 "Block" ;
VAL_ 2365472510 Valve14StateCmd 15 "Reserved" 3 "Float" 2 "Retract" 1 "Extend" 0 "Block" ;
VAL_ 2365472254 Valve13FailSaveModeCmd 3 "DoNotCare" 1 "Float" 0 "Block" ;
VAL_ 2365472254 Valve13StateCmd 15 "Reserved" 3 "Float" 2 "Retract" 1 "Extend" 0 "Block" ;
VAL_ 2365471998 Valve12FailSaveModeCmd 3 "DoNotCare" 1 "Float" 0 "Block" ;
VAL_ 2365471998 Valve12StateCmd 15 "Reserved" 3 "Float" 2 "Retract" 1 "Extend" 0 "Block" ;
VAL_ 2365471742 Valve11FailSaveModeCmd 3 "DoNotCare" 1 "Float" 0 "Block" ;
VAL_ 2365471742 Valve11StateCmd 15 "Reserved" 3 "Float" 2 "Retract" 1 "Extend" 0 "Block" ;
VAL_ 2365471486 Valve10FailSaveModeCmd 3 "DoNotCare" 1 "Float" 0 "Block" ;
VAL_ 2365471486 Valve10StateCmd 15 "Reserved" 3 "Float" 2 "Retract" 1 "Extend" 0 "Block" ;
VAL_ 2365471230 Valve9FailSaveModeCmd 3 "DoNotCare" 1 "Float" 0 "Block" ;
VAL_ 2365471230 Valve9StateCmd 15 "Reserved" 3 "Float" 2 "Retract" 1 "Extend" 0 "Block" ;
VAL_ 2365470974 Valve8FailSaveModeCmd 3 "DoNotCare" 1 "Float" 0 "Block" ;
VAL_ 2365470974 Valve8StateCmd 15 "Reserved" 3 "Float" 2 "Retract" 1 "Extend" 0 "Block" ;
VAL_ 2365470718 Valve7FailSaveModeCmd 3 "DoNotCare" 1 "Float" 0 "Block" ;
VAL_ 2365470718 Valve7StateCmd 15 "Reserved" 3 "Float" 2 "Retract" 1 "Extend" 0 "Block" ;
VAL_ 2365470462 Valve6FailSaveModeCmd 3 "DoNotCare" 1 "Float" 0 "Block" ;
VAL_ 2365470462 Valve6StateCmd 15 "Reserved" 3 "Float" 2 "Retract" 1 "Extend" 0 "Block" ;
VAL_ 2365470206 Valve5FailSaveModeCmd 3 "DoNotCare" 1 "Float" 0 "Block" ;
VAL_ 2365470206 Valve5StateCmd 15 "Reserved" 3 "Float" 2 "Retract" 1 "Extend" 0 "Block" ;
VAL_ 2365469950 Valve4FailSaveModeCmd 3 "DoNotCare" 1 "Float" 0 "Block" ;
VAL_ 2365469950 Valve4StateCmd 15 "Reserved" 3 "Float" 2 "Retract" 1 "Extend" 0 "Block" ;
VAL_ 2365469694 Valve3FailSaveModeCmd 3 "DoNotCare" 1 "Float" 0 "Block" ;
VAL_ 2365469694 Valve3StateCmd 15 "Reserved" 3 "Float" 2 "Retract" 1 "Extend" 0 "Block" ;
VAL_ 2365469438 Valve2FailSaveModeCmd 3 "DoNotCare" 1 "Float" 0 "Block" ;
VAL_ 2365469438 Valve2StateCmd 15 "Reserved" 3 "Float" 2 "Retract" 1 "Extend" 0 "Block" ;
VAL_ 2365469182 Valve1FailSaveModeCmd 3 "DoNotCare" 1 "Float" 0 "Block" ;
VAL_ 2365469182 Valve1StateCmd 15 "Reserved" 3 "Float" 2 "Retract" 1 "Extend" 0 "Block" ;
VAL_ 2365468926 Valve0FailSaveModeCmd 3 "DoNotCare" 1 "Float" 0 "Block" ;
VAL_ 2365468926 Valve0StateCmd 15 "Reserved" 3 "Float" 2 "Retract" 1 "Extend" 0 "Block" ;
VAL_ 2365468670 Valve15LimitStatus 0 "Not limited" 1 "Operator Limited" 2 "Limited High" 3 "Limited Low" 4 "Reserved" 5 "Reserver" 6 "Non-recoverable Fault" 7 "Not available" ;
VAL_ 2365468414 Valve14LimitStatus 0 "Not limited" 1 "Operator Limited" 2 "Limited High" 3 "Limited Low" 4 "Reserved" 5 "Reserver" 6 "Non-recoverable Fault" 7 "Not available" ;
VAL_ 2365468158 Valve13LimitStatus 0 "Not limited" 1 "Operator Limited" 2 "Limited High" 3 "Limited Low" 4 "Reserved" 5 "Reserver" 6 "Non-recoverable Fault" 7 "Not available" ;
VAL_ 2365467902 Valve12LimitStatus 0 "Not limited" 1 "Operator Limited" 2 "Limited High" 3 "Limited Low" 4 "Reserved" 5 "Reserver" 6 "Non-recoverable Fault" 7 "Not available" ;
VAL_ 2365467646 Valve11LimitStatus 0 "Not limited" 1 "Operator Limited" 2 "Limited High" 3 "Limited Low" 4 "Reserved" 5 "Reserver" 6 "Non-recoverable Fault" 7 "Not available" ;
VAL_ 2365467390 Valve10LimitStatus 0 "Not limited" 1 "Operator Limited" 2 "Limited High" 3 "Limited Low" 4 "Reserved" 5 "Reserver" 6 "Non-recoverable Fault" 7 "Not available" ;
VAL_ 2365467134 Valve9LimitStatus 0 "Not limited" 1 "Operator Limited" 2 "Limited High" 3 "Limited Low" 4 "Reserved" 5 "Reserver" 6 "Non-recoverable Fault" 7 "Not available" ;
VAL_ 2365466878 Valve8LimitStatus 0 "Not limited" 1 "Operator Limited" 2 "Limited High" 3 "Limited Low" 4 "Reserved" 5 "Reserver" 6 "Non-recoverable Fault" 7 "Not available" ;
VAL_ 2365466622 Valve7LimitStatus 0 "Not limited" 1 "Operator Limited" 2 "Limited High" 3 "Limited Low" 4 "Reserved" 5 "Reserver" 6 "Non-recoverable Fault" 7 "Not available" ;
VAL_ 2365466366 Valve6LimitStatus 0 "Not limited" 1 "Operator Limited" 2 "Limited High" 3 "Limited Low" 4 "Reserved" 5 "Reserver" 6 "Non-recoverable Fault" 7 "Not available" ;
VAL_ 2365466110 Valve5LimitStatus 0 "Not limited" 1 "Operator Limited" 2 "Limited High" 3 "Limited Low" 4 "Reserved" 5 "Reserver" 6 "Non-recoverable Fault" 7 "Not available" ;
VAL_ 2365465854 Valve4LimitStatus 0 "Not limited" 1 "Operator Limited" 2 "Limited High" 3 "Limited Low" 4 "Reserved" 5 "Reserver" 6 "Non-recoverable Fault" 7 "Not available" ;
VAL_ 2365465598 Valve3LimitStatus 0 "Not limited" 1 "Operator Limited" 2 "Limited High" 3 "Limited Low" 4 "Reserved" 5 "Reserver" 6 "Non-recoverable Fault" 7 "Not available" ;
VAL_ 2365465342 Valve2LimitStatus 0 "Not limited" 1 "Operator Limited" 2 "Limited High" 3 "Limited Low" 4 "Reserved" 5 "Reserver" 6 "Non-recoverable Fault" 7 "Not available" ;
SIG_VALTYPE_ 2565340800 ZoomValue_PanZoom : 1;
SIG_VALTYPE_ 2565340800 ZoomValue : 1;
SG_MUL_VAL_ 2565340800 UnsupportedVtFunction VTFunctionECUtoVT 253-253;
SG_MUL_VAL_ 2565340800 AuxiliaryInputID_1 VTFunctionECUtoVT 34-34;
SG_MUL_VAL_ 2565340800 AuxiliaryFunctionID_1 VTFunctionECUtoVT 34-34;
SG_MUL_VAL_ 2565340800 NumOfPreferredFunctions VTFunctionECUtoVT 34-34;
SG_MUL_VAL_ 2565340800 ModelIdentificationCode VTFunctionECUtoVT 34-34;
SG_MUL_VAL_ 2565340800 ArbitraryAddressCapable VTFunctionECUtoVT 34-34;
SG_MUL_VAL_ 2565340800 IndustryGroup VTFunctionECUtoVT 34-34;
SG_MUL_VAL_ 2565340800 VehicleSystemInstance VTFunctionECUtoVT 34-34;
SG_MUL_VAL_ 2565340800 VehicleSystem2 VTFunctionECUtoVT 34-34;
SG_MUL_VAL_ 2565340800 ZoomValue_PanZoom SubCommandID 16-16;
SG_MUL_VAL_ 2565340800 OperatingState2 VTFunctionECUtoVT 33-33;
SG_MUL_VAL_ 2565340800 Function VTFunctionECUtoVT 34-34;
SG_MUL_VAL_ 2565340800 OperatingState1 VTFunctionECUtoVT 33-33;
SG_MUL_VAL_ 2565340800 YPosChangeTopLeftLong VTFunctionECUtoVT 180-180;
SG_MUL_VAL_ 2565340800 LineDirection VTFunctionECUtoVT 169-169;
SG_MUL_VAL_ 2565340800 FunctionInstance VTFunctionECUtoVT 34-34;
SG_MUL_VAL_ 2565340800 ECUInstance VTFunctionECUtoVT 34-34;
SG_MUL_VAL_ 2565340800 NewValueY VTFunctionECUtoVT 182-182;
SG_MUL_VAL_ 2565340800 GraphicRepresentationObjectID VTFunctionECUtoVT 181-181;
SG_MUL_VAL_ 2565340800 FontStyle VTFunctionECUtoVT 170-170;
SG_MUL_VAL_ 2565340800 YPosChangeTopLeft VTFunctionECUtoVT 165-165;
SG_MUL_VAL_ 2565340800 OffTimeDuration_Audio VTFunctionECUtoVT 163-163;
SG_MUL_VAL_ 2565340800 ButtonKeyCode VTFunctionECUtoVT 1-1;
SG_MUL_VAL_ 2565340800 SoftKeyCode VTFunctionECUtoVT 0-0;
SG_MUL_VAL_ 2565340800 Status_2 VTFunctionECUtoVT 9-9;
SG_MUL_VAL_ 2565340800 NewViewportHeight SubCommandID 17-17;
SG_MUL_VAL_ 2565340800 ViewportY_PanZoom SubCommandID 16-16;
SG_MUL_VAL_ 2565340800 ViewportY SubCommandID 14-14;
SG_MUL_VAL_ 2565340800 EllipseHeight SubCommandID 11-11;
SG_MUL_VAL_ 2565340800 RectangleHeight_Draw SubCommandID 10-10;
SG_MUL_VAL_ 2565340800 EndPixelOffsetY SubCommandID 9-9;
SG_MUL_VAL_ 2565340800 PixelOffsetY SubCommandID 8-8;
SG_MUL_VAL_ 2565340800 CursorOffsetY SubCommandID 1-1;
SG_MUL_VAL_ 2565340800 CursorPosY SubCommandID 0-0;
SG_MUL_VAL_ 2565340800 NewStringValue VTFunctionECUtoVT 179-179;
SG_MUL_VAL_ 2565340800 Value2 VTFunctionECUtoVT 33-33;
SG_MUL_VAL_ 2565340800 NewHeigthAttribute VTFunctionECUtoVT 183-183;
SG_MUL_VAL_ 2565340800 FontType VTFunctionECUtoVT 170-170;
SG_MUL_VAL_ 2565340800 XPosChangeTopLeftLong VTFunctionECUtoVT 180-180;
SG_MUL_VAL_ 2565340800 FillPatternObjectID VTFunctionECUtoVT 172-172;
SG_MUL_VAL_ 2565340800 LineArt VTFunctionECUtoVT 171-171;
SG_MUL_VAL_ 2565340800 LabelFontType VTFunctionECUtoVT 181-181;
SG_MUL_VAL_ 2565340800 Height VTFunctionECUtoVT 169-169;
SG_MUL_VAL_ 2565340800 NewHeight VTFunctionECUtoVT 166-166;
SG_MUL_VAL_ 2565340800 XPosChangeTopLeft VTFunctionECUtoVT 165-165;
SG_MUL_VAL_ 2565340800 TouchState VTFunctionECUtoVT 2-2;
SG_MUL_VAL_ 2565340800 TextLength SubCommandID 13-13;
SG_MUL_VAL_ 2565340800 ManufacturerCode VTFunctionECUtoVT 34-34;
SG_MUL_VAL_ 2565340800 AuxErrorAnyOther VTFunctionECUtoVT 37-37;
SG_MUL_VAL_ 2565340800 CursorPosX SubCommandID 0-0;
SG_MUL_VAL_ 2565340800 CursorOffsetX SubCommandID 1-1;
SG_MUL_VAL_ 2565340800 ForegroundColour SubCommandID 2-2;
SG_MUL_VAL_ 2565340800 BackgroundColour SubCommandID 3-3;
SG_MUL_VAL_ 2565340800 LineAttributesObjectID SubCommandID 4-4;
SG_MUL_VAL_ 2565340800 FillAttributesObjectID SubCommandID 5-5;
SG_MUL_VAL_ 2565340800 FontAttributesObjectID SubCommandID 6-6;
SG_MUL_VAL_ 2565340800 RectangleWidth_Erase SubCommandID 7-7;
SG_MUL_VAL_ 2565340800 RectangleHeight_Erase SubCommandID 7-7;
SG_MUL_VAL_ 2565340800 PixelOffsetX SubCommandID 8-8;
SG_MUL_VAL_ 2565340800 EndPixelOffsetX SubCommandID 9-9;
SG_MUL_VAL_ 2565340800 RectangleWidth_Draw SubCommandID 10-10;
SG_MUL_VAL_ 2565340800 EllipseWidth SubCommandID 11-11;
SG_MUL_VAL_ 2565340800 NumberOfPoints SubCommandID 12-12;
SG_MUL_VAL_ 2565340800 TextOption SubCommandID 13-13;
SG_MUL_VAL_ 2565340800 ViewportX SubCommandID 14-14;
SG_MUL_VAL_ 2565340800 ZoomValue SubCommandID 15-15;
SG_MUL_VAL_ 2565340800 ViewportX_PanZoom SubCommandID 16-16;
SG_MUL_VAL_ 2565340800 NewViewportWidth SubCommandID 17-17;
SG_MUL_VAL_ 2565340800 ObjectID SubCommandID 18-18;
SG_MUL_VAL_ 2565340800 PictureGraphicsID_Canvas SubCommandID 19-19;
SG_MUL_VAL_ 2565340800 PictureGraphicsID_Viewport SubCommandID 20-20;
SG_MUL_VAL_ 2565340800 LastWideChar VTFunctionECUtoVT 193-193;
SG_MUL_VAL_ 2565340800 LockTimeout VTFunctionECUtoVT 189-189;
SG_MUL_VAL_ 2565340800 NewValueX VTFunctionECUtoVT 182-182;
SG_MUL_VAL_ 2565340800 NewObjectID VTFunctionECUtoVT 177-177;
SG_MUL_VAL_ 2565340800 NewAttributeValue VTFunctionECUtoVT 175-175;
SG_MUL_VAL_ 2565340800 NewSoftKeyMaskObjectID VTFunctionECUtoVT 174-174;
SG_MUL_VAL_ 2565340800 FillColour VTFunctionECUtoVT 172-172;
SG_MUL_VAL_ 2565340800 LineWidth VTFunctionECUtoVT 171-171;
SG_MUL_VAL_ 2565340800 FontSize VTFunctionECUtoVT 170-170;
SG_MUL_VAL_ 2565340800 NewValue VTFunctionECUtoVT 168-168;
SG_MUL_VAL_ 2565340800 OnTimeDuration_Audio VTFunctionECUtoVT 163-163;
SG_MUL_VAL_ 2565340800 AuxErrorInvalidInputID VTFunctionECUtoVT 37-37;
SG_MUL_VAL_ 2565340800 VTChangeNumericValueValue VTFunctionECUtoVT 5-5;
SG_MUL_VAL_ 2565340800 ButtonObjectParentID VTFunctionECUtoVT 1-1;
SG_MUL_VAL_ 2565340800 KeyObjectParentID VTFunctionECUtoVT 0-0;
SG_MUL_VAL_ 2565340800 ObjectId_2 VTFunctionECUtoVT 9-9;
SG_MUL_VAL_ 2565340800 Value1 VTFunctionECUtoVT 33-33;
SG_MUL_VAL_ 2565340800 TotalNumberOfBytes VTFunctionECUtoVT 179-179;
SG_MUL_VAL_ 2565340800 AttributeIDToChange VTFunctionECUtoVT 175-175;
SG_MUL_VAL_ 2565340800 SubCommandID VTFunctionECUtoVT 184-184;
SG_MUL_VAL_ 2565340800 NewWidthAttribute VTFunctionECUtoVT 183-183;
SG_MUL_VAL_ 2565340800 IndexOfThePointToReplace VTFunctionECUtoVT 182-182;
SG_MUL_VAL_ 2565340800 StringVariableObjectID VTFunctionECUtoVT 181-181;
SG_MUL_VAL_ 2565340800 ChangeChildLocationObjectID VTFunctionECUtoVT 165-165;
SG_MUL_VAL_ 2565340800 ListIndex VTFunctionECUtoVT 177-177;
SG_MUL_VAL_ 2565340800 NewPriority VTFunctionECUtoVT 176-176;
SG_MUL_VAL_ 2565340800 AttributeID VTFunctionECUtoVT 185-185;
SG_MUL_VAL_ 2565340800 NewActiveMaskObjectID VTFunctionECUtoVT 173-173;
SG_MUL_VAL_ 2565340800 FillType VTFunctionECUtoVT 172-172;
SG_MUL_VAL_ 2565340800 LineColour VTFunctionECUtoVT 171-171;
SG_MUL_VAL_ 2565340800 FontColour VTFunctionECUtoVT 170-170;
SG_MUL_VAL_ 2565340800 Width VTFunctionECUtoVT 169-169;
SG_MUL_VAL_ 2565340800 NewBackgroundColour VTFunctionECUtoVT 167-167;
SG_MUL_VAL_ 2565340800 NewWidth VTFunctionECUtoVT 166-166;
SG_MUL_VAL_ 2565340800 ChangeChildPositionObjectID VTFunctionECUtoVT 180-180;
SG_MUL_VAL_ 2565340800 SetFocusOpenForEditing VTFunctionECUtoVT 162-162;
SG_MUL_VAL_ 2565340800 EnableOrDisable VTFunctionECUtoVT 161-161;
SG_MUL_VAL_ 2565340800 ShowOrHide VTFunctionECUtoVT 160-160;
SG_MUL_VAL_ 2565340800 AuxInputEnable VTFunctionECUtoVT 37-37;
SG_MUL_VAL_ 2565340800 AssignmentErrorNotAccepted VTFunctionECUtoVT 36-36;
SG_MUL_VAL_ 2565340800 ObjectOfChangedStringValueID VTFunctionECUtoVT 8-8;
SG_MUL_VAL_ 2565340800 VTChangeSoftKeyMaskObjectID VTFunctionECUtoVT 7-7;
SG_MUL_VAL_ 2565340800 VTSelectInputObjectStatus VTFunctionECUtoVT 3-3;
SG_MUL_VAL_ 2565340800 YPosition VTFunctionECUtoVT 2-2;
SG_MUL_VAL_ 2565340800 AuxiliaryFunctionID VTFunctionECUtoVT 32-32;
SG_MUL_VAL_ 2565340800 Status_1 VTFunctionECUtoVT 9-9;
SG_MUL_VAL_ 2565340800 IdentityNumber VTFunctionECUtoVT 34-34;
SG_MUL_VAL_ 2565340800 FirstWideChar VTFunctionECUtoVT 193-193;
SG_MUL_VAL_ 2565340800 MemoryRequired VTFunctionECUtoVT 192-192;
SG_MUL_VAL_ 2565340800 ObjectIDOfDataMaskToLock VTFunctionECUtoVT 189-189;
SG_MUL_VAL_ 2565340800 DataOrAlarmMaskObjectID VTFunctionECUtoVT 174-174;
SG_MUL_VAL_ 2565340800 Frequency_Audio VTFunctionECUtoVT 163-163;
SG_MUL_VAL_ 2565340800 ButtonObjectID VTFunctionECUtoVT 1-1;
SG_MUL_VAL_ 2565340800 KeyObjectID VTFunctionECUtoVT 0-0;
SG_MUL_VAL_ 2565340800 WSMaintenanceVersion VTFunctionECUtoVT 255-255;
SG_MUL_VAL_ 2565340800 AuxiliaryInputNumber VTFunctionECUtoVT 32-32;
SG_MUL_VAL_ 2565340800 ExtendedVersionLabelToDelete VTFunctionECUtoVT 214-214;
SG_MUL_VAL_ 2565340800 ExtendedVersionLabelToLoad VTFunctionECUtoVT 213-213;
SG_MUL_VAL_ 2565340800 ExtendedVersionLabelToStore VTFunctionECUtoVT 212-212;
SG_MUL_VAL_ 2565340800 MacroObjectID_2 VTFunctionECUtoVT 188-188;
SG_MUL_VAL_ 2565340800 AuxCapabilitiesRequestType VTFunctionECUtoVT 39-39;
SG_MUL_VAL_ 2565340800 WSMaintenanceInitiating WSMaintenanceVersion 3-254;
SG_MUL_VAL_ 2565340800 VersionLabelToDelete VTFunctionECUtoVT 210-210;
SG_MUL_VAL_ 2565340800 VersionLabelToLoad VTFunctionECUtoVT 209-209;
SG_MUL_VAL_ 2565340800 VersionLabelToStore VTFunctionECUtoVT 208-208;
SG_MUL_VAL_ 2565340800 CodePlane VTFunctionECUtoVT 193-193;
SG_MUL_VAL_ 2565340800 MacroObjectID VTFunctionECUtoVT 190-190;
SG_MUL_VAL_ 2565340800 LockUnlockCommand VTFunctionECUtoVT 189-189;
SG_MUL_VAL_ 2565340800 ColourMapObjectID VTFunctionECUtoVT 186-186;
SG_MUL_VAL_ 2565340800 ObjectToGetAttributeID VTFunctionECUtoVT 185-185;
SG_MUL_VAL_ 2565340800 GraphicsContextObjectID VTFunctionECUtoVT 184-184;
SG_MUL_VAL_ 2565340800 PolygonObjectToScaleID VTFunctionECUtoVT 183-183;
SG_MUL_VAL_ 2565340800 PolygonObjectToChangeID VTFunctionECUtoVT 182-182;
SG_MUL_VAL_ 2565340800 ObjectToAssociateLabelWithID VTFunctionECUtoVT 181-181;
SG_MUL_VAL_ 2565340800 ParentObjectID VTFunctionECUtoVT 8-8;
SG_MUL_VAL_ 2565340800 ObjectToChangeStringValueID VTFunctionECUtoVT 179-179;
SG_MUL_VAL_ 2565340800 ListInputObjectID VTFunctionECUtoVT 177-177;
SG_MUL_VAL_ 2565340800 AlarmMaskObjectID VTFunctionECUtoVT 176-176;
SG_MUL_VAL_ 2565340800 ObjectToChangeAttributeID VTFunctionECUtoVT 175-175;
SG_MUL_VAL_ 2565340800 MaskType VTFunctionECUtoVT 174-174;
SG_MUL_VAL_ 2565340800 WorkingSetObjectID VTFunctionECUtoVT 173-173;
SG_MUL_VAL_ 2565340800 ObjectToChangeFillAttributesID VTFunctionECUtoVT 172-172;
SG_MUL_VAL_ 2565340800 ObjectToChangeLineAttributesID VTFunctionECUtoVT 171-171;
SG_MUL_VAL_ 2565340800 ObjectToChangeFontID VTFunctionECUtoVT 170-170;
SG_MUL_VAL_ 2565340800 ObjectToChangeEndPointID VTFunctionECUtoVT 169-169;
SG_MUL_VAL_ 2565340800 ObjectToChangeNumValueID VTFunctionECUtoVT 168-168;
SG_MUL_VAL_ 2565340800 ObjectToChangeColourID VTFunctionECUtoVT 167-167;
SG_MUL_VAL_ 2565340800 ObjectToSizeID VTFunctionECUtoVT 166-166;
SG_MUL_VAL_ 2565340800 ChangeChildLocationParentOb_0000 VTFunctionECUtoVT 165-165;
SG_MUL_VAL_ 2565340800 AudioVolume VTFunctionECUtoVT 164-164;
SG_MUL_VAL_ 2565340800 NumberOfRepetitions_Audio VTFunctionECUtoVT 163-163;
SG_MUL_VAL_ 2565340800 SelectInputObjectID VTFunctionECUtoVT 162-162;
SG_MUL_VAL_ 2565340800 ObjectoEnableDisbaleID VTFunctionECUtoVT 161-161;
SG_MUL_VAL_ 2565340800 ObjectToShowHideID VTFunctionECUtoVT 160-160;
SG_MUL_VAL_ 2565340800 InputStatusObjectId VTFunctionECUtoVT 37-37;
SG_MUL_VAL_ 2565340800 AuxModelIdentification VTFunctionECUtoVT 35-35;
SG_MUL_VAL_ 2565340800 NumberOfInpuUnits VTFunctionECUtoVT 34-34;
SG_MUL_VAL_ 2565340800 AuxiliaryFunctionObjectID VTFunctionECUtoVT 36-36;
SG_MUL_VAL_ 2565340800 ObjectPoolRecord VTFunctionECUtoVT 17-17;
SG_MUL_VAL_ 2565340800 ChangeChildPositionParentOb_0000 VTFunctionECUtoVT 180-180;
SG_MUL_VAL_ 2565340800 VTChangeSoftKeyMaskParentID VTFunctionECUtoVT 7-7;
SG_MUL_VAL_ 2565340800 VTChangeActiveMaskObjectID VTFunctionECUtoVT 6-6;
SG_MUL_VAL_ 2565340800 VTChangeNumericValueObjectID VTFunctionECUtoVT 5-5;
SG_MUL_VAL_ 2565340800 VTEscObjectID VTFunctionECUtoVT 4-4;
SG_MUL_VAL_ 2565340800 VTSelectInputObjectID VTFunctionECUtoVT 3-3;
SG_MUL_VAL_ 2565340800 XPosition VTFunctionECUtoVT 2-2;
SG_MUL_VAL_ 2565340800 ButtonActivationCode VTFunctionECUtoVT 1-1;
SG_MUL_VAL_ 2565340800 KeyActivationCode VTFunctionECUtoVT 0-0;
SG_MUL_VAL_ 2565340800 InputObjectId VTFunctionECUtoVT 33-33;
SG_MUL_VAL_ 2565340800 SourceAddressOfAuxiliaryInputDev VTFunctionECUtoVT 32-32;
SG_MUL_VAL_ 2565340800 ObjectId_1 VTFunctionECUtoVT 9-9;
